VERSION ""

NS_ :

BS_:

BU_: Engine2 Aftertreatment_1_GasOutlet BrakesSystemController Transmission1 Engine1

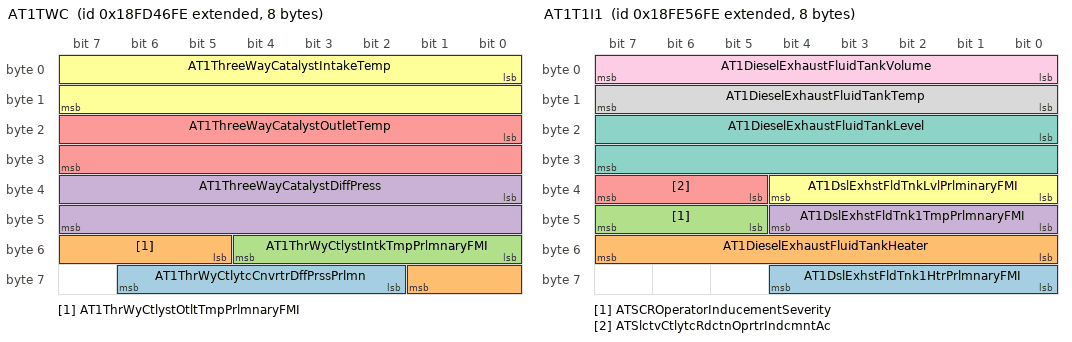
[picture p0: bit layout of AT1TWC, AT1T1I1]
BO_ 2566735614 AT1TWC: 8 Vector__XXX
 SG_ AT1ThrWyCtlytcCnvrtrDffPrssPrlmn : 58|5@1+ (1,0) [0|31] "" Vector__XXX
 SG_ AT1ThrWyCtlystOtltTmpPrlmnaryFMI : 53|5@1+ (1,0) [0|31] "" Vector__XXX
 SG_ AT1ThrWyCtlystIntkTmpPrlmnaryFMI : 48|5@1+ (1,0) [0|31] "" Vector__XXX
 SG_ AT1ThreeWayCatalystDiffPress : 32|16@1+ (0.1,0) [0|6425.5] "kPa" Vector__XXX
 SG_ AT1ThreeWayCatalystOutletTemp : 16|16@1+ (0.03125,-273) [-273|1734.96875] "°C" Vector__XXX
 SG_ AT1ThreeWayCatalystIntakeTemp : 0|16@1+ (0.03125,-273) [-273|1734.96875] "°C" Vector__XXX

BO_ 2566805246 AT1T1I1: 8 Vector__XXX
 SG_ AT1DslExhstFldTnk1HtrPrlmnaryFMI : 56|5@1+ (1,0) [0|31] "" Vector__XXX
 SG_ AT1DieselExhaustFluidTankHeater : 48|8@1+ (0.4,0) [0|100] "%" Vector__XXX
 SG_ ATSCROperatorInducementSeverity : 45|3@1+ (1,0) [0|7] "" Vector__XXX
 SG_ AT1DslExhstFldTnk1TmpPrlmnaryFMI : 40|5@1+ (1,0) [0|31] "" Vector__XXX
 SG_ ATSlctvCtlytcRdctnOprtrIndcmntAc : 37|3@1+ (1,0) [0|7] "" Vector__XXX
 SG_ AT1DslExhstFldTnkLvlPrlminaryFMI : 32|5@1+ (1,0) [0|31] "" Vector__XXX
 SG_ AT1DieselExhaustFluidTankLevel : 16|16@1+ (0.1,0) [0|6425.5] "mm" Vector__XXX
 SG_ AT1DieselExhaustFluidTankTemp : 8|8@1+ (1,-40) [-40|210] "°C" Vector__XXX
 SG_ AT1DieselExhaustFluidTankVolume : 0|8@1+ (0.4,0) [0|100] "%" Vector__XXX

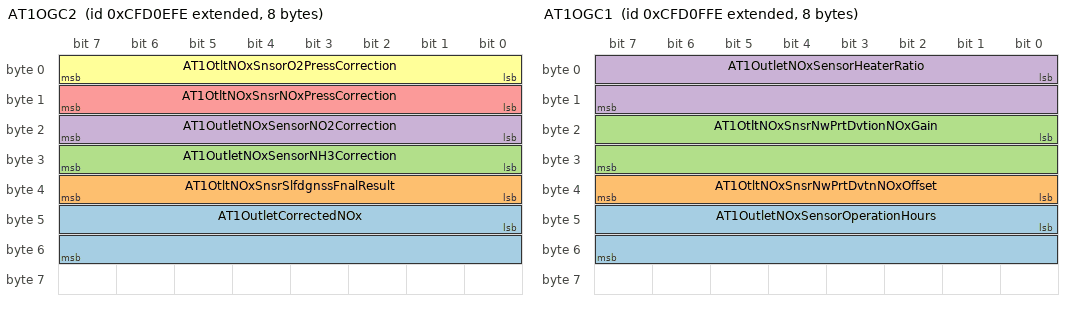
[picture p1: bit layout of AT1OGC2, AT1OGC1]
BO_ 2365394686 AT1OGC2: 8 Vector__XXX
 SG_ AT1OutletCorrectedNOx : 40|16@1+ (0.05,-200) [-200|3012.75] "ppm" Vector__XXX
 SG_ AT1OtltNOxSnsrSlfdgnssFnalResult : 32|8@1+ (1,0) [0|250] "" Vector__XXX
 SG_ AT1OutletNOxSensorNH3Correction : 24|8@1+ (0.5,0) [0|125] "%" Vector__XXX
 SG_ AT1OutletNOxSensorNO2Correction : 16|8@1+ (0.5,0) [0|125] "%" Vector__XXX
 SG_ AT1OtltNOxSnsrNOxPressCorrection : 8|8@1+ (0.5,0) [0|125] "%/bar" Vector__XXX
 SG_ AT1OtltNOxSnsorO2PressCorrection : 0|8@1+ (0.5,0) [0|125] "%/bar" Vector__XXX

BO_ 2365394942 AT1OGC1: 8 Vector__XXX
 SG_ AT1OutletNOxSensorOperationHours : 40|16@1+ (1,0) [0|64255] "h" Vector__XXX
 SG_ AT1OtltNOxSnsrNwPrtDvtnNOxOffset : 32|8@1+ (1,-125) [-125|125] "ppm" Vector__XXX
 SG_ AT1OtltNOxSnsrNwPrtDvtionNOxGain : 16|16@1+ (0.1,-100) [-100|100] "%" Vector__XXX
 SG_ AT1OutletNOxSensorHeaterRatio : 0|16@1+ (0.001,0) [0|64.255] "" Vector__XXX

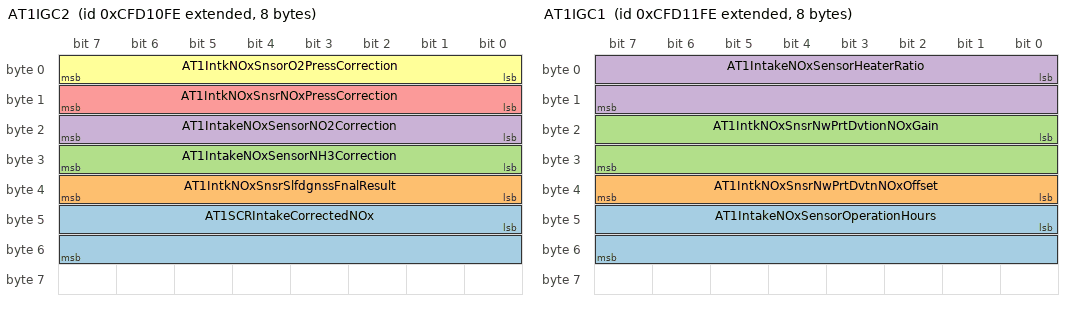
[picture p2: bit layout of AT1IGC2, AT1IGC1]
BO_ 2365395198 AT1IGC2: 8 Vector__XXX
 SG_ AT1SCRIntakeCorrectedNOx : 40|16@1+ (0.05,-200) [-200|3012.75] "ppm" Vector__XXX
 SG_ AT1IntkNOxSnsrSlfdgnssFnalResult : 32|8@1+ (1,0) [0|250] "" Vector__XXX
 SG_ AT1IntakeNOxSensorNH3Correction : 24|8@1+ (0.5,0) [0|125] "%" Vector__XXX
 SG_ AT1IntakeNOxSensorNO2Correction : 16|8@1+ (0.5,0) [0|125] "%" Vector__XXX
 SG_ AT1IntkNOxSnsrNOxPressCorrection : 8|8@1+ (0.5,0) [0|125] "%/bar" Vector__XXX
 SG_ AT1IntkNOxSnsorO2PressCorrection : 0|8@1+ (0.5,0) [0|125] "%/bar" Vector__XXX

BO_ 2365395454 AT1IGC1: 8 Vector__XXX
 SG_ AT1IntakeNOxSensorOperationHours : 40|16@1+ (1,0) [0|64255] "h" Vector__XXX
 SG_ AT1IntkNOxSnsrNwPrtDvtnNOxOffset : 32|8@1+ (1,-125) [-125|125] "ppm" Vector__XXX
 SG_ AT1IntkNOxSnsrNwPrtDvtionNOxGain : 16|16@1+ (0.1,-100) [-100|100] "%" Vector__XXX
 SG_ AT1IntakeNOxSensorHeaterRatio : 0|16@1+ (0.001,0) [0|64.255] "" Vector__XXX

BO_ 2157248254 AT1DPFSSC: 8 Vector__XXX
 SG_ AT1DslPrtcltFltrStStndrdDvtnClbO : 16|16@1+ (0.0025,0) [0|160.6375] "%" Vector__XXX
 SG_ AT1DslPrtcltFltrStManCalibOffset : 0|16@1+ (0.0025,0) [0|160.6375] "%" Vector__XXX

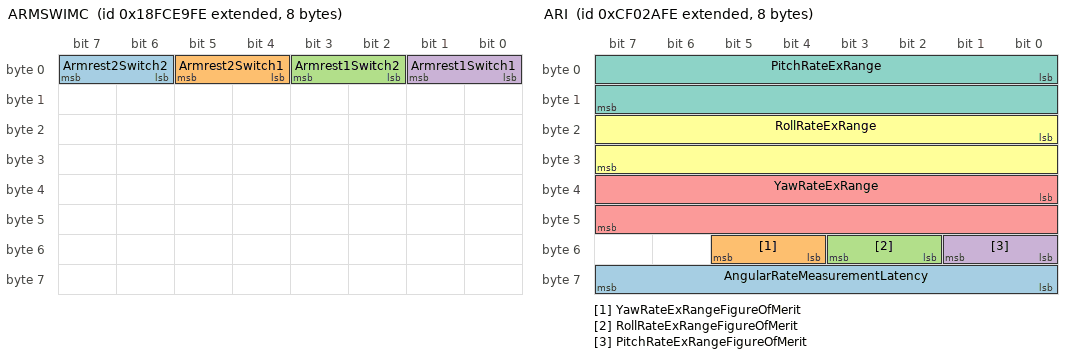
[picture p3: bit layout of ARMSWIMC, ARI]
BO_ 2566711806 ARMSWIMC: 8 Vector__XXX
 SG_ Armrest2Switch2 : 6|2@1+ (1,0) [0|3] "" Vector__XXX
 SG_ Armrest2Switch1 : 4|2@1+ (1,0) [0|3] "" Vector__XXX
 SG_ Armrest1Switch2 : 2|2@1+ (1,0) [0|3] "" Vector__XXX
 SG_ Armrest1Switch1 : 0|2@1+ (1,0) [0|3] "" Vector__XXX

BO_ 2364549886 ARI: 8 Vector__XXX
 SG_ AngularRateMeasurementLatency : 56|8@1+ (0.5,0) [0|125] "ms" Vector__XXX
 SG_ YawRateExRangeFigureOfMerit : 52|2@1+ (1,0) [0|3] "" Vector__XXX
 SG_ RollRateExRangeFigureOfMerit : 50|2@1+ (1,0) [0|3] "" Vector__XXX
 SG_ PitchRateExRangeFigureOfMerit : 48|2@1+ (1,0) [0|3] "" Vector__XXX
 SG_ YawRateExRange : 32|16@1+ (0.0078125,-250) [-250|250.992] "deg/s" Vector__XXX
 SG_ RollRateExRange : 16|16@1+ (0.0078125,-250) [-250|250.992] "deg/s" Vector__XXX
 SG_ PitchRateExRange : 0|16@1+ (0.0078125,-250) [-250|250.992] "deg/s" Vector__XXX

BO_ 2566712318 AFT2NAI: 8 Vector__XXX
 SG_ AT2NOxAdsorberDesulfationStatus : 2|2@1+ (1,0) [0|3] "" Vector__XXX
 SG_ AT2NOxAdsorberRegenerationStatus : 0|2@1+ (1,0) [0|3] "" Vector__XXX

BO_ 2566712574 AFT1NAI: 8 Vector__XXX
 SG_ AT1NOxAdsorberDesulfationStatus : 2|2@1+ (1,0) [0|3] "" Vector__XXX
 SG_ AT1NOxAdsorberRegenerationStatus : 0|2@1+ (1,0) [0|3] "" Vector__XXX

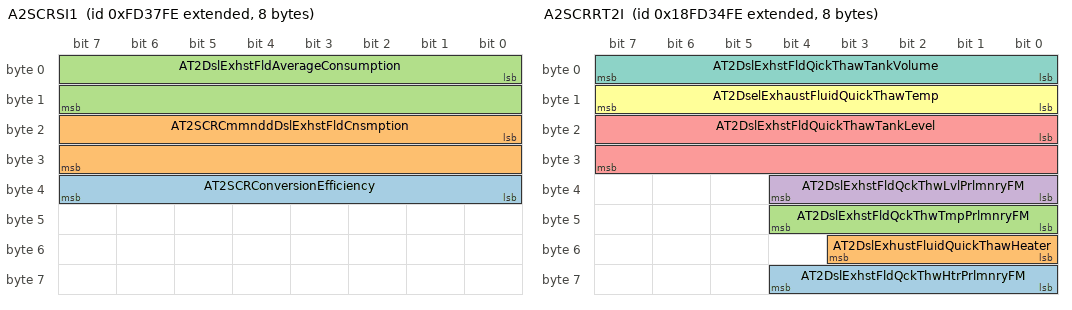
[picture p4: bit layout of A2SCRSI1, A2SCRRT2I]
BO_ 2164078590 A2SCRSI1: 8 Vector__XXX
 SG_ AT2SCRConversionEfficiency : 32|8@1+ (0.4,0) [0|100] "%" Vector__XXX
 SG_ AT2SCRCmmnddDslExhstFldCnsmption : 16|16@1+ (0.05,0) [0|3212.75] "L/h" Vector__XXX
 SG_ AT2DslExhstFldAverageConsumption : 0|16@1+ (0.05,0) [0|3212.75] "L/h" Vector__XXX

BO_ 2566731006 A2SCRRT2I: 8 Vector__XXX
 SG_ AT2DslExhstFldQckThwHtrPrlmnryFM : 56|5@1+ (1,0) [0|31] "" Vector__XXX
 SG_ AT2DslExhustFluidQuickThawHeater : 48|4@1+ (1,0) [0|15] "" Vector__XXX
 SG_ AT2DslExhstFldQckThwTmpPrlmnryFM : 40|5@1+ (1,0) [0|31] "" Vector__XXX
 SG_ AT2DslExhstFldQckThwLvlPrlmnryFM : 32|5@1+ (1,0) [0|31] "" Vector__XXX
 SG_ AT2DslExhstFldQuickThawTankLevel : 16|16@1+ (0.1,0) [0|6425.5] "mm" Vector__XXX
 SG_ AT2DselExhaustFluidQuickThawTemp : 8|8@1+ (1,-40) [-40|210] "°C" Vector__XXX
 SG_ AT2DslExhstFldQickThawTankVolume : 0|8@1+ (0.4,0) [0|100] "%" Vector__XXX

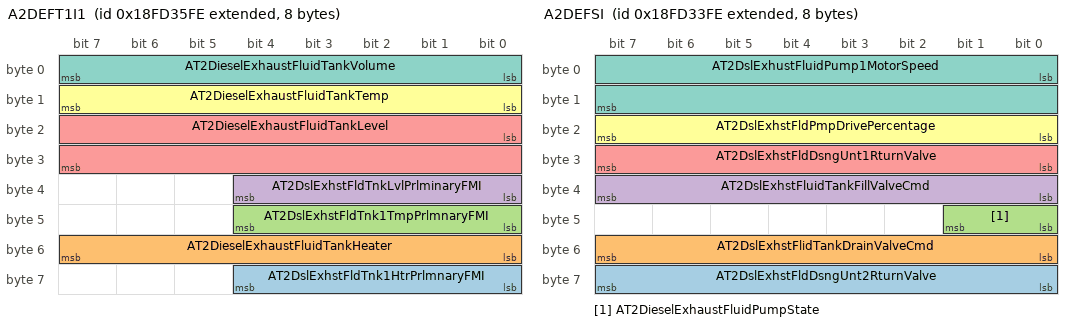
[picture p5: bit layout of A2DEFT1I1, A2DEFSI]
BO_ 2566731262 A2DEFT1I1: 8 Vector__XXX
 SG_ AT2DslExhstFldTnk1HtrPrlmnaryFMI : 56|5@1+ (1,0) [0|31] "" Vector__XXX
 SG_ AT2DieselExhaustFluidTankHeater : 48|8@1+ (0.4,0) [0|100] "%" Vector__XXX
 SG_ AT2DslExhstFldTnk1TmpPrlmnaryFMI : 40|5@1+ (1,0) [0|31] "" Vector__XXX
 SG_ AT2DslExhstFldTnkLvlPrlminaryFMI : 32|5@1+ (1,0) [0|31] "" Vector__XXX
 SG_ AT2DieselExhaustFluidTankLevel : 16|16@1+ (0.1,0) [0|6425.5] "mm" Vector__XXX
 SG_ AT2DieselExhaustFluidTankTemp : 8|8@1+ (1,-40) [-40|210] "°C" Vector__XXX
 SG_ AT2DieselExhaustFluidTankVolume : 0|8@1+ (0.4,0) [0|100] "%" Vector__XXX

BO_ 2566730750 A2DEFSI: 8 Vector__XXX
 SG_ AT2DslExhstFldDsngUnt2RturnValve : 56|8@1+ (0.4,0) [0|100] "%" Vector__XXX
 SG_ AT2DslExhstFlidTankDrainValveCmd : 48|8@1+ (0.4,0) [0|100] "%" Vector__XXX
 SG_ AT2DieselExhaustFluidPumpState : 40|2@1+ (1,0) [0|3] "" Vector__XXX
 SG_ AT2DslExhstFluidTankFillValveCmd : 32|8@1+ (0.4,0) [0|100] "%" Vector__XXX
 SG_ AT2DslExhstFldDsngUnt1RturnValve : 24|8@1+ (0.4,0) [0|100] "%" Vector__XXX
 SG_ AT2DslExhstFldPmpDrivePercentage : 16|8@1+ (0.4,0) [0|100] "%" Vector__XXX
 SG_ AT2DslExhustFluidPump1MotorSpeed : 0|16@1+ (0.5,0) [0|32127.5] "rpm" Vector__XXX

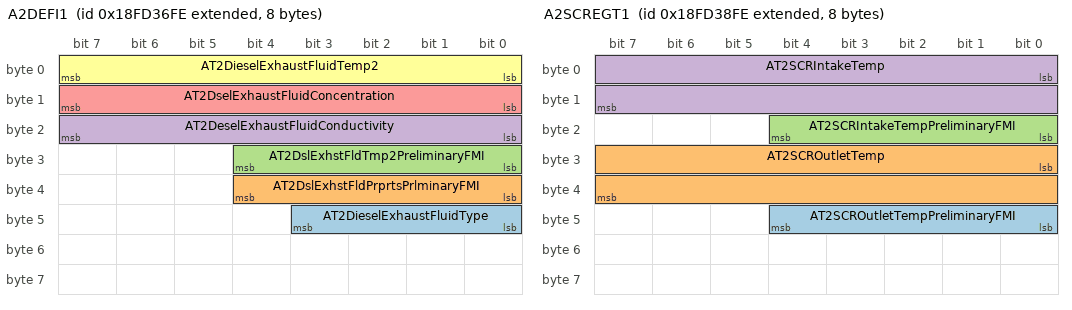
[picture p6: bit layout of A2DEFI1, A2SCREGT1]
BO_ 2566731518 A2DEFI1: 8 Vector__XXX
 SG_ AT2DieselExhaustFluidType : 40|4@1+ (1,0) [0|15] "" Vector__XXX
 SG_ AT2DslExhstFldPrprtsPrlminaryFMI : 32|5@1+ (1,0) [0|31] "" Vector__XXX
 SG_ AT2DslExhstFldTmp2PreliminaryFMI : 24|5@1+ (1,0) [0|31] "" Vector__XXX
 SG_ AT2DeselExhaustFluidConductivity : 16|8@1+ (5,0) [0|1250] "µSiemens/mm" Vector__XXX
 SG_ AT2DselExhaustFluidConcentration : 8|8@1+ (0.25,0) [0|62.5] "%" Vector__XXX
 SG_ AT2DieselExhaustFluidTemp2 : 0|8@1+ (1,-40) [-40|210] "°C" Vector__XXX

BO_ 2566732030 A2SCREGT1: 8 Vector__XXX
 SG_ AT2SCROutletTempPreliminaryFMI : 40|5@1+ (1,0) [0|31] "" Vector__XXX
 SG_ AT2SCROutletTemp : 24|16@1+ (0.03125,-273) [-273|1734.96875] "°C" Vector__XXX
 SG_ AT2SCRIntakeTempPreliminaryFMI : 16|5@1+ (1,0) [0|31] "" Vector__XXX
 SG_ AT2SCRIntakeTemp : 0|16@1+ (0.03125,-273) [-273|1734.96875] "°C" Vector__XXX

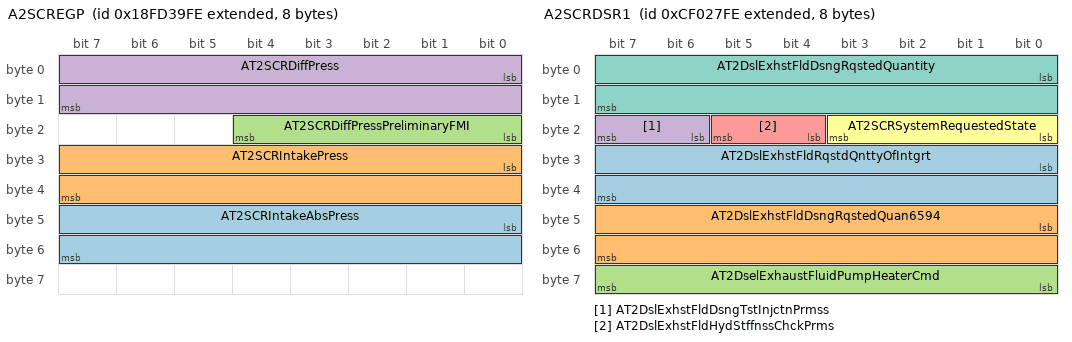
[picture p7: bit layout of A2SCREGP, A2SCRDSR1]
BO_ 2566732286 A2SCREGP: 8 Vector__XXX
 SG_ AT2SCRIntakeAbsPress : 40|16@1+ (0.1,0) [0|6425.5] "kPa" Vector__XXX
 SG_ AT2SCRIntakePress : 24|16@1+ (0.1,-3212.7) [-3212.7|3212.8] "kPa" Vector__XXX
 SG_ AT2SCRDiffPressPreliminaryFMI : 16|5@1+ (1,0) [0|31] "" Vector__XXX
 SG_ AT2SCRDiffPress : 0|16@1+ (0.1,0) [0|6425.5] "kPa" Vector__XXX

BO_ 2164079358 A2SCRDSR2: 8 Vector__XXX
 SG_ AT2DeselExhaustFluidLineHeater10 : 48|2@1+ (1,0) [0|3] "" Vector__XXX
 SG_ AT2DieselExhaustFluidLineHeater9 : 46|2@1+ (1,0) [0|3] "" Vector__XXX
 SG_ AT2DieselExhaustFluidLineHeater8 : 44|2@1+ (1,0) [0|3] "" Vector__XXX
 SG_ AT2DieselExhaustFluidLineHeater7 : 42|2@1+ (1,0) [0|3] "" Vector__XXX
 SG_ AT2DieselExhaustFluidLineHeater6 : 40|2@1+ (1,0) [0|3] "" Vector__XXX
 SG_ AT2DieselExhaustFluidLineHeater5 : 38|2@1+ (1,0) [0|3] "" Vector__XXX
 SG_ AT2DslExhstFluidLineHeaterRelay3 : 36|2@1+ (1,0) [0|3] "" Vector__XXX
 SG_ AT2DslExhstFluidLineHeaterRelay2 : 34|2@1+ (1,0) [0|3] "" Vector__XXX
 SG_ AT2DslExhstFluidLineHeaterRelay1 : 32|2@1+ (1,0) [0|3] "" Vector__XXX
 SG_ AT2DslExhstFldQuickThawHeaterCmd : 24|8@1+ (0.4,0) [0|100] "%" Vector__XXX
 SG_ AT2DselExhaustFluidTankHeaterCmd : 16|8@1+ (0.4,0) [0|100] "%" Vector__XXX
 SG_ AT2DieselExhaustFluidLineHeater4 : 14|2@1+ (1,0) [0|3] "" Vector__XXX
 SG_ AT2DieselExhaustFluidLineHeater3 : 12|2@1+ (1,0) [0|3] "" Vector__XXX
 SG_ AT2DieselExhaustFluidLineHeater2 : 10|2@1+ (1,0) [0|3] "" Vector__XXX
 SG_ AT2DieselExhaustFluidLineHeater1 : 8|2@1+ (1,0) [0|3] "" Vector__XXX
 SG_ AT2DslExhstFldDoserHeatingModeRq : 4|3@1+ (1,0) [0|7] "" Vector__XXX
 SG_ AT2DslExhstFldDsrFltSppressionRq : 2|2@1+ (1,0) [0|3] "" Vector__XXX

BO_ 2364549118 A2SCRDSR1: 8 Vector__XXX
 SG_ AT2DslExhstFldRqstdQnttyOfIntgrt : 24|16@1+ (0.1,0) [0|6425.5] "g" Vector__XXX
 SG_ AT2DslExhstFldDsngRqstedQuan6594 : 40|16@1+ (0.05,0) [0|3212.75] "g/min" Vector__XXX
 SG_ AT2DselExhaustFluidPumpHeaterCmd : 56|8@1+ (0.4,0) [0|100] "%" Vector__XXX
 SG_ AT2DslExhstFldDsngTstInjctnPrmss : 22|2@1+ (1,0) [0|3] "" Vector__XXX
 SG_ AT2DslExhstFldHydStffnssChckPrms : 20|2@1+ (1,0) [0|3] "" Vector__XXX
 SG_ AT2SCRSystemRequestedState : 16|4@1+ (1,0) [0|15] "" Vector__XXX
 SG_ AT2DslExhstFldDsngRqstedQuantity : 0|16@1+ (0.3,0) [0|19276.5] "g/h" Vector__XXX

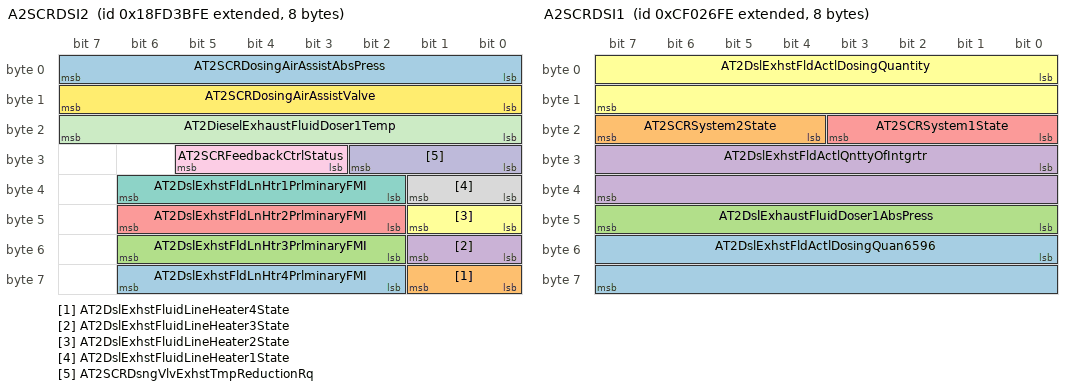
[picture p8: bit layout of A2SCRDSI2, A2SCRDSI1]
BO_ 2566732798 A2SCRDSI2: 8 Vector__XXX
 SG_ AT2DslExhstFldLnHtr4PrlminaryFMI : 58|5@1+ (1,0) [0|31] "" Vector__XXX
 SG_ AT2DslExhstFluidLineHeater4State : 56|2@1+ (1,0) [0|3] "" Vector__XXX
 SG_ AT2DslExhstFldLnHtr3PrlminaryFMI : 50|5@1+ (1,0) [0|31] "" Vector__XXX
 SG_ AT2DslExhstFluidLineHeater3State : 48|2@1+ (1,0) [0|3] "" Vector__XXX
 SG_ AT2DslExhstFldLnHtr2PrlminaryFMI : 42|5@1+ (1,0) [0|31] "" Vector__XXX
 SG_ AT2DslExhstFluidLineHeater2State : 40|2@1+ (1,0) [0|3] "" Vector__XXX
 SG_ AT2DslExhstFldLnHtr1PrlminaryFMI : 34|5@1+ (1,0) [0|31] "" Vector__XXX
 SG_ AT2DslExhstFluidLineHeater1State : 32|2@1+ (1,0) [0|3] "" Vector__XXX
 SG_ AT2SCRFeedbackCtrlStatus : 27|3@1+ (1,0) [0|7] "" Vector__XXX
 SG_ AT2SCRDsngVlvExhstTmpReductionRq : 24|3@1+ (1,0) [0|7] "" Vector__XXX
 SG_ AT2DieselExhaustFluidDoser1Temp : 16|8@1+ (1,-40) [-40|210] "°C" Vector__XXX
 SG_ AT2SCRDosingAirAssistValve : 8|8@1+ (0.4,0) [0|100] "%" Vector__XXX
 SG_ AT2SCRDosingAirAssistAbsPress : 0|8@1+ (8,0) [0|2000] "kPa" Vector__XXX

BO_ 2364548862 A2SCRDSI1: 8 Vector__XXX
 SG_ AT2DslExhstFldActlDosingQuan6596 : 48|16@1+ (0.05,0) [0|3212.75] "g/min" Vector__XXX
 SG_ AT2SCRSystem2State : 20|4@1+ (1,0) [0|15] "" Vector__XXX
 SG_ AT2DslExhaustFluidDoser1AbsPress : 40|8@1+ (8,0) [0|2000] "kPa" Vector__XXX
 SG_ AT2DslExhstFldActlQnttyOfIntgrtr : 24|16@1+ (0.1,0) [0|6425.5] "g" Vector__XXX
 SG_ AT2SCRSystem1State : 16|4@1+ (1,0) [0|15] "" Vector__XXX
 SG_ AT2DslExhstFldActlDosingQuantity : 0|16@1+ (0.3,0) [0|19276.5] "g/h" Vector__XXX

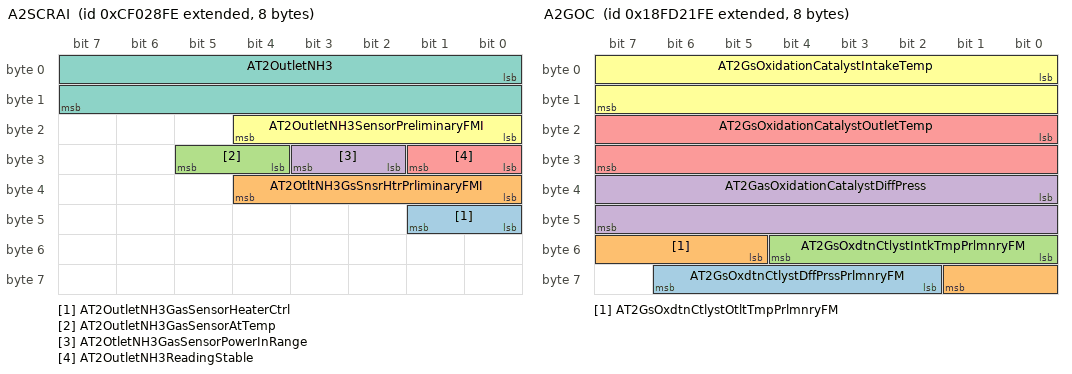
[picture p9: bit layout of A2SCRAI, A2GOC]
BO_ 2364549374 A2SCRAI: 8 Vector__XXX
 SG_ AT2OutletNH3GasSensorHeaterCtrl : 40|2@1+ (1,0) [0|3] "" Vector__XXX
 SG_ AT2OtltNH3GsSnsrHtrPrliminaryFMI : 32|5@1+ (1,0) [0|31] "" Vector__XXX
 SG_ AT2OutletNH3GasSensorAtTemp : 28|2@1+ (1,0) [0|3] "" Vector__XXX
 SG_ AT2OtletNH3GasSensorPowerInRange : 26|2@1+ (1,0) [0|3] "" Vector__XXX
 SG_ AT2OutletNH3ReadingStable : 24|2@1+ (1,0) [0|3] "" Vector__XXX
 SG_ AT2OutletNH3SensorPreliminaryFMI : 16|5@1+ (1,0) [0|31] "" Vector__XXX
 SG_ AT2OutletNH3 : 0|16@1+ (0.05,-200) [-200|3012.75] "ppm" Vector__XXX

BO_ 2566726142 A2GOC: 8 Vector__XXX
 SG_ AT2GsOxdtnCtlystDffPrssPrlmnryFM : 58|5@1+ (1,0) [0|31] "" Vector__XXX
 SG_ AT2GsOxdtnCtlystOtltTmpPrlmnryFM : 53|5@1+ (1,0) [0|31] "" Vector__XXX
 SG_ AT2GsOxdtnCtlystIntkTmpPrlmnryFM : 48|5@1+ (1,0) [0|31] "" Vector__XXX
 SG_ AT2GasOxidationCatalystDiffPress : 32|16@1+ (0.1,0) [0|6425.5] "kPa" Vector__XXX
 SG_ AT2GsOxidationCatalystOutletTemp : 16|16@1+ (0.03125,-273) [-273|1734.96875] "°C" Vector__XXX
 SG_ AT2GsOxidationCatalystIntakeTemp : 0|16@1+ (0.03125,-273) [-273|1734.96875] "°C" Vector__XXX

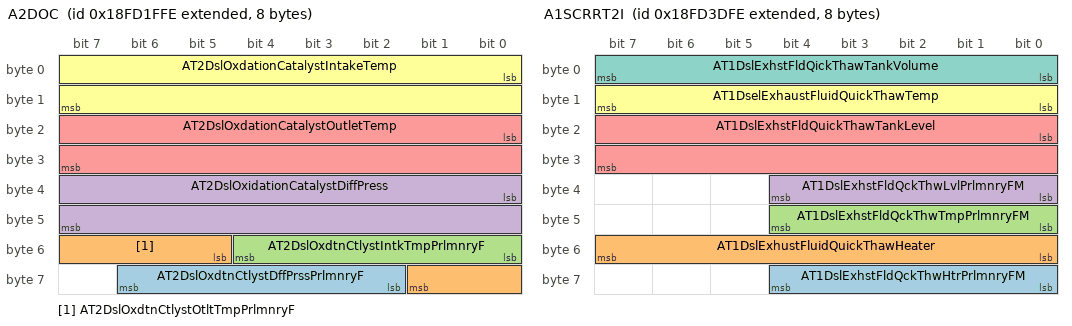
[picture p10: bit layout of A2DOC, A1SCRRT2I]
BO_ 2566725630 A2DOC: 8 Vector__XXX
 SG_ AT2DslOxdtnCtlystDffPrssPrlmnryF : 58|5@1+ (1,0) [0|31] "" Vector__XXX
 SG_ AT2DslOxdtnCtlystOtltTmpPrlmnryF : 53|5@1+ (1,0) [0|31] "" Vector__XXX
 SG_ AT2DslOxdtnCtlystIntkTmpPrlmnryF : 48|5@1+ (1,0) [0|31] "" Vector__XXX
 SG_ AT2DslOxidationCatalystDiffPress : 32|16@1+ (0.5,0) [0|32127.5] "kPa" Vector__XXX
 SG_ AT2DslOxdationCatalystOutletTemp : 16|16@1+ (0.03125,-273) [-273|1734.96875] "°C" Vector__XXX
 SG_ AT2DslOxdationCatalystIntakeTemp : 0|16@1+ (0.03125,-273) [-273|1734.96875] "°C" Vector__XXX

BO_ 2566733310 A1SCRRT2I: 8 Vector__XXX
 SG_ AT1DslExhstFldQckThwHtrPrlmnryFM : 56|5@1+ (1,0) [0|31] "" Vector__XXX
 SG_ AT1DslExhustFluidQuickThawHeater : 48|8@1+ (0.4,0) [0|100] "%" Vector__XXX
 SG_ AT1DslExhstFldQckThwTmpPrlmnryFM : 40|5@1+ (1,0) [0|31] "" Vector__XXX
 SG_ AT1DslExhstFldQckThwLvlPrlmnryFM : 32|5@1+ (1,0) [0|31] "" Vector__XXX
 SG_ AT1DslExhstFldQuickThawTankLevel : 16|16@1+ (0.1,0) [0|6425.5] "mm" Vector__XXX
 SG_ AT1DselExhaustFluidQuickThawTemp : 8|8@1+ (1,-40) [-40|210] "°C" Vector__XXX
 SG_ AT1DslExhstFldQickThawTankVolume : 0|8@1+ (0.4,0) [0|100] "%" Vector__XXX

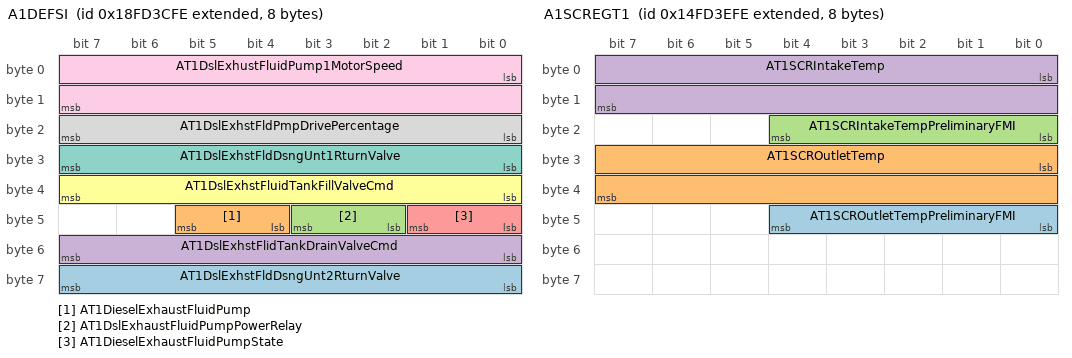
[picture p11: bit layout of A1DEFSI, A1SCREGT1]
BO_ 2566733054 A1DEFSI: 8 Vector__XXX
 SG_ AT1DslExhstFldDsngUnt2RturnValve : 56|8@1+ (0.4,0) [0|100] "%" Vector__XXX
 SG_ AT1DieselExhaustFluidPump : 44|2@1+ (1,0) [0|3] "" Vector__XXX
 SG_ AT1DslExhaustFluidPumpPowerRelay : 42|2@1+ (1,0) [0|3] "" Vector__XXX
 SG_ AT1DslExhstFlidTankDrainValveCmd : 48|8@1+ (0.4,0) [0|100] "%" Vector__XXX
 SG_ AT1DieselExhaustFluidPumpState : 40|2@1+ (1,0) [0|3] "" Vector__XXX
 SG_ AT1DslExhstFluidTankFillValveCmd : 32|8@1+ (0.4,0) [0|100] "%" Vector__XXX
 SG_ AT1DslExhstFldDsngUnt1RturnValve : 24|8@1+ (0.4,0) [0|100] "%" Vector__XXX
 SG_ AT1DslExhstFldPmpDrivePercentage : 16|8@1+ (0.4,0) [0|100] "%" Vector__XXX
 SG_ AT1DslExhustFluidPump1MotorSpeed : 0|16@1+ (0.5,0) [0|32127.5] "rpm" Vector__XXX

BO_ 2499624702 A1SCREGT1: 8 Vector__XXX
 SG_ AT1SCROutletTempPreliminaryFMI : 40|5@1+ (1,0) [0|31] "" Vector__XXX
 SG_ AT1SCROutletTemp : 24|16@1+ (0.03125,-273) [-273|1734.96875] "°C" Vector__XXX
 SG_ AT1SCRIntakeTempPreliminaryFMI : 16|5@1+ (1,0) [0|31] "" Vector__XXX
 SG_ AT1SCRIntakeTemp : 0|16@1+ (0.03125,-273) [-273|1734.96875] "°C" Vector__XXX

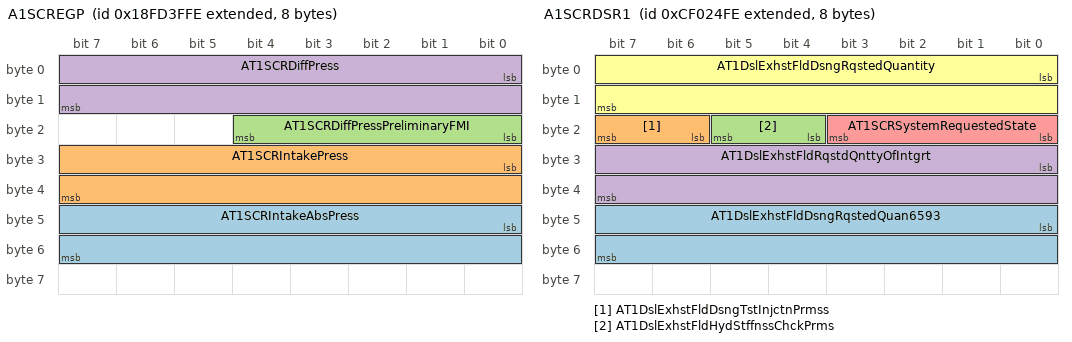
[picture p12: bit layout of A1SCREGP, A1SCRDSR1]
BO_ 2566733822 A1SCREGP: 8 Vector__XXX
 SG_ AT1SCRIntakeAbsPress : 40|16@1+ (0.1,0) [0|6425.5] "kPa" Vector__XXX
 SG_ AT1SCRIntakePress : 24|16@1+ (0.1,-3212.7) [-3212.7|3212.8] "kPa" Vector__XXX
 SG_ AT1SCRDiffPressPreliminaryFMI : 16|5@1+ (1,0) [0|31] "" Vector__XXX
 SG_ AT1SCRDiffPress : 0|16@1+ (0.1,0) [0|6425.5] "kPa" Vector__XXX

BO_ 2566734078 A1SCRDSR2: 8 Vector__XXX
 SG_ AT1DeselExhaustFluidLineHeater10 : 56|2@1+ (1,0) [0|3] "" Vector__XXX
 SG_ AT1DieselExhaustFluidLineHeater9 : 54|2@1+ (1,0) [0|3] "" Vector__XXX
 SG_ AT1DieselExhaustFluidLineHeater8 : 52|2@1+ (1,0) [0|3] "" Vector__XXX
 SG_ AT1DieselExhaustFluidLineHeater7 : 50|2@1+ (1,0) [0|3] "" Vector__XXX
 SG_ AT1DieselExhaustFluidLineHeater6 : 48|2@1+ (1,0) [0|3] "" Vector__XXX
 SG_ AT1DieselExhaustFluidLineHeater5 : 46|2@1+ (1,0) [0|3] "" Vector__XXX
 SG_ AT1DslExhstFluidLineHeaterRelay3 : 44|2@1+ (1,0) [0|3] "" Vector__XXX
 SG_ AT1DslExhstFluidLineHeaterRelay2 : 42|2@1+ (1,0) [0|3] "" Vector__XXX
 SG_ AT1DslExhstFluidLineHeaterRelay1 : 40|2@1+ (1,0) [0|3] "" Vector__XXX
 SG_ AT1DselExhaustFluidPumpHeaterCmd : 32|8@1+ (0.4,0) [0|100] "%" Vector__XXX
 SG_ AT1DslExhstFldQuickThawHeaterCmd : 24|8@1+ (0.4,0) [0|100] "%" Vector__XXX
 SG_ AT1DselExhaustFluidTankHeaterCmd : 16|8@1+ (0.4,0) [0|100] "%" Vector__XXX
 SG_ AT1DieselExhaustFluidLineHeater4 : 14|2@1+ (1,0) [0|3] "" Vector__XXX
 SG_ AT1DieselExhaustFluidLineHeater3 : 12|2@1+ (1,0) [0|3] "" Vector__XXX
 SG_ AT1DieselExhaustFluidLineHeater2 : 10|2@1+ (1,0) [0|3] "" Vector__XXX
 SG_ AT1DieselExhaustFluidLineHeater1 : 8|2@1+ (1,0) [0|3] "" Vector__XXX
 SG_ AT1DslExhstFldDoserHeatingModeRq : 4|3@1+ (1,0) [0|7] "" Vector__XXX
 SG_ AT1DslExhstFldDsrFltSppressionRq : 2|2@1+ (1,0) [0|3] "" Vector__XXX

BO_ 2364548350 A1SCRDSR1: 8 Vector__XXX
 SG_ AT1DslExhstFldDsngRqstedQuan6593 : 40|16@1+ (0.05,0) [0|3212.75] "g/min" Vector__XXX
 SG_ AT1DslExhstFldDsngTstInjctnPrmss : 22|2@1+ (1,0) [0|3] "" Vector__XXX
 SG_ AT1DslExhstFldHydStffnssChckPrms : 20|2@1+ (1,0) [0|3] "" Vector__XXX
 SG_ AT1DslExhstFldRqstdQnttyOfIntgrt : 24|16@1+ (0.1,0) [0|6425.5] "g" Vector__XXX
 SG_ AT1SCRSystemRequestedState : 16|4@1+ (1,0) [0|15] "" Vector__XXX
 SG_ AT1DslExhstFldDsngRqstedQuantity : 0|16@1+ (0.3,0) [0|19276.5] "g/h" Vector__XXX

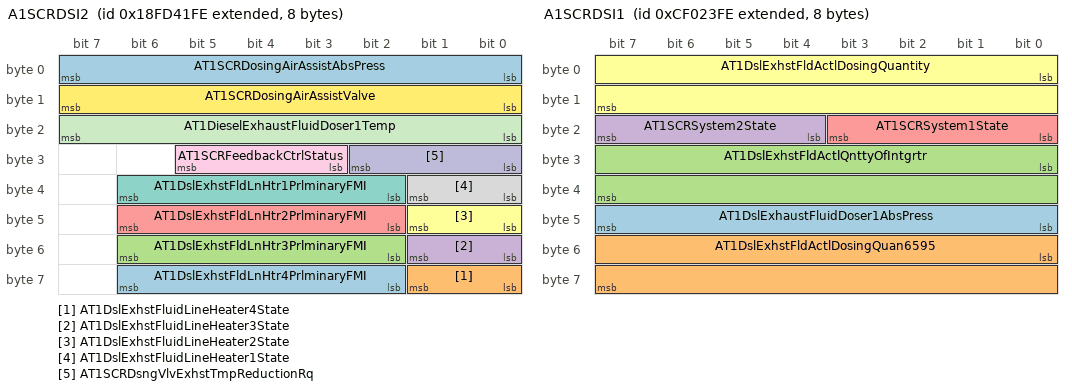
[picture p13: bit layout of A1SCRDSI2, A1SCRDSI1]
BO_ 2566734334 A1SCRDSI2: 8 Vector__XXX
 SG_ AT1DslExhstFldLnHtr4PrlminaryFMI : 58|5@1+ (1,0) [0|31] "" Vector__XXX
 SG_ AT1DslExhstFluidLineHeater4State : 56|2@1+ (1,0) [0|3] "" Vector__XXX
 SG_ AT1DslExhstFldLnHtr3PrlminaryFMI : 50|5@1+ (1,0) [0|31] "" Vector__XXX
 SG_ AT1DslExhstFluidLineHeater3State : 48|2@1+ (1,0) [0|3] "" Vector__XXX
 SG_ AT1DslExhstFldLnHtr2PrlminaryFMI : 42|5@1+ (1,0) [0|31] "" Vector__XXX
 SG_ AT1DslExhstFluidLineHeater2State : 40|2@1+ (1,0) [0|3] "" Vector__XXX
 SG_ AT1DslExhstFldLnHtr1PrlminaryFMI : 34|5@1+ (1,0) [0|31] "" Vector__XXX
 SG_ AT1DslExhstFluidLineHeater1State : 32|2@1+ (1,0) [0|3] "" Vector__XXX
 SG_ AT1SCRFeedbackCtrlStatus : 27|3@1+ (1,0) [0|7] "" Vector__XXX
 SG_ AT1SCRDsngVlvExhstTmpReductionRq : 24|3@1+ (1,0) [0|7] "" Vector__XXX
 SG_ AT1DieselExhaustFluidDoser1Temp : 16|8@1+ (1,-40) [-40|210] "°C" Vector__XXX
 SG_ AT1SCRDosingAirAssistValve : 8|8@1+ (0.4,0) [0|100] "%" Vector__XXX
 SG_ AT1SCRDosingAirAssistAbsPress : 0|8@1+ (8,0) [0|2000] "kPa" Vector__XXX

BO_ 2364548094 A1SCRDSI1: 8 Vector__XXX
 SG_ AT1DslExhaustFluidDoser1AbsPress : 40|8@1+ (8,0) [0|2000] "kPa" Vector__XXX
 SG_ AT1DslExhstFldActlDosingQuan6595 : 48|16@1+ (0.05,0) [0|3212.75] "g/min" Vector__XXX
 SG_ AT1DslExhstFldActlQnttyOfIntgrtr : 24|16@1+ (0.1,0) [0|6425.5] "g" Vector__XXX
 SG_ AT1SCRSystem2State : 20|4@1+ (1,0) [0|15] "" Vector__XXX
 SG_ AT1SCRSystem1State : 16|4@1+ (1,0) [0|15] "" Vector__XXX
 SG_ AT1DslExhstFldActlDosingQuantity : 0|16@1+ (0.3,0) [0|19276.5] "g/h" Vector__XXX

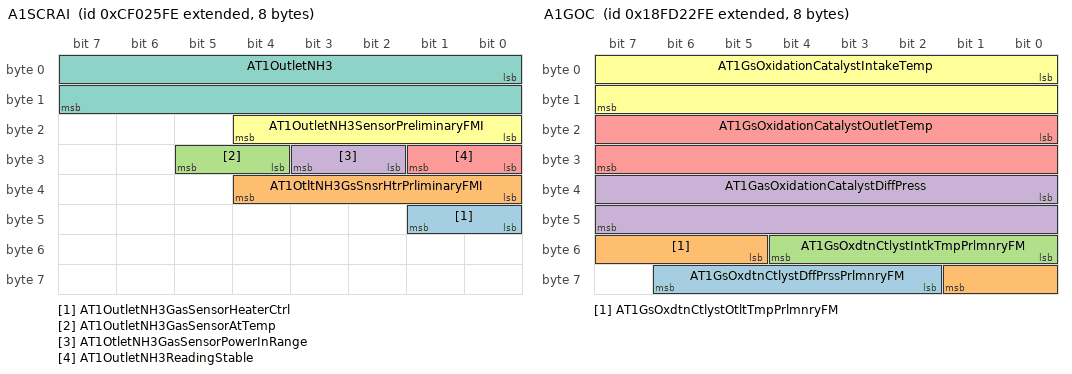
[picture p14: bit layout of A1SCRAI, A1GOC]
BO_ 2364548606 A1SCRAI: 8 Vector__XXX
 SG_ AT1OutletNH3GasSensorHeaterCtrl : 40|2@1+ (1,0) [0|3] "" Vector__XXX
 SG_ AT1OtltNH3GsSnsrHtrPrliminaryFMI : 32|5@1+ (1,0) [0|31] "" Vector__XXX
 SG_ AT1OutletNH3GasSensorAtTemp : 28|2@1+ (1,0) [0|3] "" Vector__XXX
 SG_ AT1OtletNH3GasSensorPowerInRange : 26|2@1+ (1,0) [0|3] "" Vector__XXX
 SG_ AT1OutletNH3ReadingStable : 24|2@1+ (1,0) [0|3] "" Vector__XXX
 SG_ AT1OutletNH3SensorPreliminaryFMI : 16|5@1+ (1,0) [0|31] "" Vector__XXX
 SG_ AT1OutletNH3 : 0|16@1+ (0.05,-200) [-200|3012.75] "ppm" Vector__XXX

BO_ 2566726398 A1GOC: 8 Vector__XXX
 SG_ AT1GsOxdtnCtlystDffPrssPrlmnryFM : 58|5@1+ (1,0) [0|31] "" Vector__XXX
 SG_ AT1GsOxdtnCtlystOtltTmpPrlmnryFM : 53|5@1+ (1,0) [0|31] "" Vector__XXX
 SG_ AT1GsOxdtnCtlystIntkTmpPrlmnryFM : 48|5@1+ (1,0) [0|31] "" Vector__XXX
 SG_ AT1GasOxidationCatalystDiffPress : 32|16@1+ (0.1,0) [0|6425.5] "kPa" Vector__XXX
 SG_ AT1GsOxidationCatalystOutletTemp : 16|16@1+ (0.03125,-273) [-273|1734.96875] "°C" Vector__XXX
 SG_ AT1GsOxidationCatalystIntakeTemp : 0|16@1+ (0.03125,-273) [-273|1734.96875] "°C" Vector__XXX

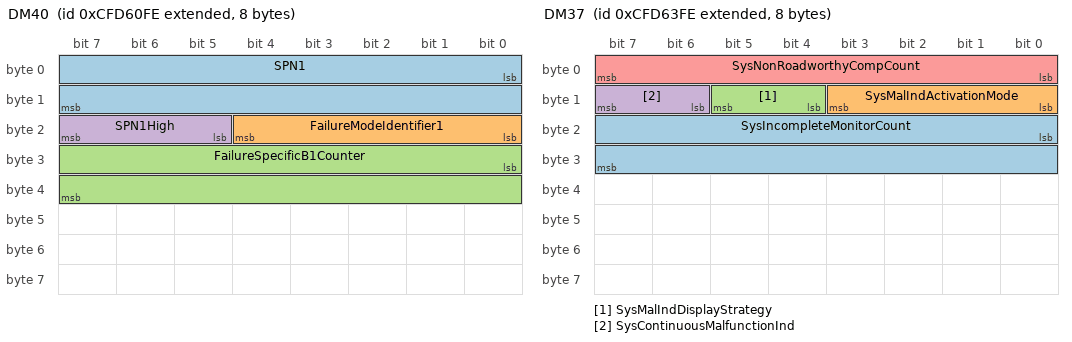
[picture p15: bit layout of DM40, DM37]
BO_ 2365415678 DM40: 8 Vector__XXX
 SG_ SPN1 : 0|16@1+ (1,0) [0|65536] "" Vector__XXX
 SG_ FailureModeIdentifier1 : 16|5@1+ (1,0) [0|0] "" Vector__XXX
 SG_ FailureSpecificB1Counter : 24|16@1+ (0.1,0) [0|6425.5] "hr" Vector__XXX
 SG_ SPN1High : 21|3@1+ (1,0) [0|7] "" Vector__XXX

BO_ 2365415934 DM39: 8 Vector__XXX
 SG_ SysGreatestB1Counter : 32|16@1+ (0.1,0) [0|6425.5] "hr" Vector__XXX
 SG_ SysCumulativeContinuousMITime : 0|32@1+ (0.05,0) [0|210554060.75] "hr" Vector__XXX

BO_ 2365416190 DM38: 8 Vector__XXX
 SG_ RegulationDescription : 0|8@1+ (1,0) [0|255] "" Vector__XXX

BO_ 2365416446 DM37: 8 Vector__XXX
 SG_ SysIncompleteMonitorCount : 16|16@1+ (1,0) [0|64512] "" Vector__XXX
 SG_ SysMalIndActivationMode : 8|4@1+ (1,0) [0|15] "" Vector__XXX
 SG_ SysMalIndDisplayStrategy : 12|2@1+ (1,0) [0|3] "" Vector__XXX
 SG_ SysContinuousMalfunctionInd : 14|2@1+ (1,0) [0|3] "" Vector__XXX
 SG_ SysNonRoadworthyCompCount : 0|8@1+ (1,0) [0|250] "" Vector__XXX

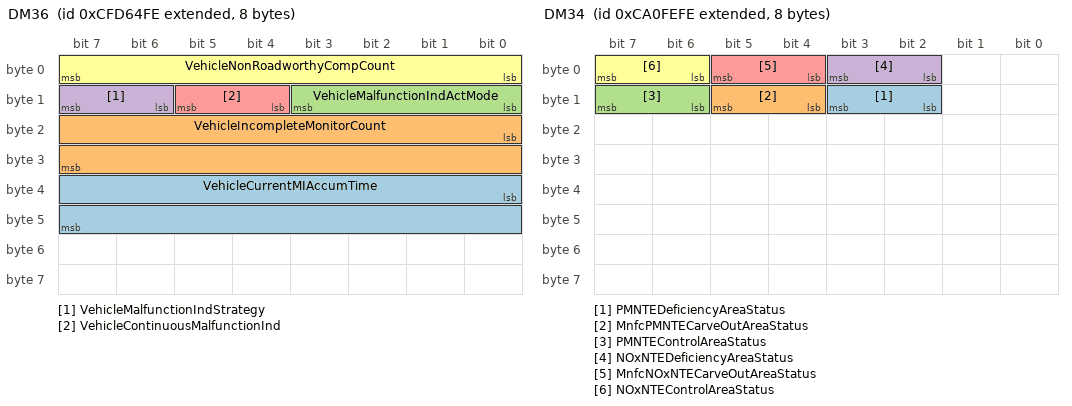
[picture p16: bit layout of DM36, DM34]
BO_ 2365416702 DM36: 8 Vector__XXX
 SG_ VehicleCurrentMIAccumTime : 32|16@1+ (1,0) [0|64255] "min" Vector__XXX
 SG_ VehicleIncompleteMonitorCount : 16|16@1+ (1,0) [0|64255] "" Vector__XXX
 SG_ VehicleMalfunctionIndActMode : 8|4@1+ (1,0) [0|15] "" Vector__XXX
 SG_ VehicleMalfunctionIndStrategy : 14|2@1+ (1,0) [0|3] "" Vector__XXX
 SG_ VehicleContinuousMalfunctionInd : 12|2@1+ (1,0) [0|3] "" Vector__XXX
 SG_ VehicleNonRoadworthyCompCount : 0|8@1+ (1,0) [0|250] "" Vector__XXX

BO_ 2359361278 DM34: 8 Vector__XXX
 SG_ PMNTEDeficiencyAreaStatus : 10|2@1+ (1,0) [0|3] "" Vector__XXX
 SG_ MnfcPMNTECarveOutAreaStatus : 12|2@1+ (1,0) [0|3] "" Vector__XXX
 SG_ PMNTEControlAreaStatus : 14|2@1+ (1,0) [0|3] "" Vector__XXX
 SG_ NOxNTEDeficiencyAreaStatus : 2|2@1+ (1,0) [0|3] "" Vector__XXX
 SG_ MnfcNOxNTECarveOutAreaStatus : 4|2@1+ (1,0) [0|3] "" Vector__XXX
 SG_ NOxNTEControlAreaStatus : 6|2@1+ (1,0) [0|3] "" Vector__XXX

BO_ 2292317950 DM33: 9 Vector__XXX
 SG_ AECDEngineHours1Timer2 : 40|32@1+ (1,0) [0|4294967295] "min" Vector__XXX
 SG_ AECDEngineHours1Timer1 : 8|32@1+ (1,0) [0|4294967295] "min" Vector__XXX
 SG_ AECDNumber1 : 0|8@1+ (1,0) [0|250] "" Vector__XXX

BO_ 2566809342 BM: 8 Vector__XXX
 SG_ BatteryMainSwitchHoldState : 0|2@1+ (1,0) [0|3] "" Vector__XXX

BO_ 2365446910 BJM3: 8 Vector__XXX
 SG_ Joystick3XAxisDetentPosStatus : 38|2@1+ (1,0) [0|3] "" Vector__XXX
 SG_ Joystick3Button9PressedStatus : 62|2@1+ (1,0) [0|3] "" Vector__XXX
 SG_ Joystick3Button10PressedStatus : 60|2@1+ (1,0) [0|3] "" Vector__XXX
 SG_ Joystick3Button11PressedStatus : 58|2@1+ (1,0) [0|3] "" Vector__XXX
 SG_ Joystick3Button12PressedStatus : 56|2@1+ (1,0) [0|3] "" Vector__XXX
 SG_ Joystick3YAxisDetentPosStatus : 36|2@1+ (1,0) [0|3] "" Vector__XXX
 SG_ Joystick3YAxisPos : 22|10@1+ (0.1,0) [0|100] "%" Vector__XXX
 SG_ Jystck3YAxsLvrFrwrdPstvPosStatus : 20|2@1+ (1,0) [0|3] "" Vector__XXX
 SG_ Jystck3YAxsLvrBckNgtivePosStatus : 18|2@1+ (1,0) [0|3] "" Vector__XXX
 SG_ Joystick3YAxisNeutralPosStatus : 16|2@1+ (1,0) [0|3] "" Vector__XXX
 SG_ Joystick3XAxisPos : 6|10@1+ (0.1,0) [0|100] "%" Vector__XXX
 SG_ Jystck3XAxsLvrRghtPstvePosStatus : 4|2@1+ (1,0) [0|3] "" Vector__XXX
 SG_ Jystck3XAxsLvrLftNgtivePosStatus : 2|2@1+ (1,0) [0|3] "" Vector__XXX
 SG_ Joystick3XAxisNeutralPosStatus : 0|2@1+ (1,0) [0|3] "" Vector__XXX
 SG_ Joystick3Button5PressedStatus : 54|2@1+ (1,0) [0|3] "" Vector__XXX
 SG_ Joystick3Button6PressedStatus : 52|2@1+ (1,0) [0|3] "" Vector__XXX
 SG_ Joystick3Button7PressedStatus : 50|2@1+ (1,0) [0|3] "" Vector__XXX
 SG_ Joystick3Button8PressedStatus : 48|2@1+ (1,0) [0|3] "" Vector__XXX
 SG_ Joystick3Button1PressedStatus : 46|2@1+ (1,0) [0|3] "" Vector__XXX
 SG_ Joystick3Button2PressedStatus : 44|2@1+ (1,0) [0|3] "" Vector__XXX
 SG_ Joystick3Button3PressedStatus : 42|2@1+ (1,0) [0|3] "" Vector__XXX
 SG_ Joystick3Button4PressedStatus : 40|2@1+ (1,0) [0|3] "" Vector__XXX

BO_ 2365446398 BJM2: 8 Vector__XXX
 SG_ Joystick2XAxisDetentPosStatus : 38|2@1+ (1,0) [0|3] "" Vector__XXX
 SG_ Joystick2YAxisDetentPosStatus : 36|2@1+ (1,0) [0|3] "" Vector__XXX
 SG_ Joystick2YAxisPos : 22|10@1+ (0.1,0) [0|100] "%" Vector__XXX
 SG_ Jystck2YAxsLvrFrwrdPstvPosStatus : 20|2@1+ (1,0) [0|3] "" Vector__XXX
 SG_ Jystck2YAxsLvrBckNgtivePosStatus : 18|2@1+ (1,0) [0|3] "" Vector__XXX
 SG_ Joystick2YAxisNeutralPosStatus : 16|2@1+ (1,0) [0|3] "" Vector__XXX
 SG_ Joystick2XAxisPos : 6|10@1+ (0.1,0) [0|100] "%" Vector__XXX
 SG_ Jystck2XAxsLvrRghtPstvePosStatus : 4|2@1+ (1,0) [0|3] "" Vector__XXX
 SG_ Jystck2XAxsLvrLftNgtivePosStatus : 2|2@1+ (1,0) [0|3] "" Vector__XXX
 SG_ Joystick2XAxisNeutralPosStatus : 0|2@1+ (1,0) [0|3] "" Vector__XXX
 SG_ Joystick2Button9PressedStatus : 62|2@1+ (1,0) [0|3] "" Vector__XXX
 SG_ Joystick2Button10PressedStatus : 60|2@1+ (1,0) [0|3] "" Vector__XXX
 SG_ Joystick2Button11PressedStatus : 58|2@1+ (1,0) [0|3] "" Vector__XXX
 SG_ Joystick2Button12PressedStatus : 56|2@1+ (1,0) [0|3] "" Vector__XXX
 SG_ Joystick2Button5PressedStatus : 54|2@1+ (1,0) [0|3] "" Vector__XXX
 SG_ Joystick2Button6PressedStatus : 52|2@1+ (1,0) [0|3] "" Vector__XXX
 SG_ Joystick2Button7PressedStatus : 50|2@1+ (1,0) [0|3] "" Vector__XXX
 SG_ Joystick2Button8PressedStatus : 48|2@1+ (1,0) [0|3] "" Vector__XXX
 SG_ Joystick2Button1PressedStatus : 46|2@1+ (1,0) [0|3] "" Vector__XXX
 SG_ Joystick2Button2PressedStatus : 44|2@1+ (1,0) [0|3] "" Vector__XXX
 SG_ Joystick2Button3PressedStatus : 42|2@1+ (1,0) [0|3] "" Vector__XXX
 SG_ Joystick2Button4PressedStatus : 40|2@1+ (1,0) [0|3] "" Vector__XXX

BO_ 2365445886 BJM1: 8 Vector__XXX
 SG_ Joystick1XAxisDetentPosStatus : 38|2@1+ (1,0) [0|3] "" Vector__XXX
 SG_ Joystick1YAxisDetentPosStatus : 36|2@1+ (1,0) [0|3] "" Vector__XXX
 SG_ Joystick1YAxisPos : 22|10@1+ (0.1,0) [0|100] "%" Vector__XXX
 SG_ Jystck1YAxsLvrFrwrdPstvPosStatus : 20|2@1+ (1,0) [0|3] "" Vector__XXX
 SG_ Jystck1YAxsLvrBckNgtivePosStatus : 18|2@1+ (1,0) [0|3] "" Vector__XXX
 SG_ Joystick1YAxisNeutralPosStatus : 16|2@1+ (1,0) [0|3] "" Vector__XXX
 SG_ Joystick1XAxisPos : 6|10@1+ (0.1,0) [0|100] "%" Vector__XXX
 SG_ Joystick1Button9PressedStatus : 62|2@1+ (1,0) [0|3] "" Vector__XXX
 SG_ Joystick1Button10PressedStatus : 60|2@1+ (1,0) [0|3] "" Vector__XXX
 SG_ Joystick1Button11PressedStatus : 58|2@1+ (1,0) [0|3] "" Vector__XXX
 SG_ Joystick1Button12PressedStatus : 56|2@1+ (1,0) [0|3] "" Vector__XXX
 SG_ Joystick1Button5PressedStatus : 54|2@1+ (1,0) [0|3] "" Vector__XXX
 SG_ Joystick1Button6PressedStatus : 52|2@1+ (1,0) [0|3] "" Vector__XXX
 SG_ Joystick1Button7PressedStatus : 50|2@1+ (1,0) [0|3] "" Vector__XXX
 SG_ Joystick1Button8PressedStatus : 48|2@1+ (1,0) [0|3] "" Vector__XXX
 SG_ Joystick1Button1PressedStatus : 46|2@1+ (1,0) [0|3] "" Vector__XXX
 SG_ Joystick1Button2PressedStatus : 44|2@1+ (1,0) [0|3] "" Vector__XXX
 SG_ Joystick1Button3PressedStatus : 42|2@1+ (1,0) [0|3] "" Vector__XXX
 SG_ Joystick1Button4PressedStatus : 40|2@1+ (1,0) [0|3] "" Vector__XXX
 SG_ Jystck1XAxsLvrRghtPstvePosStatus : 4|2@1+ (1,0) [0|3] "" Vector__XXX
 SG_ Jystck1XAxsLvrLftNgtivePosStatus : 2|2@1+ (1,0) [0|3] "" Vector__XXX
 SG_ Joystick1XAxisNeutralPosStatus : 0|2@1+ (1,0) [0|3] "" Vector__XXX

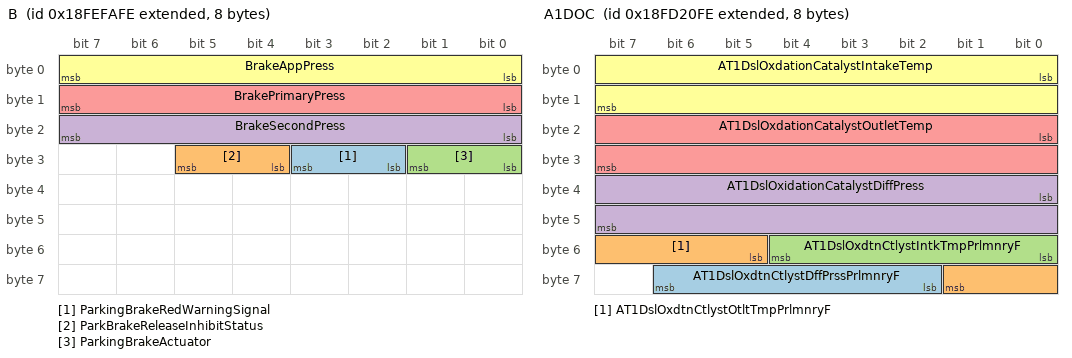
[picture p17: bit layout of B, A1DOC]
BO_ 2566847230 B: 8 Vector__XXX
 SG_ ParkingBrakeRedWarningSignal : 26|2@1+ (1,0) [0|3] "" Vector__XXX
 SG_ ParkBrakeReleaseInhibitStatus : 28|2@1+ (1,0) [0|3] "" Vector__XXX
 SG_ ParkingBrakeActuator : 24|2@1+ (1,0) [0|3] "" Vector__XXX
 SG_ BrakeSecondPress : 16|8@1+ (4,0) [0|1000] "kPa" Vector__XXX
 SG_ BrakePrimaryPress : 8|8@1+ (4,0) [0|1000] "kPa" Vector__XXX
 SG_ BrakeAppPress : 0|8@1+ (4,0) [0|1000] "kPa" Vector__XXX

BO_ 2566848254 AWPP: 8 Vector__XXX
 SG_ AuxPumpPress : 0|8@1+ (16,0) [0|4000] "kPa" Vector__XXX

BO_ 2566725886 A1DOC: 8 Vector__XXX
 SG_ AT1DslOxdtnCtlystDffPrssPrlmnryF : 58|5@1+ (1,0) [0|31] "" Vector__XXX
 SG_ AT1DslOxdtnCtlystOtltTmpPrlmnryF : 53|5@1+ (1,0) [0|31] "" Vector__XXX
 SG_ AT1DslOxdtnCtlystIntkTmpPrlmnryF : 48|5@1+ (1,0) [0|31] "" Vector__XXX
 SG_ AT1DslOxidationCatalystDiffPress : 32|16@1+ (0.1,0) [0|6425.5] "kPa" Vector__XXX
 SG_ AT1DslOxdationCatalystOutletTemp : 16|16@1+ (0.03125,-273) [-273|1734.96875] "°C" Vector__XXX
 SG_ AT1DslOxdationCatalystIntakeTemp : 0|16@1+ (0.03125,-273) [-273|1734.96875] "°C" Vector__XXX

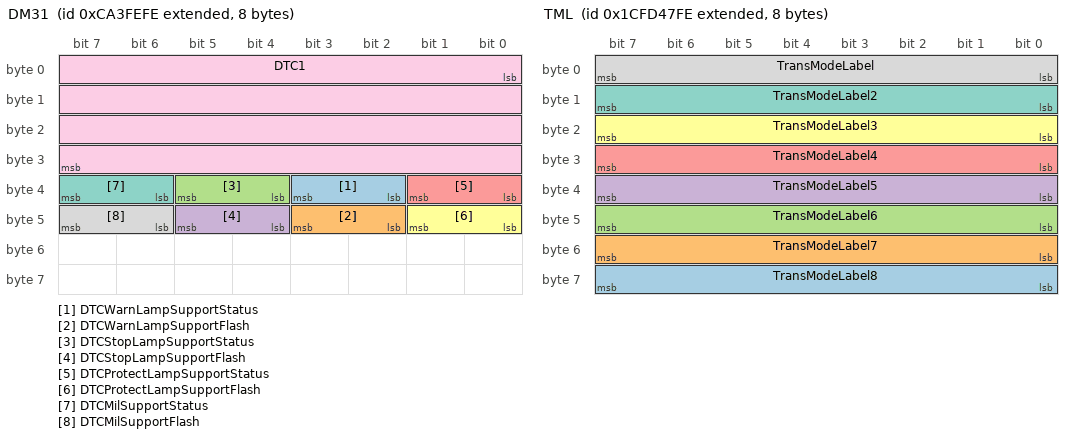
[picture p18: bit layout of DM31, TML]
BO_ 2359557886 DM31: 8 Vector__XXX
 SG_ DTCWarnLampSupportStatus : 34|2@1+ (1,0) [0|3] "" Vector__XXX
 SG_ DTCWarnLampSupportFlash : 42|2@1+ (1,0) [0|3] "" Vector__XXX
 SG_ DTCStopLampSupportStatus : 36|2@1+ (1,0) [0|3] "" Vector__XXX
 SG_ DTCStopLampSupportFlash : 44|2@1+ (1,0) [0|3] "" Vector__XXX
 SG_ DTCProtectLampSupportStatus : 32|2@1+ (1,0) [0|3] "" Vector__XXX
 SG_ DTCProtectLampSupportFlash : 40|2@1+ (1,0) [0|3] "" Vector__XXX
 SG_ DTCMilSupportStatus : 38|2@1+ (1,0) [0|3] "" Vector__XXX
 SG_ DTCMilSupportFlash : 46|2@1+ (1,0) [0|3] "" Vector__XXX
 SG_ DTC1 : 0|32@1+ (1,0) [0|4294967295] "" Vector__XXX

BO_ 2633844734 TML: 8 Vector__XXX
 SG_ TransModeLabel8 : 56|8@1+ (1,0) [0|255] "per byte" Vector__XXX
 SG_ TransModeLabel7 : 48|8@1+ (1,0) [0|255] "per byte" Vector__XXX
 SG_ TransModeLabel6 : 40|8@1+ (1,0) [0|255] "per byte" Vector__XXX
 SG_ TransModeLabel5 : 32|8@1+ (1,0) [0|255] "per byte" Vector__XXX
 SG_ TransModeLabel4 : 24|8@1+ (1,0) [0|255] "per byte" Vector__XXX
 SG_ TransModeLabel3 : 16|8@1+ (1,0) [0|255] "per byte" Vector__XXX
 SG_ TransModeLabel2 : 8|8@1+ (1,0) [0|255] "per byte" Vector__XXX
 SG_ TransModeLabel : 0|8@1+ (1,0) [0|255] "" Vector__XXX

BO_ 2560360190 PMI: 8 Vector__XXX
 SG_ DataDictionaryMethod : 11|21@1+ (1,0) [0|2097151] "" Vector__XXX
 SG_ DataDictionaryManufacturerCode : 0|11@1+ (1,0) [0|2047] "" Vector__XXX

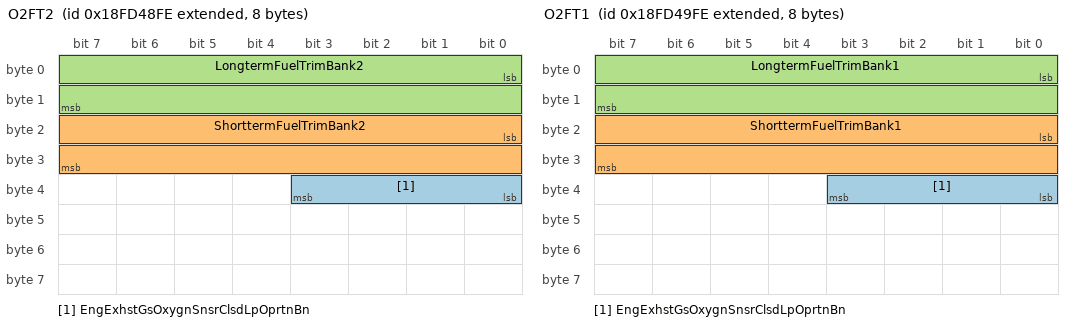
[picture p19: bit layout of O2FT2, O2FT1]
BO_ 2566736126 O2FT2: 8 Vector__XXX
 SG_ EngExhstGsOxygnSnsrClsdLpOprtnBn : 32|4@1+ (1,0) [0|15] "" Vector__XXX
 SG_ ShorttermFuelTrimBank2 : 16|16@1+ (0.1,-100) [-100|100] "%" Vector__XXX
 SG_ LongtermFuelTrimBank2 : 0|16@1+ (0.1,-100) [-100|100] "%" Vector__XXX

BO_ 2566736382 O2FT1: 8 Vector__XXX
 SG_ EngExhstGsOxygnSnsrClsdLpOprtnBn : 32|4@1+ (1,0) [0|15] "" Vector__XXX
 SG_ ShorttermFuelTrimBank1 : 16|16@1+ (0.1,-100) [-100|100] "%" Vector__XXX
 SG_ LongtermFuelTrimBank1 : 0|16@1+ (0.1,-100) [-100|100] "%" Vector__XXX

CM_ BO_ 2566735614 "The purpose of this PGN is to group the aftertreatment Three Way Catalyst data for bank 1. These values include the intake temperature, outlet temperature and differential pressure as well as the associated preliminary FMIs.
Note: The 5 bits of SPN ...";
CM_ SG_ 2566735614 AT1ThrWyCtlytcCnvrtrDffPrssPrlmn "Used to identify the applicable J1939-73 FMI detected in the Three Way Catalytic Converter differential pressure sensor by the manufacturer’s sensor control software in exhaust bank 1. When there is no failure FMI 31 is sent. In the case of multiple ...";
CM_ SG_ 2566735614 AT1ThrWyCtlystOtltTmpPrlmnaryFMI "Used to identify the applicable J1939-73 FMI detected in the Three Way Catalyst outlet temperature sensor by the manufacturer’s sensor control software in exhaust bank 1. When there is no failure FMI 31 is sent. In the case of multiple failures the ...";
CM_ SG_ 2566735614 AT1ThrWyCtlystIntkTmpPrlmnaryFMI "Used to identify the applicable J1939-73 FMI detected in the Three Way Catalyst intake temperature sensor by the manufacturer’s sensor control software in exhaust bank 1. When there is no failure FMI 31 is sent. In the case of multiple failures the ...";
CM_ SG_ 2566735614 AT1ThreeWayCatalystDiffPress "Exhaust differential pressure measured between the intake and exhaust of a Three Way Catalyst in exhaust bank 1.";
CM_ SG_ 2566735614 AT1ThreeWayCatalystOutletTemp "Temperature of engine combustion byproducts leaving the Three Way Catalyst in exhaust bank 1.";
CM_ SG_ 2566735614 AT1ThreeWayCatalystIntakeTemp "Temperature of engine combustion byproducts entering the Three Way Catalyst in exhaust bank 1.";
CM_ BO_ 2566805246 "Contains information on various tank levels";
CM_ SG_ 2566805246 AT1DslExhstFldTnk1HtrPrlmnaryFMI "Used to identify the applicable J1939-73 FMI detected for the heater of the diesel exhaust fluid tank for aftertreatment system 1 (exhaust bank 1), as detected by the manufacturer's control software.  When there is no failure, FMI 31 is sent. In the ...";
CM_ SG_ 2566805246 AT1DieselExhaustFluidTankHeater "Percentage of heating applied to the aftertreatment 1 diesel exhaust fluid tank heater.  A value of 0% means no heating applied, a value of 100% means full heating applied.  The diesel exhaust fluid tank heater warms the diesel exhaust fluid in the ...";
CM_ SG_ 2566805246 ATSCROperatorInducementSeverity "Severity status of the operator inducement system for anomalies with the SCR system, such as tampering, low DEF quality, and DEF tank level.  Higher numerical levels indicate more severe levels of inducement.  Level 1 is the least severe.
000 - ...";
CM_ SG_ 2566805246 AT1DslExhstFldTnk1TmpPrlmnaryFMI "Used to identify the applicable J1939-73 FMI detected for the diesel exhaust fluid tank temperature for aftertreatment system 1 (exhaust bank 1), as detected by the manufacturer’s control software. When there is no failure, FMI 31 is sent. In the ...";
CM_ SG_ 2566805246 ATSlctvCtlytcRdctnOprtrIndcmntAc "The desired illumination of the driver's warning indicator for diesel exhaust fluid (DEF) tank low level.
000 - Off -  indicates adequate DEF level
e.g., for Euro VI this is used to indicate the driver warning system is non-active for diesel ...";
CM_ SG_ 2566805246 AT1DslExhstFldTnkLvlPrlminaryFMI "Used to identify the applicable J1939-73 FMI detected in the diesel exhaust fluid tank level sensor by the manufacturer's sensor control software.  This FMI is applicable to either the diesel exhaust fluid tank level 1 or diesel exhaust fluid tank ...";
CM_ SG_ 2566805246 AT1DieselExhaustFluidTankLevel "The diesel exhaust fluid level height in mm in the diesel exhaust fluid storage container for aftertreatment system 1 (exhaust bank 1).  See SPN 1761 and SPN 7530 for alternate measurements.
Parameter Specific Indicator:
A value of 0xFB indicates ...";
CM_ SG_ 2566805246 AT1DieselExhaustFluidTankTemp "Temperature of the diesel exhaust fluid in the storage tank.";
CM_ SG_ 2566805246 AT1DieselExhaustFluidTankVolume "Ratio of volume of diesel exhaust fluid to the total volume of diesel exhaust fluid storage container for aftertreatment system 1 (exhaust bank 1).  0% is empty and 100% is full.  See SPN 3517 and SPN 7530 for alternate measurements.
Parameter ...";
CM_ BO_ 2365394686 "Aftertreatment 1 Outlet Gas NOx Sensor Correction Data 2";
CM_ SG_ 2365394686 AT1OutletCorrectedNOx "The corrected outlet NOx value for aftertreatment 1 shall include all learned adaptions and offsets that are used to adjust the raw signal.
2016 MY and later engines with NOx sensors may be required to output a ‘corrected’ NOx sensor signal in ...";
CM_ SG_ 2365394686 AT1OtltNOxSnsrSlfdgnssFnalResult "Self-diagnosis result for NOx sensor ATO1 (Aftertreatment Outlet Bank 1) as a ratio of detected value to reference value defined by supplier.
This result is used to determine if the signal resulting from the self-diagnosis test (as represented as a ...";
CM_ SG_ 2365394686 AT1OutletNOxSensorNH3Correction "Correction of NH3 at the NOx-signal to correct (recalculate) sensor signal on the Engine ECU side.";
CM_ SG_ 2365394686 AT1OutletNOxSensorNO2Correction "Correction of NO2 at the NOx-signal to correct (recalculate) sensor signal on the Engine ECU side.";
CM_ SG_ 2365394686 AT1OtltNOxSnsrNOxPressCorrection "Correction of pressure NOx-signal to correct (recalculate) sensor signal on the Engine ECU side.";
CM_ SG_ 2365394686 AT1OtltNOxSnsorO2PressCorrection "Correction of pressure Lambda-signal to correct (recalculate) sensor signal on the Engine ECU side.";
CM_ BO_ 2365394942 "Aftertreatment 1 Outlet Gas NOx Sensor Correction Data 1";
CM_ SG_ 2365394942 AT1OutletNOxSensorOperationHours "Counted hours that the NOx-sensor was operated with status \"dewpoint reached\"";
CM_ SG_ 2365394942 AT1OtltNOxSnsrNwPrtDvtnNOxOffset "New part deviation NOx_Offset to correct (recalculate) sensor signal on the Engine ECU side.";
CM_ SG_ 2365394942 AT1OtltNOxSnsrNwPrtDvtionNOxGain "New part deviation NOx_Gain to correct (recalculate) sensor signal on the Engine ECU side.";
CM_ SG_ 2365394942 AT1OutletNOxSensorHeaterRatio "Heater ratio to determine temperature at sensor tip.";
CM_ BO_ 2365395198 "Aftertreatment 1 Intake Gas NOx Sensor Correction Data 2";
CM_ SG_ 2365395198 AT1SCRIntakeCorrectedNOx "The corrected intake Selective Catalytic Reduction NOx value for aftertreatment 1 shall include all learned adaptions and offsets that are used to adjust the raw signal.
2016 MY and later engines with NOx sensors may be required to output a ...";
CM_ SG_ 2365395198 AT1IntkNOxSnsrSlfdgnssFnalResult "Self-diagnosis result for NOx sensor ATI1 (Aftertreatment Intake Bank 1) as a ratio of detected value to reference value defined by supplier.
This result is used to determine if the signal resulting from the self-diagnosis test (as represented as a ...";
CM_ SG_ 2365395198 AT1IntakeNOxSensorNH3Correction "Correction of NH3 at the NOx-signal to correct (recalculate) sensor signal on the Engine ECU side.";
CM_ SG_ 2365395198 AT1IntakeNOxSensorNO2Correction "Correction of NO2 at the NOx-signal to correct (recalculate) sensor signal on the Engine ECU side.";
CM_ SG_ 2365395198 AT1IntkNOxSnsrNOxPressCorrection "Correction of pressure NOx-signal to correct (recalculate) sensor signal on the Engine ECU side.";
CM_ SG_ 2365395198 AT1IntkNOxSnsorO2PressCorrection "Correction of pressure Lambda-signal to correct (recalculate) sensor signal on the Engine ECU side.";
CM_ BO_ 2365395454 "Aftertreatment 1 Intake Gas NOx Sensor Correction Data 1";
CM_ SG_ 2365395454 AT1IntakeNOxSensorOperationHours "Counted hours that the NOx-sensor was operated with status \"dewpoint reached\"";
CM_ SG_ 2365395454 AT1IntkNOxSnsrNwPrtDvtnNOxOffset "New part deviation NOx_Offset to correct (recalculate) sensor signal on the Engine ECU side.";
CM_ SG_ 2365395454 AT1IntkNOxSnsrNwPrtDvtionNOxGain "New part deviation NOx_Gain to correct (recalculate) sensor signal on the Engine ECU side.";
CM_ SG_ 2365395454 AT1IntakeNOxSensorHeaterRatio "Heater ratio to determine temperature at sensor tip.";
CM_ BO_ 2157248254 "The purpose of this PGN is to group the Aftertreatment 1 DPF soot measurement calibration parameters. These values include soot sensor signal mean and standard deviation calibration levels. These calibration levels are associated with Diesel ...";
CM_ SG_ 2157248254 AT1DslPrtcltFltrStStndrdDvtnClbO "Calibration offset for the soot standard deviation for Aftertreatment 1 Diesel Particulate Filter soot sensor.";
CM_ SG_ 2157248254 AT1DslPrtcltFltrStManCalibOffset "Calibration offset for the soot Mean for Aftertreatment 1 Diesel Particulate Filter soot sensor.";
CM_ BO_ 2566711806 "Operator commands sent via the Armrest Switch Matrices.";
CM_ SG_ 2566711806 Armrest2Switch2 "Status of the second switch located in armrest 2.

00: Off
01: On
10: Reserved
11: Don't care/take no action";
CM_ SG_ 2566711806 Armrest2Switch1 "Status of the first switch located in armrest 2.

00: Off
01: On
10: Reserved
11: Don't care/take no action";
CM_ SG_ 2566711806 Armrest1Switch2 "Status of the second switch located in armrest 1.

00: Off
01: On
10: Reserved
11: Don't care/take no action";
CM_ SG_ 2566711806 Armrest1Switch1 "Status of the first switch located in armrest 1.

00: Off
01: On
10: Reserved
11: Don't care/take no action";
CM_ BO_ 2364549886 "The Angular Rate Information message shall provide a measurement of the vehicle's pitch rate, roll rate, and yaw rate measurements.  The vehicle dynamics measurements in this message shall be according to a Z-Down axis system as referenced in SAE ...";
CM_ SG_ 2364549886 AngularRateMeasurementLatency "The estimated measurement latency of the measurement.
NOTE: This is only the sensor latency and does not include any additional latencies that might exist because of the CAN Bus or overall system implementation. Latency is the time from sensor ...";
CM_ SG_ 2364549886 YawRateExRangeFigureOfMerit "Figure of merit for yaw angle measurement.

00 = Yaw rate fully functional. Data is within sensor specification.
01 = Yaw rate degraded. Data is suspect due to environmental conditions.
10 = Error
11 = Not available";
CM_ SG_ 2364549886 RollRateExRangeFigureOfMerit "Figure of merit for roll rate measurement.

00 = Roll rate fully functional. Data is within sensor specification.
01 = Roll rate degraded. Data is suspect due to environmental conditions.
10 = Error
11 = Not available";
CM_ SG_ 2364549886 PitchRateExRangeFigureOfMerit "Figure of merit for pitch rate measurement.

00 = Pitch rate fully functional. Data is within sensor specification.
01 = Pitch rate degraded. Data is suspect due to environmental conditions.
10 = Error
11 = Not available";
CM_ SG_ 2364549886 YawRateExRange "Yaw rate is the rate-of-change of the yaw angle over time.  A positive yaw rate signal results when the object turns clockwise.  This parameter is defined according to a Z-Down axis system and the sign of the value is in accordance to the right-hand ...";
CM_ SG_ 2364549886 RollRateExRange "Roll rate is the rate-of-change of the roll angle over time.  The roll rate for increasing roll to the right is reported with a positive value. Roll angle is the same for both Z-Down and Z-Up axis systems, since both systems have positive X axis ...";
CM_ SG_ 2364549886 PitchRateExRange "Pitch rate is the rate-of-change of the pitch angle over time, where the pitch angle vector is in the direction of travel of the vehicle. The pitch rate for increasing ascent over time is reported with a positive value. This parameter is defined ...";
CM_ BO_ 2566712318 "This message contains NOx adsorber information for aftertreatment system 2 (or bank 2).";
CM_ SG_ 2566712318 AT2NOxAdsorberDesulfationStatus "Indicates whether the NOx adsorber desulfation regeneration in the second aftertreatment system is active or inactive

00  Inactive
01  Active
10  Error indicator
11  Not available";
CM_ SG_ 2566712318 AT2NOxAdsorberRegenerationStatus "Indicates whether the NOx adsorber regeneration in the second aftertreatment system is active or inactive

00  Inactive
01  Active
10  Error indicator
11  Not available";
CM_ BO_ 2566712574 "This message contains NOx adsorber information for aftertreatment system 1 (or bank 1).";
CM_ SG_ 2566712574 AT1NOxAdsorberDesulfationStatus "Indicates whether the NOx adsorber desulfation regeneration in the first aftertreatment system is active or inactive

00  Inactive
01  Active
10  Error indicator
11  Not available";
CM_ SG_ 2566712574 AT1NOxAdsorberRegenerationStatus "Indicates whether the NOx adsorber regeneration in the first aftertreatment system is active or inactive.

00  Inactive
01  Active
10  Error indicator
11  Not available";
CM_ BO_ 2164078590 "This message contains SCR service information for aftertreatment system 2 (or bank 2).";
CM_ SG_ 2164078590 AT2SCRConversionEfficiency "The SCR conversion efficiency percentage.  Calculated as 100 times the catalyst intake NOx minus the catalyst outlet NOx divided by the catalyst intake NOx.  The catalyst conversion efficiency number in itself does not imply emissions compliance or ...";
CM_ SG_ 2164078590 AT2SCRCmmnddDslExhstFldCnsmption "This parameter transmits the amount of diesel exhaust fluid that the emissions control system has requested to be used, averaged over the past 15 hours of engine operation.
Used to determine whether the SCR system is using an appropriate amount of ...";
CM_ SG_ 2164078590 AT2DslExhstFldAverageConsumption "Measured use of diesel exhaust fluid by a Selective Catalytic Reduction system for exhaust emission control, averaged over the previous 15 hours of engine operation.
Used to determine whether the SCR system is using an appropriate amount of diesel ...";
CM_ BO_ 2566731006 "This message contains SCR reagent tank 2 information for aftertreatment system 2 (or bank 2).  The second tank for the aftertreatment system is usually a smaller quick-thaw reagent tank located in series with tank 1.";
CM_ SG_ 2566731006 AT2DslExhstFldQckThwHtrPrlmnryFM "Used to identify the applicable J1939-73 FMI detected for the heater of the diesel exhaust fluid quick thaw tank for aftertreatment system 2 (exhaust bank 2), as detected by the manufacturer's control software.  When there is no failure, FMI 31 is ...";
CM_ SG_ 2566731006 AT2DslExhustFluidQuickThawHeater "The diesel exhaust fluid quick thaw tank heater percentage for aftertreatment system 2 (exhaust bank 2). 0% is off. See SPN 5415 for the command for this tank heater.";
CM_ SG_ 2566731006 AT2DslExhstFldQckThwTmpPrlmnryFM "Used to identify the applicable J1939-73 FMI detected for the diesel exhaust fluid quick thaw tank temperature for aftertreatment system 2 (exhaust bank 2), as detected by the manufacturer’s control software. When there is no failure, FMI 31 is ...";
CM_ SG_ 2566731006 AT2DslExhstFldQckThwLvlPrlmnryFM "Used to identify the applicable J1939-73 FMI detected for the fluid level height of the diesel exhaust fluid quick thaw tank for aftertreatment system 2 (exhaust bank 2), as detected by the manufacturer's control software.  When there is no failure, ...";
CM_ SG_ 2566731006 AT2DslExhstFldQuickThawTankLevel "The diesel exhaust fluid level height in mm in the diesel exhaust fluid quick thaw tank for aftertreatment system 2 (exhaust bank 2).  See SPN 4433 for alternate measurement.
Parameter Specific Indicator:
A value of 0xFB indicates conditions are ...";
CM_ SG_ 2566731006 AT2DselExhaustFluidQuickThawTemp "The diesel exhaust fluid quick thaw tank temperature for aftertreatment system 2 (exhaust bank 2).";
CM_ SG_ 2566731006 AT2DslExhstFldQickThawTankVolume "Ratio of volume of diesel exhaust fluid to the total volume of diesel exhaust fluid storage container for aftertreatment system 2 (exhaust bank 2).  0% is empty and 100% is full.  An alternative to this SPN is SPN 4435.
Parameter Specific ...";
CM_ BO_ 2566731262 "This message contains diesel exhaust fluid tank 1 information for aftertreatment system 2 (or bank 2).  The first tank for the aftertreatment sytem is primary reagent storage tank.";
CM_ SG_ 2566731262 AT2DslExhstFldTnk1HtrPrlmnaryFMI "Used to identify the applicable J1939-73 FMI detected for the heater of the diesel exhaust fluid tank for aftertreatment system 2 (exhaust bank 2), as detected by the manufacturer's control software.  When there is no failure, FMI 31 is sent. In the ...";
CM_ SG_ 2566731262 AT2DieselExhaustFluidTankHeater "Percentage of heating applied to the aftertreatment 2 diesel exhaust fluid tank heater.  A value of 0% means no heating applied, a value of 100% means full heating applied.  The diesel exhaust fluid tank heater warms the diesel exhaust fluid in the ...";
CM_ SG_ 2566731262 AT2DslExhstFldTnk1TmpPrlmnaryFMI "Used to identify the applicable J1939-73 FMI detected for the diesel exhaust fluid tank temperature for aftertreatment system 2 (exhaust bank 2), as detected by the manufacturer’s control software. When there is no failure, FMI 31 is sent. In the ...";
CM_ SG_ 2566731262 AT2DslExhstFldTnkLvlPrlminaryFMI "Used to identify the applicable J1939-73 FMI detected in the diesel exhaust fluid tank level sensor by the manufacturer's sensor control software.  This FMI is applicable to either the diesel exhaust fluid tank level 1 or diesel exhaust fluid tank ...";
CM_ SG_ 2566731262 AT2DieselExhaustFluidTankLevel "The diesel exhaust fluid level height in mm in the diesel exhaust fluid storage container for aftertreatment system 2 (exhaust bank 2).  See SPN 4426 and SPN 7531 for alternate measurements.
Parameter Specific Indicator:
A value of 0xFB indicates ...";
CM_ SG_ 2566731262 AT2DieselExhaustFluidTankTemp "Temperature of the diesel exhaust fluid in the storage tank.";
CM_ SG_ 2566731262 AT2DieselExhaustFluidTankVolume "Ratio of volume of diesel exhaust fluid to the total volume of the diesel exhaust fluid storage container for aftertreatment system 2 (exhaust bank 2).  0% is empty and 100% is full.  See SPN 4428 and SPN 7531 for alternate measurements.
Parameter ...";
CM_ BO_ 2566730750 "This message contains diesel exhaust fluid supply information for aftertreatment system 2 (or bank 2).";
CM_ SG_ 2566730750 AT2DslExhstFldDsngUnt2RturnValve "Command to the valve which determines whether the diesel exhaust fluid of dosing unit 2 is delivered to the injector or is routed back to the diesel exhaust fluid tank. Zero directs all diesel exhaust fluid flow to the injector, 100% sends all ...";
CM_ SG_ 2566730750 AT2DslExhstFlidTankDrainValveCmd "Commanded percentage of maximum Aftertreatment 2 Diesel Exhaust Fluid Tank Drain Valve opening. 100% means the the drain valve is fully open providing maximum flow of diesel exhaust fluid out of  the diesel exhaust fluid tank.";
CM_ SG_ 2566730750 AT2DieselExhaustFluidPumpState "State of Aftertreatment 2 Diesel Exhaust Fluid dosing pump.

00  pump operational
01  pump error
10  reserved for SAE assignment
11 not available";
CM_ SG_ 2566730750 AT2DslExhstFluidTankFillValveCmd "Commanded percentage of maximum Aftertreatment 2 Diesel Exhaust Fluid Tank Fill Valve opening. 100% means the fill valve is fully open providing maximum flow of diesel exhaust fluid into the diesel exhaust fluid tank.";
CM_ SG_ 2566730750 AT2DslExhstFldDsngUnt1RturnValve "Command to the valve which determines whether the diesel exhaust fluid of dosing unit 1 is delivered to the injector or is routed back to the diesel exhaust fluid tank. Zero directs all diesel exhaust fluid flow to the injector, 100% sends all ...";
CM_ SG_ 2566730750 AT2DslExhstFldPmpDrivePercentage "The percent (command) sent to the motor to control the speed of  the diesel exhaust fluid pump.";
CM_ SG_ 2566730750 AT2DslExhustFluidPump1MotorSpeed "Rotational speed of the motor driving the first or only pump for the diesel exhaust fluid used in aftertreatment system 2 (exhaust bank 2).";
CM_ BO_ 2566731518 "Sensor Information which measures temperature, concentration, and conductivity of the diesel exhaust fluid of the aftertreatment 2 system.";
CM_ SG_ 2566731518 AT2DieselExhaustFluidType "This parameter indicates the property of the fluid compound in the tank.  A value of 0011 indicates uncontaminated Diesel Exhaust Fluid.
0000 - Urea concentration too high
0001 - Urea concentration too low
0010 - Fluid is diesel
0011 - Diesel ...";
CM_ SG_ 2566731518 AT2DslExhstFldPrprtsPrlminaryFMI "Used to identify the applicable J1939-73 FMI that applies to the most significant failure of the diesel exhaust fluid properties sensor.  This may be used for indicating failures of the diesel exhaust fluid concentration, diesel exhaust fluid ...";
CM_ SG_ 2566731518 AT2DslExhstFldTmp2PreliminaryFMI "Used to identify the applicable J1939-73 FMI that applies to the most significant failure of the diesel exhaust fluid temperature sensor.  When there is no failure FMI 31 is sent. In the case of multiple failures the most severe is communicated.";
CM_ SG_ 2566731518 AT2DeselExhaustFluidConductivity "A measure of the conductivity of the diesel exhaust fluid at the sensor.  The conductivity is an indication of the diesel exhaust fluid's chemical make up.";
CM_ SG_ 2566731518 AT2DselExhaustFluidConcentration "A measure of the concentration of urea in water.  Zero percent means that the tank contains no urea.  A 32.5% value indicates that the reagent is of the proper concentration.  The 32.5% value indicates that the concentration is highest quality.
 ...";
CM_ SG_ 2566731518 AT2DieselExhaustFluidTemp2 "Temperature of the diesel exhaust fluid at the device measuring diesel exhaust fluid quality";
CM_ BO_ 2566732030 "This message contains SCR catalyst intake and outlet exhaust gas temperature information for aftertreatment system 2 (or bank 2).";
CM_ SG_ 2566732030 AT2SCROutletTempPreliminaryFMI "Used to identify the applicable J1939-73 FMI detected in the SCR outlet temperature sensor by the manufacturer’s sensor control software in exhaust bank 2. When there is no failure FMI 31 is sent. In the case of multiple failures the most severe is ...";
CM_ SG_ 2566732030 AT2SCROutletTemp "Temperature of engine combustion byproducts leaving the SCR exhaust in exhaust bank 2.";
CM_ SG_ 2566732030 AT2SCRIntakeTempPreliminaryFMI "Used to identify the applicable J1939-73 FMI detected in the SCR intake temperature sensor by the manufacturer’s sensor control software in exhaust bank 2. When there is no failure FMI 31 is sent. In the case of multiple failures the most severe is ...";
CM_ SG_ 2566732030 AT2SCRIntakeTemp "Temperature of engine combustion byproducts entering the SCR in exhaust bank 2.";
CM_ BO_ 2566732286 "This message contains SCR catalyst exhaust gas pressure information for aftertreatment system 2 (or bank 2).";
CM_ SG_ 2566732286 AT2SCRIntakeAbsPress "Used to read the pressure at the catalyst intake of the selective catalytic reduction system of aftertreatment 2.";
CM_ SG_ 2566732286 AT2SCRIntakePress "The gage pressure at the intake of the selective catalytic reduction system of Aftertreatment 2.";
CM_ SG_ 2566732286 AT2SCRDiffPressPreliminaryFMI "Used to identify the applicable J1939-73 FMI detected in the SCR differential pressure sensor by the manufacturer’s sensor control software in exhaust bank 2. When there is no failure FMI 31 is sent. In the case of multiple failures the most severe ...";
CM_ SG_ 2566732286 AT2SCRDiffPress "Differential pressure measured between the intake and exhaust of an SCR component in exhaust bank 2.";
CM_ BO_ 2164079358 "This message contains SCR dosing system request information for aftertreatment system 2 (or bank 2).";
CM_ SG_ 2164079358 AT2DeselExhaustFluidLineHeater10 "The diesel exhaust fluid line heater 10 request for aftertreatment system 2 (exhaust bank 2).

00 = request for heater to be inactive
01 = request for heater to be active
10 = reserved for future assignment by SAE
11 = not available";
CM_ SG_ 2164079358 AT2DieselExhaustFluidLineHeater9 "The diesel exhaust fluid line heater 9 request for aftertreatment system 2 (exhaust bank 2).

00 = request for heater to be inactive
01 = request for heater to be active
10 = reserved for future assignment by SAE
11 = not available";
CM_ SG_ 2164079358 AT2DieselExhaustFluidLineHeater8 "The diesel exhaust fluid line heater 8 request for aftertreatment system 2 (exhaust bank 2).

00 = request for heater to be inactive
01 = request for heater to be active
10 = reserved for future assignment by SAE
11 = not available";
CM_ SG_ 2164079358 AT2DieselExhaustFluidLineHeater7 "The diesel exhaust fluid line heater 7 request for aftertreatment system 2 (exhaust bank 2).

00 = request for heater to be inactive
01 = request for heater to be active
10 = reserved for future assignment by SAE
11 = not available";
CM_ SG_ 2164079358 AT2DieselExhaustFluidLineHeater6 "The diesel exhaust fluid line heater 6 request for aftertreatment system 2 (exhaust bank 2).

00 = request for heater to be inactive
01 = request for heater to be active
10 = reserved for future assignment by SAE
11 = not available";
CM_ SG_ 2164079358 AT2DieselExhaustFluidLineHeater5 "Identifies the diesel exhaust fluid line heater 5 request for aftertreatment system 2 (exhaust bank 2).

00 request for heater to be inactive 
01 request for heater to be active 
10 reserved for future assignment by SAE 
11 not available";
CM_ SG_ 2164079358 AT2DslExhstFluidLineHeaterRelay3 "The aftertreatment system 2 diesel exhaust fluid line heater relay 3 is used to energize one or more DEF line heaters.

00 - Off
01 - On
10 - Error
11 - Not available";
CM_ SG_ 2164079358 AT2DslExhstFluidLineHeaterRelay2 "The aftertreatment system 2 diesel exhaust fluid line heater relay 2 is used to energize one or more DEF line heaters.

00 - Off
01 - On
10 - Error
11 - Not available";
CM_ SG_ 2164079358 AT2DslExhstFluidLineHeaterRelay1 "The aftertreatment system 2 diesel exhaust fluid line heater relay 1 is used to energize one or more DEF line heaters.

00 - Off
01 - On
10 - Error
11 - Not available";
CM_ SG_ 2164079358 AT2DslExhstFldQuickThawHeaterCmd "The command for the heater of the diesel exhaust fluid quick thaw tank for aftertreatment system 2 (exhaust bank 2).  See SPN 4438 for the measured heater percentage for the heater of this same tank.";
CM_ SG_ 2164079358 AT2DselExhaustFluidTankHeaterCmd "Command for the Aftertreatment 2 Diesel Exhaust Fluid Tank Heater.  A value of 0% means no heating applied, a value of 100% means full heating applied.  See SPN 4431 for the measured value of the Aftertreatment 2 Diesel Exhaust Fluid Tank Heater.";
CM_ SG_ 2164079358 AT2DieselExhaustFluidLineHeater4 "The diesel exhaust fluid line heater 4 request for aftertreatment system 2 (exhaust bank 2). 
 
00 request for heater to be inactive 
01 request for heater to be active 
10 reserved for future assignment by SAE 
11 not available";
CM_ SG_ 2164079358 AT2DieselExhaustFluidLineHeater3 "The diesel exhaust fluid line heater 3 request for aftertreatment system 2 (exhaust bank 2). 

00 request for heater to be inactive 
01 request for heater to be active 
10 reserved for future assignment by SAE 
11 not available";
CM_ SG_ 2164079358 AT2DieselExhaustFluidLineHeater2 "The diesel exhaust fluid line heater 2 request for aftertreatment system 2 (exhaust bank 2). 

00 request for heater to be inactive 
01 request for heater to be active 
10 reserved for future assignment by SAE 
11 not available";
CM_ SG_ 2164079358 AT2DieselExhaustFluidLineHeater1 "The diesel exhaust fluid line heater 1 request for aftertreatment system 2 (exhaust bank 2). 

00 request for heater to be inactive 
01 request for heater to be active 
10 reserved for future assignment by SAE 
11 not available";
CM_ SG_ 2164079358 AT2DslExhstFldDoserHeatingModeRq "Used if multiple heater modes are available in the Doser.

000   Heater off
001   Heater economy mode
010   Heater automatic mode
011   Heater on
100 - 110    Reserved
111   Not available";
CM_ SG_ 2164079358 AT2DslExhstFldDsrFltSppressionRq "Used if external devices can warn of conditions that require suppression of potential faults in the doser due to environmental conditions.

00    Error suppression off
01    Error suppression on
10    Reserved
11    Not available";
CM_ BO_ 2364549118 "This message contains SCR dosing system request information for aftertreatment system 2 (or bank 2).";
CM_ SG_ 2364549118 AT2DslExhstFldRqstdQnttyOfIntgrt "Represents the command for the diesel exhaust fluid quantity integrator in the dosing control unit";
CM_ SG_ 2364549118 AT2DslExhstFldDsngRqstedQuan6594 "Requested dosing quantity of diesel exhaust fluid. This SPN is a high range measurement. See SPN 4401 if high range is not needed.";
CM_ SG_ 2364549118 AT2DselExhaustFluidPumpHeaterCmd "Command for the Aftertreatment 2 Diesel Exhaust Fluid Pump Heater.  A value of 0% means no heating commanded, a value of 100% means full heating commanded.";
CM_ SG_ 2364549118 AT2DslExhstFldDsngTstInjctnPrmss "After a request to permit the DEF dosing test injection has been indicated, this permission status is expected by the DEF control unit for aftertreatment system 2.
00 = not allowed
01 = DEF dosing test injection allowed
10 = error
11 = not ...";
CM_ SG_ 2364549118 AT2DslExhstFldHydStffnssChckPrms "After a request to permit the DEF hydraulic stiffness check has been indicated, this permission status is expected by the DEF control unit for aftertreatment system 2.
00 = not allowed
01 = DEF hydraulic stiffness check allowed
10 = error
11 = ...";
CM_ SG_ 2364549118 AT2SCRSystemRequestedState "Requested state of SCR system for aftertreatment system 2 (exhaust bank 2).
0000 Dormant (sleep mode)
0001 Preparing dosing readiness (wake up; prepare to operate; wait for start)
0010 Normal dosing operation
0011 System error pending
0100 ...";
CM_ SG_ 2364549118 AT2DslExhstFldDsngRqstedQuantity "Actual requested dosing quantity of diesel exhaust fluid.";
CM_ BO_ 2566732798 "This message contains SCR dosing system information for aftertreatment system 2 (or bank 2).  See PGN 61478 for more information.";
CM_ SG_ 2566732798 AT2DslExhstFldLnHtr4PrlminaryFMI "Used to identify the applicable J1939-73 FMI detected in the diesel exhaust fluid line heater 4, by the manufacturer’s control software in exhaust bank 2. When there is no failure FMI 31 is sent. In the case of multiple failures the most severe is ...";
CM_ SG_ 2566732798 AT2DslExhstFluidLineHeater4State "The diesel exhaust fluid line heater 4 state for aftertreatment system 2 (exhaust bank 2).

00 heater inactive 
01 heater active 
10 error 
11 not available";
CM_ SG_ 2566732798 AT2DslExhstFldLnHtr3PrlminaryFMI "Used to identify the applicable J1939-73 FMI detected in the diesel exhaust fluid line heater 3, by the manufacturer’s control software in exhaust bank 2. When there is no failure FMI 31 is sent. In the case of multiple failures the most severe is ...";
CM_ SG_ 2566732798 AT2DslExhstFluidLineHeater3State "The diesel exhaust fluid line heater 3 state for aftertreatment system 2 (exhaust bank 2).

00 heater inactive 
01 heater active 
10 error 
11 not available";
CM_ SG_ 2566732798 AT2DslExhstFldLnHtr2PrlminaryFMI "Used to identify the applicable J1939-73 FMI detected in the diesel exhaust fluid line heater 2, by the manufacturer’s control software in exhaust bank 2. When there is no failure FMI 31 is sent. In the case of multiple failures the most severe is ...";
CM_ SG_ 2566732798 AT2DslExhstFluidLineHeater2State "The diesel exhaust fluid line heater 2 state for aftertreatment system 2 (exhaust bank 2).

00 heater inactive 
01 heater active 
10 error 
11 not available";
CM_ SG_ 2566732798 AT2DslExhstFldLnHtr1PrlminaryFMI "Used to identify the applicable J1939-73 FMI detected in the diesel exhaust fluid line heater 1, by the manufacturer’s control software in exhaust bank 2. When there is no failure FMI 31 is sent. In the case of multiple failures the most severe is ...";
CM_ SG_ 2566732798 AT2DslExhstFluidLineHeater1State "The diesel exhaust fluid line heater 1 state for aftertreatment system 2 (exhaust bank 2).

00 heater inactive 
01 heater active 
10 error 
11 not available";
CM_ SG_ 2566732798 AT2SCRFeedbackCtrlStatus "The SCR feedback control status (open/closed loop) for aftertreatment system 2 (exhaust bank 2).
000 open loop control active
001 closed loop control active
010 reserved for future assignment by SAE
011 reserved for future assignment by SAE
100 ...";
CM_ SG_ 2566732798 AT2SCRDsngVlvExhstTmpReductionRq "Protection request for the dosing valve of the SCR-system to prevent overheating
000:    no request
001:    reduction request stage 1
010:    reduction request stage 2
011:    reserved for future assignment by SAE
100:    reserved for future ...";
CM_ SG_ 2566732798 AT2DieselExhaustFluidDoser1Temp "The temperature (measured closest to dosing valve) of the first or only DEF doser for aftertreatment system 2 (exhaust bank 2).";
CM_ SG_ 2566732798 AT2SCRDosingAirAssistValve "The position of the valve used to regulate the air supply of an air assist SCR dosing system for an engine. 0% represents no supply and 100% is full supply.";
CM_ SG_ 2566732798 AT2SCRDosingAirAssistAbsPress "The SCR dosing system air assist absolute pressure for aftertreatment system 2 (exhaust bank 2).  The air assist system is used to improve the dosed reagent atomization.";
CM_ BO_ 2364548862 "This message contains SCR dosing system information for aftertreatment system 2 (or bank 2).  See PGN 64827 for more information.";
CM_ SG_ 2364548862 AT2DslExhstFldActlDosingQuan6596 "Actual dosing quantity of diesel exhaust fluid. See SPN 4384 if high range measurement is not needed.";
CM_ SG_ 2364548862 AT2SCRSystem2State "Actual state of SCR system 2
0000 = Dormant (sleep mode)
0001 = Preparing dosing readiness (wake up; prepare to operate; wait for start)
0010 = Normal dosing operation
0011 = System error pending
0100 = Purging (SCR dosing system is removing ...";
CM_ SG_ 2364548862 AT2DslExhaustFluidDoser1AbsPress "The absolute pressure (measured closest to dosing valve) of the first or only DEF doser for aftertreatment system 2 (exhaust bank 2).";
CM_ SG_ 2364548862 AT2DslExhstFldActlQnttyOfIntgrtr "The SCR requested diesel exhaust fluid integrator total quantity for aftertreatment system 2 (exhaust bank 2).";
CM_ SG_ 2364548862 AT2SCRSystem1State "Actual state of SCR system 1.
0000    Dormant (sleep mode)
0001    Preparing dosing readiness (wake up; prepare to operate; wait for start)
0010    Normal dosing operation
0011    System error pending
0100    Reserved for future assignment by ...";
CM_ SG_ 2364548862 AT2DslExhstFldActlDosingQuantity "Actual reducing agent quantity of SCR system.";
CM_ BO_ 2364549374 "This message contains outlet ammonia information for aftertreatment system 2 (or bank 2).";
CM_ SG_ 2364549374 AT2OutletNH3GasSensorHeaterCtrl "Indicates the heater status in the warm-up process. Upon receiving a power-up command, the NH3 gas sensor ramps up according to a manufacturer defined profile. The Preheat 1, Preheat 2, and Automatic messages are regions within this profile in ...";
CM_ SG_ 2364549374 AT2OtltNH3GsSnsrHtrPrliminaryFMI "Used to identify the applicable J1939-73 FMI detected in the heater of the outlet NH3 exhaust gas sensor by the manufacturer’s sensor control software in exhaust bank 2. When there is no failure FMI 31 is sent. In the case of multiple failures the ...";
CM_ SG_ 2364549374 AT2OutletNH3GasSensorAtTemp "Indicates that the heater element of the aftertreatment outlet NH3 gas sensor is within the manufacturer’s specified range for accurate measurements in exhaust bank 2.
00 - Heater element is not in range
01 - Heater element is in range
10 - Error
 ...";
CM_ SG_ 2364549374 AT2OtletNH3GasSensorPowerInRange "Indicates that the power supplied to the aftertreatment outlet NH3 gas sensor is within the manufacturer’s specification in exhaust bank 2.

00 - Heater element is not in range
01 - Heater element is in range
10 - Error
11 - Not available";
CM_ SG_ 2364549374 AT2OutletNH3ReadingStable "Indicates that the NH3 reading of the aftertreatment outlet NH3 sensor is stable as determined by the manufacturer’s control software in exhaust bank 2.

00 - Reading is not stable
01 - Reading is stable
10 - Error
11 - Not available";
CM_ SG_ 2364549374 AT2OutletNH3SensorPreliminaryFMI "Used to identify the applicable J1939-73 FMI detected in the aftertreatment outlet NH3 sensor by the manufacturer’s sensor control software in exhaust bank 2. When there is no failure FMI 31 is sent. In the case of multiple failures the most severe ...";
CM_ SG_ 2364549374 AT2OutletNH3 "The amount of NH3 in the exhaust exiting the aftertreatment system measured by a NH3 sensor at the aftertreatment outlet, represented in NH3 molecule parts per million non-NH3 molecules in exhaust bank 2.";
CM_ BO_ 2566726142 "The purpose of this PGN is to group the aftertreatment gas oxidation catalyst data for bank 2. These values include the intake temperature, outlet temperature and differential pressure as well as the associated preliminary FMIs.  The gas parameters ...";
CM_ SG_ 2566726142 AT2GsOxdtnCtlystDffPrssPrlmnryFM "Used to identify the applicable J1939-73 FMI detected in the gas oxidation catalyst differential pressure sensor by the manufacturer’s sensor control software in exhaust bank 2. When there is no failure FMI 31 is sent. In the case of multiple ...";
CM_ SG_ 2566726142 AT2GsOxdtnCtlystOtltTmpPrlmnryFM "Used to identify the applicable J1939-73 FMI detected in the gas oxidation catalyst outlet gas temperature sensor by the manufacturer’s sensor control software in exhaust bank 2. When there is no failure FMI 31 is sent. In the case of multiple ...";
CM_ SG_ 2566726142 AT2GsOxdtnCtlystIntkTmpPrlmnryFM "Used to identify the applicable J1939-73 FMI detected in the gas oxidation catalyst intake gas temperature sensor by the manufacturer’s sensor control software in exhaust bank 2. When there is no failure FMI 31 is sent. In the case of multiple ...";
CM_ SG_ 2566726142 AT2GasOxidationCatalystDiffPress "Exhaust differential pressure measured between the intake and exhaust of the gas oxidation catalyst in exhaust bank 2.  This parameter should be used with engines fueled by gaseous fuel like natural gas or propane.  A separate parameter has been ...";
CM_ SG_ 2566726142 AT2GsOxidationCatalystOutletTemp "Temperature of engine combustion byproducts leaving the gas oxidation catalyst in exhaust bank 2.  This parameter should be used with engines fueled by gaseous fuel like natural gas or propane.  A separate parameter has been defined for diesel ...";
CM_ SG_ 2566726142 AT2GsOxidationCatalystIntakeTemp "Temperature of engine combustion byproducts entering the gas oxidation catalyst in exhaust bank 2.  This parameter should be used with engines fueled by gaseous fuel like natural gas or propane.  A separate parameter has been defined for diesel ...";
CM_ BO_ 2566725630 "The purpose of this PGN is to group the aftertreatment diesel oxidation catalyst data for bank 2. These values include the intake temperature, outlet temperature and differential pressure as well as the associated preliminary FMIs.  The diesel ...";
CM_ SG_ 2566725630 AT2DslOxdtnCtlystDffPrssPrlmnryF "Used to identify the applicable J1939-73 FMI detected in the diesel oxidation catalyst differential pressure sensor by the manufacturer’s sensor control software in exhaust bank 2. When there is no failure FMI 31 is sent. In the case of multiple ...";
CM_ SG_ 2566725630 AT2DslOxdtnCtlystOtltTmpPrlmnryF "Used to identify the applicable J1939-73 FMI detected in the diesel oxidation catalyst outlet gas temperature sensor by the manufacturer’s sensor control software in exhaust bank 2. When there is no failure FMI 31 is sent. In the case of multiple ...";
CM_ SG_ 2566725630 AT2DslOxdtnCtlystIntkTmpPrlmnryF "Used to identify the applicable J1939-73 FMI detected in the diesel oxidation catalyst intake temperature sensor by the manufacturer’s sensor control software in exhaust bank 2. When there is no failure FMI 31 is sent. In the case of multiple ...";
CM_ SG_ 2566725630 AT2DslOxidationCatalystDiffPress "Exhaust differential pressure measured between the intake and exhaust of a diesel oxidation catalyst in exhaust bank 2.  This parameter should be used with engines fueled by diesel fuel (not gaseous fuel like natural gas or propane).  A separate ...";
CM_ SG_ 2566725630 AT2DslOxdationCatalystOutletTemp "Temperature of engine combustion byproducts leaving the diesel oxidation catalyst exhaust in exhaust bank 2.  This parameter should be used with engines fueled by diesel fuel (not gaseous fuel like natural gas or propane).  A separate parameter has ...";
CM_ SG_ 2566725630 AT2DslOxdationCatalystIntakeTemp "Temperature of engine combustion byproducts entering the diesel oxidation catalyst in exhaust bank 2.  This parameter should be used with engines fueled by diesel fuel (not gaseous fuel like natural gas or propane).  A separate parameter has been ...";
CM_ BO_ 2566733310 "This message contains SCR reagent tank 2 information for aftertreatment system 1 (or bank 1).  The second tank for the aftertreatment system is usually a smaller quick-thaw reagent tank located in series with tank 1.";
CM_ SG_ 2566733310 AT1DslExhstFldQckThwHtrPrlmnryFM "Used to identify the applicable J1939-73 FMI detected for the heater of the diesel exhaust fluid quick thaw tank for aftertreatment system 1 (exhaust bank 1), as detected by the manufacturer's control software.  When there is no failure, FMI 31 is ...";
CM_ SG_ 2566733310 AT1DslExhustFluidQuickThawHeater "The diesel exhaust fluid quick thaw tank heater percentage for aftertreatment system 1 (exhaust bank 1). 0% is off. See SPN 5414 for the command for this tank heater.";
CM_ SG_ 2566733310 AT1DslExhstFldQckThwTmpPrlmnryFM "Used to identify the applicable J1939-73 FMI detected for the diesel exhaust fluid quick thaw tank temperature for aftertreatment system 1 (exhaust bank 1), as detected by the manufacturer’s control software. When there is no failure, FMI 31 is ...";
CM_ SG_ 2566733310 AT1DslExhstFldQckThwLvlPrlmnryFM "Used to identify the applicable J1939-73 FMI detected for the fluid level height of the diesel exhaust fluid quick thaw tank for aftertreatment system 1 (exhaust bank 1), as detected by the manufacturer's control software.  When there is no failure, ...";
CM_ SG_ 2566733310 AT1DslExhstFldQuickThawTankLevel "The diesel exhaust fluid level height in mm in the diesel exhaust fluid quick thaw tank for aftertreatment system 1 (exhaust bank 1). See SPN 4367 for alternate measurement.
Parameter Specific Indicator:
A value of 0xFB indicates conditions are ...";
CM_ SG_ 2566733310 AT1DselExhaustFluidQuickThawTemp "The diesel exhaust fluid quick thaw tank temperature for aftertreatment system 1 (exhaust bank 1).";
CM_ SG_ 2566733310 AT1DslExhstFldQickThawTankVolume "Ratio of volume of diesel exhaust fluid to the total volume of the diesel exhaust fluid quick thaw tank for aftertreatment system 1 (exhaust bank 1).  0% is empty and 100% is full.  See SPN 4369 for an alternate measurement.
Parameter Specific ...";
CM_ BO_ 2566733054 "This message contains diesel exhaust fluid supply information for aftertreatment system 1 (or bank 1).";
CM_ SG_ 2566733054 AT1DslExhstFldDsngUnt2RturnValve "Command to the valve which determines whether the diesel exhaust fluid on dosing unit 2 is delivered to the injector or is routed back to the diesel exhaust fluid tank. Zero directs all diesel exhaust fluid flow to the injector, 100% sends all ...";
CM_ SG_ 2566733054 AT1DieselExhaustFluidPump "State of the aftertreatment 1 Diesel Exhaust Fluid dosing pump.  Indicates if the pump is currently active (pumping).
00 off
01 on
10 error
11 not available
The aftertreatment 1 Diesel Exhaust Fluid dosing pump is a device that delivers a ...";
CM_ SG_ 2566733054 AT1DslExhaustFluidPumpPowerRelay "The state of the aftertreatment 1 diesel exhaust fluid pump power relay.

00 not active - no power is being applied to the relay
01 active - power is being applied to the relay
10 error
11 not available";
CM_ SG_ 2566733054 AT1DslExhstFlidTankDrainValveCmd "Commanded percentage of maximum Aftertreatment 1 Diesel Exhaust Fluid Tank Drain Valve opening. 100% means the drain valve is fully open providing maximum flow of diesel exhaust fluid out of the diesel exhaust fluid tank.";
CM_ SG_ 2566733054 AT1DieselExhaustFluidPumpState "State of the aftertreatment 1 Diesel Exhaust Fluid dosing pump.  Indicates whether or not the pump is operational.

00  pump operational
01  pump error
10  reserved for SAE assignment
11 not available";
CM_ SG_ 2566733054 AT1DslExhstFluidTankFillValveCmd "Commanded percentage of maximum Aftertreatment 1 Diesel Exhaust Fluid Tank Fill Valve opening. 100% means the fill valve is fully open providing maximum flow of diesel exhaust fluid into the diesel exhaust fluid tank.";
CM_ SG_ 2566733054 AT1DslExhstFldDsngUnt1RturnValve "Command to the valve which determines whether the diesel exhaust fluid on dosing unit 1 is delivered to the injector or is routed back to the diesel exhaust fluid tank. Zero directs all diesel exhaust fluid flow to the injector, 100% sends all ...";
CM_ SG_ 2566733054 AT1DslExhstFldPmpDrivePercentage "The percent (command) sent to the motor to control the speed of the diesel exhaust fluid pump.";
CM_ SG_ 2566733054 AT1DslExhustFluidPump1MotorSpeed "Rotational speed of the motor driving the first or only pump for the diesel exhaust fluid used in aftertreatment system 1 (exhaust bank 1).";
CM_ BO_ 2499624702 "This message contains SCR catalyst intake and outlet exhaust gas temperature information for aftertreatment system 1 (or bank 1).";
CM_ SG_ 2499624702 AT1SCROutletTempPreliminaryFMI "Used to identify the applicable J1939-73 FMI detected in the SCR outlet temperature sensor by the manufacturer’s sensor control software in exhaust bank 1. When there is no failure FMI 31 is sent. In the case of multiple failures the most severe is ...";
CM_ SG_ 2499624702 AT1SCROutletTemp "Temperature of engine combustion byproducts leaving the SCR outlet in exhaust bank 1.";
CM_ SG_ 2499624702 AT1SCRIntakeTempPreliminaryFMI "Used to identify the applicable J1939-73 FMI detected in the SCR intake temperature sensor by the manufacturer’s sensor control software in exhaust bank 1. When there is no failure FMI 31 is sent. In the case of multiple failures the most severe is ...";
CM_ SG_ 2499624702 AT1SCRIntakeTemp "Temperature of engine combustion byproducts entering the SCR in exhaust bank 1.";
CM_ BO_ 2566733822 "This message contains SCR catalyst exhaust gas pressure information for aftertreatment system 1 (or bank 1).";
CM_ SG_ 2566733822 AT1SCRIntakeAbsPress "Used to read the pressure at the catalyst intake of the selective catalytic reduction system of aftertreatment 1.";
CM_ SG_ 2566733822 AT1SCRIntakePress "The gage pressure at the intake of the selective catalytic reduction system of Aftertreatment 1.";
CM_ SG_ 2566733822 AT1SCRDiffPressPreliminaryFMI "Used to identify the applicable J1939-73 FMI detected in the SCR differential pressure sensor by the manufacturer’s sensor control software in exhaust bank 1. When there is no failure FMI 31 is sent. In the case of multiple failures the most severe ...";
CM_ SG_ 2566733822 AT1SCRDiffPress "Differential pressure measured between the intake and outlet of an SCR component in exhaust bank 1.";
CM_ BO_ 2566734078 "This message contains SCR dosing system request information for aftertreatment system 1 (or bank 1).  See PGN 61476 for more information.";
CM_ SG_ 2566734078 AT1DeselExhaustFluidLineHeater10 "The diesel exhaust fluid line heater 10 request for aftertreatment system 1 (exhaust bank 1).

00 = request for heater to be inactive
01 = request for heater to be active
10 = reserved for future assignment by SAE
11 = not available";
CM_ SG_ 2566734078 AT1DieselExhaustFluidLineHeater9 "The diesel exhaust fluid line heater 9 request for aftertreatment system 1 (exhaust bank 1).

00 = request for heater to be inactive
01 = request for heater to be active
10 = reserved for future assignment by SAE
11 = not available";
CM_ SG_ 2566734078 AT1DieselExhaustFluidLineHeater8 "The diesel exhaust fluid line heater 8 request for aftertreatment system 1 (exhaust bank 1).

00 = request for heater to be inactive
01 = request for heater to be active
10 = reserved for future assignment by SAE
11 = not available";
CM_ SG_ 2566734078 AT1DieselExhaustFluidLineHeater7 "The diesel exhaust fluid line heater 7 request for aftertreatment system 1 (exhaust bank 1).

00 = request for heater to be inactive
01 = request for heater to be active
10 = reserved for future assignment by SAE
11 = not available";
CM_ SG_ 2566734078 AT1DieselExhaustFluidLineHeater6 "The diesel exhaust fluid line heater 6 request for aftertreatment system 1 (exhaust bank 1).

00 = request for heater to be inactive
01 = request for heater to be active
10 = reserved for future assignment by SAE
11 = not available";
CM_ SG_ 2566734078 AT1DieselExhaustFluidLineHeater5 "The diesel exhaust fluid line heater 5 request for aftertreatment system 1 (exhaust bank 1).

00 = request for heater to be inactive
01 = request for heater to be active
10 = reserved for future assignment by SAE
11 = not available";
CM_ SG_ 2566734078 AT1DslExhstFluidLineHeaterRelay3 "The aftertreatment diesel exhaust fluid line heater relay 3 is used to energize one or more DEF line heaters.

00 - Off
01 - On
10 - Error
11 - Not available";
CM_ SG_ 2566734078 AT1DslExhstFluidLineHeaterRelay2 "The Aftertreatment Diesel Exhaust Fluid Line Heater Relay 2 is used to energize one or more DEF line heaters.

00 - Off
01 - On
10 - Error
11 - Not available";
CM_ SG_ 2566734078 AT1DslExhstFluidLineHeaterRelay1 "The Aftertreatment Diesel Exhaust Fluid Line Heater Relay 1 is used to energize one or more DEF line heaters.

00 - Off
01 - On
10 - Error
11 - Not available";
CM_ SG_ 2566734078 AT1DselExhaustFluidPumpHeaterCmd "Command for the Aftertreatment 1 Diesel Exhaust Fluid Pump Heater. A value of 0% means no heating commanded, a value of 100% means full heating commanded. See SPN 5706 for the measured value of the Aftertreatment 1 Diesel Exhaust Fluid Heater.";
CM_ SG_ 2566734078 AT1DslExhstFldQuickThawHeaterCmd "The command for the heater of the diesel exhaust fluid quick thaw tank for aftertreatment system 1 (exhaust bank 1).  See SPN 4372 for the measured heater percentage for the heater of this same tank.";
CM_ SG_ 2566734078 AT1DselExhaustFluidTankHeaterCmd "Command for the Aftertreatment 1 Diesel Exhaust Fluid Tank Heater.  A value of 0% means no heating applied, a value of 100% means full heating applied.  See SPN 3363 for the measured value of the Aftertreatment 1 Diesel Exhaust Fluid Tank Heater.";
CM_ SG_ 2566734078 AT1DieselExhaustFluidLineHeater4 "The diesel exhaust fluid line heater 4 request for aftertreatment system 1 (exhaust bank 1).
 
00 request for heater to be inactive 
01 request for heater to be active 
10 reserved for future assignment by SAE 
11 not available";
CM_ SG_ 2566734078 AT1DieselExhaustFluidLineHeater3 "The diesel exhaust fluid line heater 3 request for aftertreatment system 1 (exhaust bank 1).
 
00 request for heater to be inactive 
01 request for heater to be active 
10 reserved for future assignment by SAE 
11 not available";
CM_ SG_ 2566734078 AT1DieselExhaustFluidLineHeater2 "The diesel exhaust fluid line heater 2 request for aftertreatment system 1 (exhaust bank 1).
 
00 request for heater to be inactive 
01 request for heater to be active 
10 reserved for future assignment by SAE 
11 not available";
CM_ SG_ 2566734078 AT1DieselExhaustFluidLineHeater1 "The diesel exhaust fluid line heater 1 request for aftertreatment system 1 (exhaust bank 1).
 
00 request for heater to be inactive 
01 request for heater to be active 
10 reserved for future assignment by SAE 
11 not available";
CM_ SG_ 2566734078 AT1DslExhstFldDoserHeatingModeRq "Used if multiple heater modes are available in the Doser.

000   Heater off
001   Heater economy mode
010   Heater automatic mode
011   Heater on
100 - 110    Reserved
111   Not available";
CM_ SG_ 2566734078 AT1DslExhstFldDsrFltSppressionRq "Used if external devices can warn of conditions that require suppression of potential faults in the doser due to environmental conditions.

00    Error suppression off
01    Error suppression on
10    Reserved
11    Not available";
CM_ BO_ 2364548350 "This message contains SCR dosing system request information for aftertreatment system 1 (or bank 1).  See PGN 64832 for more information.";
CM_ SG_ 2364548350 AT1DslExhstFldDsngRqstedQuan6593 "Requested dosing quantity of diesel exhaust fluid. This SPN is a high range measurement. See SPN 4348 if high range is not needed.";
CM_ SG_ 2364548350 AT1DslExhstFldDsngTstInjctnPrmss "After a request to permit the DEF dosing test injection has been indicated, this permission status is expected by the DEF control unit for aftertreatment system 1.
00 = not allowed
01 = DEF dosing test injection allowed
10 = error
11 = not ...";
CM_ SG_ 2364548350 AT1DslExhstFldHydStffnssChckPrms "After a request to permit the DEF hydraulic stiffness check has been indicated, this permission status is expected by the DEF control unit for aftertreatment system 1.
00 = not allowed
01 = DEF hydraulic stiffness check allowed
10 = error
11 = ...";
CM_ SG_ 2364548350 AT1DslExhstFldRqstdQnttyOfIntgrt "Represents the command for the diesel exhaust fluid quantity integrator in the dosing control unit";
CM_ SG_ 2364548350 AT1SCRSystemRequestedState "Requested state of SCR system for aftertreatment system 1 (exhaust bank 1).
0000 Dormant (sleep mode)
0001 Preparing dosing readiness (wake up; prepare to operate; wait for start)
0010 Normal dosing operation
0011 System error pending
0100 ...";
CM_ SG_ 2364548350 AT1DslExhstFldDsngRqstedQuantity "Actual requested dosing quantity of diesel exhaust fluid.";
CM_ BO_ 2566734334 "This message contains SCR dosing system information for aftertreatment system 1 (or bank 1).  See PGN 61475 for more information.";
CM_ SG_ 2566734334 AT1DslExhstFldLnHtr4PrlminaryFMI "Used to identify the applicable J1939-73 FMI detected in the diesel exhaust fluid line heater 4, by the manufacturer’s control software in exhaust bank 1. When there is no failure FMI 31 is sent. In the case of multiple failures the most severe is ...";
CM_ SG_ 2566734334 AT1DslExhstFluidLineHeater4State "The diesel exhaust fluid line heater 4 state for aftertreatment system 1 (exhaust bank 1). 

00 heater inactive 
01 heater active 
10 error 
11 not available";
CM_ SG_ 2566734334 AT1DslExhstFldLnHtr3PrlminaryFMI "Used to identify the applicable J1939-73 FMI detected in the diesel exhaust fluid line heater 3, by the manufacturer’s control software in exhaust bank 1. When there is no failure FMI 31 is sent. In the case of multiple failures the most severe is ...";
CM_ SG_ 2566734334 AT1DslExhstFluidLineHeater3State "The diesel exhaust fluid line heater 3 state for aftertreatment system 1 (exhaust bank 1). 

00 heater inactive 
01 heater active 
10 error 
11 not available";
CM_ SG_ 2566734334 AT1DslExhstFldLnHtr2PrlminaryFMI "Used to identify the applicable J1939-73 FMI detected in the diesel exhaust fluid line heater 2, by the manufacturer’s control software in exhaust bank 1. When there is no failure FMI 31 is sent. In the case of multiple failures the most severe is ...";
CM_ SG_ 2566734334 AT1DslExhstFluidLineHeater2State "The diesel exhaust fluid line heater 2 state for aftertreatment system 1 (exhaust bank 1). 
 
00 heater inactive 
01 heater active 
10 error 
11 not available";
CM_ SG_ 2566734334 AT1DslExhstFldLnHtr1PrlminaryFMI "Used to identify the applicable J1939-73 FMI detected in the diesel exhaust fluid line heater 1, by the manufacturer’s control software in exhaust bank 1. When there is no failure FMI 31 is sent. In the case of multiple failures the most severe is ...";
CM_ SG_ 2566734334 AT1DslExhstFluidLineHeater1State "The diesel exhaust fluid line heater 1 state for aftertreatment system 1 (exhaust bank 1). 

00 heater inactive 
01 heater active 
10 error 
11 not available";
CM_ SG_ 2566734334 AT1SCRFeedbackCtrlStatus "The SCR feedback control status (open/closed loop) for aftertreatment system 1 (exhaust bank 1).
000 open loop control active
001 closed loop control active
010 reserved for future assignment by SAE
011 reserved for future assignment by SAE
100 ...";
CM_ SG_ 2566734334 AT1SCRDsngVlvExhstTmpReductionRq "Protection request for the dosing valve of the SCR-system to prevent overheating
000:    no request
001:    reduction request stage 1
010:    reduction request stage 2
011:    reserved for future assignment by SAE
100:    reserved for future ...";
CM_ SG_ 2566734334 AT1DieselExhaustFluidDoser1Temp "The temperature (measured closest to dosing valve) of the first or only DEF dosing unit for aftertreatment system 1 (exhaust bank 1).";
CM_ SG_ 2566734334 AT1SCRDosingAirAssistValve "The position of the valve used to regulate the air supply of an air assist SCR dosing system for an engine. 0% represents no supply and 100% is full supply.";
CM_ SG_ 2566734334 AT1SCRDosingAirAssistAbsPress "The SCR dosing system air assist absolute pressure for aftertreatment system 1 (exhaust bank 1).  The air assist system is used to improve the dosed reagent atomization.";
CM_ BO_ 2364548094 "This message contains SCR dosing system information for aftertreatment system 1 (or bank 1).  See PGN 64833 for more information.";
CM_ SG_ 2364548094 AT1DslExhaustFluidDoser1AbsPress "The absolute pressure (measured closest to dosing valve) of the first or only DEF dosing unit for aftertreatment system 1 (exhaust bank 1).";
CM_ SG_ 2364548094 AT1DslExhstFldActlDosingQuan6595 "Actual dosing quantity of diesel exhaust fluid. See SPN 4331 if high range measurement is not needed.";
CM_ SG_ 2364548094 AT1DslExhstFldActlQnttyOfIntgrtr "The SCR requested diesel exhaust fluid integrator total quantity for aftertreatment system 1 (exhaust bank 1).";
CM_ SG_ 2364548094 AT1SCRSystem2State "Actual state of SCR system 2
0000 = Dormant (sleep mode)
0001 = Preparing dosing readiness (wake up; prepare to operate; wait for start)
0010 = Normal dosing operation
0011 = System error pending
0100 = Purging (SCR dosing system is removing ...";
CM_ SG_ 2364548094 AT1SCRSystem1State "Actual state of SCR system
0000    Dormant (sleep mode)
0001    Preparing dosing readiness (wake up; prepare to operate; wait for start)
0010    Normal dosing operation
0011    System error pending
0100    Purging (SCR dosing system is removing ...";
CM_ SG_ 2364548094 AT1DslExhstFldActlDosingQuantity "Actual reducing agent quantity of SCR-system";
CM_ BO_ 2364548606 "This message contains aftertreatment outlet ammonia information for aftertreatment system 1 (or bank 1).";
CM_ SG_ 2364548606 AT1OutletNH3GasSensorHeaterCtrl "Indicates the heater status in the warm-up process. Upon receiving a power-up command, the NH3 gas sensor ramps up according to a manufacturer defined profile. The Preheat 1, Preheat 2, and Automatic messages are regions within this profile in ...";
CM_ SG_ 2364548606 AT1OtltNH3GsSnsrHtrPrliminaryFMI "Used to identify the applicable J1939-73 FMI detected in the heater of the outlet NH3 exhaust gas sensor by the manufacturer’s sensor control software in exhaust bank 1. When there is no failure FMI 31 is sent. In the case of multiple failures the ...";
CM_ SG_ 2364548606 AT1OutletNH3GasSensorAtTemp "Indicates that the heater element of the aftertreatment outlet NH3 gas sensor is within the manufacturer’s specified range for accurate measurements in exhaust bank 1.
00 - Heater element is not in range
01 - Heater element is in range
10 - Error
 ...";
CM_ SG_ 2364548606 AT1OtletNH3GasSensorPowerInRange "Indicates that the power supplied to the aftertreatment outlet NH3 gas sensor is within the manufacturer’s specification in exhaust bank 1.

00 - Power is not in range
01 - Power is in range
10 - Error
11 - Not available";
CM_ SG_ 2364548606 AT1OutletNH3ReadingStable "Indicates that the NH3 reading of the aftertreatment outlet NH3 sensor is stable as determined by the manufacturer’s control software in exhaust bank 1.

00 - Reading is not stable
01 - Reading is stable
10 - Error
11 - Not available";
CM_ SG_ 2364548606 AT1OutletNH3SensorPreliminaryFMI "Used to identify the applicable J1939-73 FMI detected in the aftertreatment outlet NH3 sensor by the manufacturer’s sensor control software in exhaust bank 1. When there is no failure FMI 31 is sent. In the case of multiple failures the most severe ...";
CM_ SG_ 2364548606 AT1OutletNH3 "The amount of NH3 in the exhaust exiting the aftertreatment system measured by a NH3 sensor at the aftertreatment outlet, represented in NH3 molecule parts per million non-NH3 molecules in exhaust bank 1.";
CM_ BO_ 2566726398 "The purpose of this PGN is to group the aftertreatment gas oxidation catalyst data for bank 1. These values include the intake temperature, outlet temperature and differential pressure as well as the associated preliminary FMIs.  The gas parameters ...";
CM_ SG_ 2566726398 AT1GsOxdtnCtlystDffPrssPrlmnryFM "Used to identify the applicable J1939-73 FMI detected in the gas oxidation catalyst differential pressure sensor by the manufacturer’s sensor control software in exhaust bank 1. When there is no failure FMI 31 is sent. In the case of multiple ...";
CM_ SG_ 2566726398 AT1GsOxdtnCtlystOtltTmpPrlmnryFM "Used to identify the applicable J1939-73 FMI detected in the gas oxidation catalyst outlet temperature sensor by the manufacturer’s sensor control software in exhaust bank 1. When there is no failure FMI 31 is sent. In the case of multiple failures ...";
CM_ SG_ 2566726398 AT1GsOxdtnCtlystIntkTmpPrlmnryFM "Used to identify the applicable J1939-73 FMI detected in the gas oxidation catalyst intake temperature sensor by the manufacturer’s sensor control software in exhaust bank 1. When there is no failure FMI 31 is sent. In the case of multiple failures ...";
CM_ SG_ 2566726398 AT1GasOxidationCatalystDiffPress "Exhaust differential pressure measured between the intake and exhaust of the gas oxidation catalyst in exhaust bank 1.  This parameter should be used with engines fueled by gaseous fuel like natural gas or propane.  A separate parameter has been ...";
CM_ SG_ 2566726398 AT1GsOxidationCatalystOutletTemp "Temperature of engine combustion byproducts leaving the gas oxidation catalyst in exhaust bank 1.  This parameter should be used with engines fueled by gaseous fuel like natural gas or propane.  A separate parameter has been defined for diesel ...";
CM_ SG_ 2566726398 AT1GsOxidationCatalystIntakeTemp "Temperature of engine combustion byproducts entering the gas oxidation catalyst in exhaust bank 1.  This parameter should be used with engines fueled by gaseous fuel like natural gas or propane.  A separate parameter has been defined for diesel ...";
CM_ BO_ 2365415678 "HB1C provides the system specific individual B1 failure counters, when supported by the system.";
CM_ SG_ 2365415678 SPN1 "This 19-bit number is used to identify the item for which diagnostics are being reported.";
CM_ SG_ 2365415678 FailureModeIdentifier1 "The FMI defines the type of failure detected in the subsystem identified by an SPN.";
CM_ SG_ 2365415678 FailureSpecificB1Counter "The Failure Specific B1 Counter provides an individual B1 counter";
CM_ SG_ 2365415678 SPN1High "SPN #1 (Conversion Version 4)";
CM_ BO_ 2365415934 "HCMI provides the system specific cumulative.";
CM_ SG_ 2365415934 SysGreatestB1Counter "System Greatest B1 Counter";
CM_ SG_ 2365415934 SysCumulativeContinuousMITime "System Cumulative Continuous MI Time";
CM_ BO_ 2365416190 "HGRD provides a description of the UN/ECE WWH OBD Global Technical Regulation (GTR) to which the sub-system or
component complies.";
CM_ SG_ 2365416190 RegulationDescription "Global Technical Regulation Description";
CM_ BO_ 2365416446 "HRWS reports subsystem (or component) roadworthiness to the VOBD function to aggregate in the HRWV message.";
CM_ SG_ 2365416446 SysIncompleteMonitorCount "System Incomplete Monitor Count";
CM_ SG_ 2365416446 SysMalIndActivationMode "System Malfunction Indicator Status";
CM_ SG_ 2365416446 SysMalIndDisplayStrategy "System Malfunction Indicator Display";
CM_ SG_ 2365416446 SysContinuousMalfunctionInd "System Continuous Malfunction Indicator";
CM_ SG_ 2365416446 SysNonRoadworthyCompCount "System Non-Roadworthy Component Count";
CM_ BO_ 2365416702 "HRWV provides the aggregated roadworthiness from the VOBD (Vehicle On-Board Diagnostics) to a scan tool or similar inquiry device.";
CM_ SG_ 2365416702 VehicleCurrentMIAccumTime "Vehicle current malfunction indicator accumulated time reports the accumulated count (in minutes) that the malfunction indicator lamp (MIL) is activated (on) for the current malfunction indicator (MI) activation (or the last MI activation).
For US, ...";
CM_ SG_ 2365416702 VehicleIncompleteMonitorCount "Vehicle Incomplete Monitor Count";
CM_ SG_ 2365416702 VehicleMalfunctionIndActMode "Vehicle Malfunction Indicator Status ";
CM_ SG_ 2365416702 VehicleMalfunctionIndStrategy "Vehicle Malfunction Indicator Display Strategy ";
CM_ SG_ 2365416702 VehicleContinuousMalfunctionInd "Vehicle Continuous Malfunction Indicator";
CM_ SG_ 2365416702 VehicleNonRoadworthyCompCount "Vehicle Non-Roadworthy Component Count";
CM_ BO_ 2359361278 "The status of engine operating in the NTE control areas for given pollutants, such as NOx and PM.";
CM_ SG_ 2359361278 PMNTEDeficiencyAreaStatus "Status of engine operation within the PM NTE Deficiency Area.  The PM NTE Deficiency Area is defined as bounded regions or conditions within the NTE control area for PM where the manufacturer has received a deficiency.  If the application does not ...";
CM_ SG_ 2359361278 MnfcPMNTECarveOutAreaStatus "Status of engine operation within the manufacturer specific PM NTE limited testing region.  The manufacturer specific PM NTE  limited testing region is defined as bounded regions within the NTE control area for PM where the manufacturer has limited ...";
CM_ SG_ 2359361278 PMNTEControlAreaStatus "Status of engine operation within the bounded region of the engine’s torque and speed map where emissions must not exceed a specific emission cap for PM under the NTE requirement.";
CM_ SG_ 2359361278 NOxNTEDeficiencyAreaStatus "Status of engine operation within the NOx NTE Deficiency Area.  The NOx NTE Deficiency Area is defined as bounded regions or conditions within the NTE control area for NOx where the manufacturer has received a deficiency.  If the application does ...";
CM_ SG_ 2359361278 MnfcNOxNTECarveOutAreaStatus "Status of engine operation within the manufacturer specific NOx NTE limited testing region.  The manufacturer specific NOx NTE limited testing region is defined as bounded regions within the NTE control area for NOx where the manufacturer has ...";
CM_ SG_ 2359361278 NOxNTEControlAreaStatus "Status of engine operation within the bounded region of the engine’s torque and speed map where emissions must not exceed a specific emission cap for NOx under the NTE requirement.";
CM_ BO_ 2292317950 "The total engine run time while each of the Emission Increasing Auxiliary Emission Control Devices (EI-AECDs) is active.";
CM_ SG_ 2292317950 AECDEngineHours1Timer2 "The total engine running hours recorded in the second timer for the EI-AECD";
CM_ SG_ 2292317950 AECDEngineHours1Timer1 "The total engine running hours recorded in the first timer for the EI-AECD";
CM_ SG_ 2292317950 AECDNumber1 "The manufacturer assigned number for the specific EI-AECD";
CM_ BO_ 2566809342 "Battery Main Switch Information";
CM_ SG_ 2566809342 BatteryMainSwitchHoldState "Parameter indicating whether the battery main switch is held due to an external request or not. The state battery main switch held indicates that the battery main switch is about to switch off.
00 Battery main switch not held
01 Battery main ...";
CM_ BO_ 2365446910 "Used to transfer information about the measured status of the 1st 2 axes and up to 12 buttons of a joystick.  Additional handle information is available in the Expanded Joystick Message.
10-bit position parameters are broadcast over 2 bytes.  The ...";
CM_ SG_ 2365446910 Joystick3XAxisDetentPosStatus "Reports when the current joystick position is in the detent position for that axis of travel.

00 Not in the Detent Position
01 In the Detent Position
10 Error Indicator
11 Not Available";
CM_ SG_ 2365446910 Joystick3Button9PressedStatus "Reports when the joystick button has been pressed.

00 Button not pressed
01 Button pressed
10 Error Indicator
11 Not Available";
CM_ SG_ 2365446910 Joystick3Button10PressedStatus "Reports when the joystick button has been pressed.

00 Button not pressed
01 Button pressed
10 Error Indicator
11 Not Available";
CM_ SG_ 2365446910 Joystick3Button11PressedStatus "Reports when the joystick button has been pressed.

00 Button not pressed
01 Button pressed
10 Error Indicator
11 Not Available";
CM_ SG_ 2365446910 Joystick3Button12PressedStatus "Reports when the joystick button has been pressed.

00 Button not pressed
01 Button pressed
10 Error Indicator
11 Not Available";
CM_ SG_ 2365446910 Joystick3YAxisDetentPosStatus "Reports when the current joystick position is in the detent position for that axis of travel.

00 Not in the Detent Position
01 In the Detent Position
10 Error Indicator
11 Not Available";
CM_ SG_ 2365446910 Joystick3YAxisPos "The position of the joystick in the relative motion of travel from the neutral position.  Position value of 0 is Neutral and position value 1000 (100%) is the end of linear zone.  Value of 1022 indicates an error has occurred.";
CM_ SG_ 2365446910 Jystck3YAxsLvrFrwrdPstvPosStatus "Reports when the current joystick position is on the positive travel side (forward, right, clockwise, up) relative to the neutral position for that axis of travel.
00 Not on Positive side of Neutral
01 On positive side of Neutral
10 Error ...";
CM_ SG_ 2365446910 Jystck3YAxsLvrBckNgtivePosStatus "Reports when the current joystick position is on the negative travel side (back, left, counterclockwise, down) relative to the neutral position for that axis of travel.
00 Not on negative side of Neutral
01 On negative side of Neutral
10 Error ...";
CM_ SG_ 2365446910 Joystick3YAxisNeutralPosStatus "Reports when the current joystick position is in the neutral position for that axis of travel.  The neutral position measurement must be determined from some mechanism other than the axis position measurement device.
00 Not in Neutral Position
01 ...";
CM_ SG_ 2365446910 Joystick3XAxisPos "The position of the joystick in the relative motion of travel from the neutral position.  Position value of 0 is Neutral and position value 1000 (100%) is the end of linear zone.  Value of 1022 indicates an error has occurred.";
CM_ SG_ 2365446910 Jystck3XAxsLvrRghtPstvePosStatus "Reports when the current joystick position is on the positive travel side (forward, right, clockwise, up) relative to the neutral position for that axis of travel.
00 Not on Positive side of Neutral
01 On positive side of Neutral
10 Error ...";
CM_ SG_ 2365446910 Jystck3XAxsLvrLftNgtivePosStatus "Reports when the current joystick position is on the negative travel side (back, left, counterclockwise, down) relative to the neutral position for that axis of travel.
00 Not on negative side of Neutral
01 On negative side of Neutral
10 Error ...";
CM_ SG_ 2365446910 Joystick3XAxisNeutralPosStatus "Reports when the current joystick position is in the neutral position for that axis of travel.  The neutral position measurement must be determined from some mechanism other than the axis position measurement device.
00 Not in Neutral Position
01 ...";
CM_ SG_ 2365446910 Joystick3Button5PressedStatus "Reports when the joystick button has been pressed.

00 Button not pressed
01 Button pressed
10 Error Indicator
11 Not Available";
CM_ SG_ 2365446910 Joystick3Button6PressedStatus "Reports when the joystick button has been pressed.

00 Button not pressed
01 Button pressed
10 Error Indicator
11 Not Available";
CM_ SG_ 2365446910 Joystick3Button7PressedStatus "Reports when the joystick button has been pressed.

00 Button not pressed
01 Button pressed
10 Error Indicator
11 Not Available";
CM_ SG_ 2365446910 Joystick3Button8PressedStatus "Reports when the joystick button has been pressed.

00 Button not pressed
01 Button pressed
10 Error Indicator
11 Not Available";
CM_ SG_ 2365446910 Joystick3Button1PressedStatus "Reports when the joystick button has been pressed.

00 Button not pressed
01 Button pressed
10 Error Indicator
11 Not Available";
CM_ SG_ 2365446910 Joystick3Button2PressedStatus "Reports when the joystick button has been pressed.

00 Button not pressed
01 Button pressed
10 Error Indicator
11 Not Available";
CM_ SG_ 2365446910 Joystick3Button3PressedStatus "Reports when the joystick button has been pressed.

00 Button not pressed
01 Button pressed
10 Error Indicator
11 Not Available";
CM_ SG_ 2365446910 Joystick3Button4PressedStatus "Reports when the joystick button has been pressed.

00 Button not pressed
01 Button pressed
10 Error Indicator
11 Not Available";
CM_ BO_ 2365446398 "Used to transfer information about the measured status of the 1st 2 axes and up to 12 buttons of a joystick.  Additional handle information is available in the Expanded Joystick Message.
10-bit position parameters are broadcast over 2 bytes.  The ...";
CM_ SG_ 2365446398 Joystick2XAxisDetentPosStatus "Reports when the current joystick position is in the detent position for that axis of travel.

00 Not in the Detent Position
01 In the Detent Position
10 Error Indicator
11 Not Available";
CM_ SG_ 2365446398 Joystick2YAxisDetentPosStatus "Reports when the current joystick position is in the detent position for that axis of travel.

00 Not in the Detent Position
01 In the Detent Position
10 Error Indicator
11 Not Available";
CM_ SG_ 2365446398 Joystick2YAxisPos "The position of the joystick in the relative motion of travel from the neutral position.  Position value of 0 is Neutral and position value 1000 (100%) is the end of linear zone.  Value of 1022 indicates an error has occurred.";
CM_ SG_ 2365446398 Jystck2YAxsLvrFrwrdPstvPosStatus "Reports when the current joystick position is on the positive travel side (forward, right, clockwise, up) relative to the neutral position for that axis of travel.
00 Not on Positive side of Neutral
01 On positive side of Neutral
10 Error ...";
CM_ SG_ 2365446398 Jystck2YAxsLvrBckNgtivePosStatus "Reports when the current joystick position is on the negative travel side (back, left, counterclockwise, down) relative to the neutral position for that axis of travel.
00 Not on negative side of Neutral
01 On negative side of Neutral
10 Error ...";
CM_ SG_ 2365446398 Joystick2YAxisNeutralPosStatus "Reports when the current joystick position is in the neutral position for that axis of travel.  The neutral position measurement must be determined from some mechanism other than the axis position measurement device.
00 Not in Neutral Position
01 ...";
CM_ SG_ 2365446398 Joystick2XAxisPos "The position of the joystick in the relative motion of travel from the neutral position.  Position value of 0 is Neutral and position value 1000 (100%) is the end of linear zone.  Value of 1022 indicates an error has occurred.";
CM_ SG_ 2365446398 Jystck2XAxsLvrRghtPstvePosStatus "Reports when the current joystick position is on the positive travel side (forward, right, clockwise, up) relative to the neutral position for that axis of travel.
00 Not on Positive side of Neutral
01 On positive side of Neutral
10 Error ...";
CM_ SG_ 2365446398 Jystck2XAxsLvrLftNgtivePosStatus "Reports when the current joystick position is on the negative travel side (back, left, counterclockwise, down) relative to the neutral position for that axis of travel.
00 Not on negative side of Neutral
01 On negative side of Neutral
10 Error ...";
CM_ SG_ 2365446398 Joystick2XAxisNeutralPosStatus "Reports when the current joystick position is in the neutral position for that axis of travel.  The neutral position measurement must be determined from some mechanism other than the axis position measurement device.
00 Not in Neutral Position
01 ...";
CM_ SG_ 2365446398 Joystick2Button9PressedStatus "Reports when the joystick button has been pressed.

00 Button not pressed
01 Button pressed
10 Error Indicator
11 Not Available";
CM_ SG_ 2365446398 Joystick2Button10PressedStatus "Reports when the joystick button has been pressed.

00 Button not pressed
01 Button pressed
10 Error Indicator
11 Not Available";
CM_ SG_ 2365446398 Joystick2Button11PressedStatus "Reports when the joystick button has been pressed.

00 Button not pressed
01 Button pressed
10 Error Indicator
11 Not Available";
CM_ SG_ 2365446398 Joystick2Button12PressedStatus "Reports when the joystick button has been pressed.

00 Button not pressed
01 Button pressed
10 Error Indicator
11 Not Available";
CM_ SG_ 2365446398 Joystick2Button5PressedStatus "Reports when the joystick button has been pressed.

00 Button not pressed
01 Button pressed
10 Error Indicator
11 Not Available";
CM_ SG_ 2365446398 Joystick2Button6PressedStatus "Reports when the joystick button has been pressed.

00 Button not pressed
01 Button pressed
10 Error Indicator
11 Not Available";
CM_ SG_ 2365446398 Joystick2Button7PressedStatus "Reports when the joystick button has been pressed.

00 Button not pressed
01 Button pressed
10 Error Indicator
11 Not Available";
CM_ SG_ 2365446398 Joystick2Button8PressedStatus "Reports when the joystick button has been pressed.

00 Button not pressed
01 Button pressed
10 Error Indicator
11 Not Available";
CM_ SG_ 2365446398 Joystick2Button1PressedStatus "Reports when the joystick button has been pressed.

00 Button not pressed
01 Button pressed
10 Error Indicator
11 Not Available";
CM_ SG_ 2365446398 Joystick2Button2PressedStatus "Reports when the joystick button has been pressed.

00 Button not pressed
01 Button pressed
10 Error Indicator
11 Not Available";
CM_ SG_ 2365446398 Joystick2Button3PressedStatus "Reports when the joystick button has been pressed.

00 Button not pressed
01 Button pressed
10 Error Indicator
11 Not Available";
CM_ SG_ 2365446398 Joystick2Button4PressedStatus "Reports when the joystick button has been pressed.

00 Button not pressed
01 Button pressed
10 Error Indicator
11 Not Available";
CM_ BO_ 2365445886 "Used to transfer information about the measured status of the 1st 2 axes and up to 12 buttons of a joystick.  Additional handle information is available in the Expanded Joystick Message.
10-bit position parameters are broadcast over 2 bytes.  The ...";
CM_ SG_ 2365445886 Joystick1XAxisDetentPosStatus "Reports when the current joystick position is in the detent position for that axis of travel.

00 Not in the Detent Position
01 In the Detent Position
10 Error Indicator
11 Not Available";
CM_ SG_ 2365445886 Joystick1YAxisDetentPosStatus "Reports when the current joystick position is in the detent position for that axis of travel.

00 Not in the Detent Position
01 In the Detent Position
10 Error Indicator
11 Not Available";
CM_ SG_ 2365445886 Joystick1YAxisPos "The position of the joystick in the relative motion of travel from the neutral position.  Position value of 0 is Neutral and position value 1000 (100%) is the end of linear zone.  Value of 1022 indicates an error has occurred.";
CM_ SG_ 2365445886 Jystck1YAxsLvrFrwrdPstvPosStatus "Reports when the current joystick position is on the positive travel side (forward, right, clockwise, up) relative to the neutral position for that axis of travel.
00 Not on Positive side of Neutral
01 On positive side of Neutral
10 Error ...";
CM_ SG_ 2365445886 Jystck1YAxsLvrBckNgtivePosStatus "Reports when the current joystick position is on the negative travel side (back, left, counterclockwise, down) relative to the neutral position for that axis of travel.
00 Not on negative side of Neutral
01 On negative side of Neutral
10 Error ...";
CM_ SG_ 2365445886 Joystick1YAxisNeutralPosStatus "Reports when the current joystick position is in the neutral position for that axis of travel.  The neutral position measurement must be determined from some mechanism other than the axis position measurement device.
00 Not in Neutral Position
01 ...";
CM_ SG_ 2365445886 Joystick1XAxisPos "The position of the joystick in the relative motion of travel from the neutral position.  Position value of 0 is Neutral and position value 1000 (100%) is the end of linear zone.  Value of 1022 indicates an error has occurred.";
CM_ SG_ 2365445886 Joystick1Button9PressedStatus "Reports when the joystick button has been pressed.

00 Button not pressed
01 Button pressed
10 Error Indicator
11 Not Available";
CM_ SG_ 2365445886 Joystick1Button10PressedStatus "Reports when the joystick button has been pressed.

00 Button not pressed
01 Button pressed
10 Error Indicator
11 Not Available";
CM_ SG_ 2365445886 Joystick1Button11PressedStatus "Reports when the joystick button has been pressed.

00 Button not pressed
01 Button pressed
10 Error Indicator
11 Not Available";
CM_ SG_ 2365445886 Joystick1Button12PressedStatus "Reports when the joystick button has been pressed.

00 Button not pressed
01 Button pressed
10 Error Indicator
11 Not Available";
CM_ SG_ 2365445886 Joystick1Button5PressedStatus "Reports when the joystick button has been pressed.

00 Button not pressed
01 Button pressed
10 Error Indicator
11 Not Available";
CM_ SG_ 2365445886 Joystick1Button6PressedStatus "Reports when the joystick button has been pressed.

00 Button not pressed
01 Button pressed
10 Error Indicator
11 Not Available";
CM_ SG_ 2365445886 Joystick1Button7PressedStatus "Reports when the joystick button has been pressed.

00 Button not pressed
01 Button pressed
10 Error Indicator
11 Not Available";
CM_ SG_ 2365445886 Joystick1Button8PressedStatus "Reports when the joystick button has been pressed.

00 Button not pressed
01 Button pressed
10 Error Indicator
11 Not Available";
CM_ SG_ 2365445886 Joystick1Button1PressedStatus "Reports when the joystick button has been pressed.

00 Button not pressed
01 Button pressed
10 Error Indicator
11 Not Available";
CM_ SG_ 2365445886 Joystick1Button2PressedStatus "Reports when the joystick button has been pressed.

00 Button not pressed
01 Button pressed
10 Error Indicator
11 Not Available";
CM_ SG_ 2365445886 Joystick1Button3PressedStatus "Reports when the joystick button has been pressed.

00 Button not pressed
01 Button pressed
10 Error Indicator
11 Not Available";
CM_ SG_ 2365445886 Joystick1Button4PressedStatus "Reports when the joystick button has been pressed.

00 Button not pressed
01 Button pressed
10 Error Indicator
11 Not Available";
CM_ SG_ 2365445886 Jystck1XAxsLvrRghtPstvePosStatus "Reports when the current joystick position is on the positive travel side (forward, right, clockwise, up) relative to the neutral position for that axis of travel.
00 Not on Positive side of Neutral
01 On positive side of Neutral
10 Error ...";
CM_ SG_ 2365445886 Jystck1XAxsLvrLftNgtivePosStatus "Reports when the current joystick position is on the negative travel side (back, left, counterclockwise, down) relative to the neutral position for that axis of travel.
00 Not on negative side of Neutral
01 On negative side of Neutral
10 Error ...";
CM_ SG_ 2365445886 Joystick1XAxisNeutralPosStatus "Reports when the current joystick position is in the neutral position for that axis of travel.  The neutral position measurement must be determined from some mechanism other than the axis position measurement device.
00 Not in Neutral Position
01 ...";
CM_ BO_ 2566847230 "Brakes";
CM_ SG_ 2566847230 ParkingBrakeRedWarningSignal "This parameter commands the Parking Brake red optical warning signal.

00 – off
01 – on
10 – Reserved 
11 – Take no action";
CM_ SG_ 2566847230 ParkBrakeReleaseInhibitStatus "This parameter provides reports on the status of the Park Brake Release Inhibit function.
00 - Park Brake release is not inhibited
01 - Park Brake release is inhibited
10 - Error (for example: Park Brake release is not inhibited, but is requested ...";
CM_ SG_ 2566847230 ParkingBrakeActuator "Signal which indicates the current state of the actuator(s) that control the parking brake (see also SPN 70 and 5275).

00 - Parking brake actuator inactive
01 - Parking brake actuator active
10 - Error
11 - Not available";
CM_ SG_ 2566847230 BrakeSecondPress "Gage pressure of air in the secondary, or service side, of the air brake system.";
CM_ SG_ 2566847230 BrakePrimaryPress "Gage pressure of air in the primary, or supply side, of the air brake system.";
CM_ SG_ 2566847230 BrakeAppPress "Gage pressure of compressed air or fluid in vehicle braking system measured at the brake chamber when brake shoe (or pad) is placed against brake drum (or disc).";
CM_ BO_ 2566848254 "Auxiliary Water Pump Pressure";
CM_ SG_ 2566848254 AuxPumpPress "Gage pressure of auxiliary water pump driven as a PTO device.";
CM_ BO_ 2566725886 "The purpose of this PGN is to group the aftertreatment diesel oxidation catalyst data for bank 1. These values include the intake temperature, outlet temperature and differential pressure as well as the associated preliminary FMIs.  The diesel ...";
CM_ SG_ 2566725886 AT1DslOxdtnCtlystDffPrssPrlmnryF "Used to identify the applicable J1939-73 FMI detected in the diesel oxidation catalyst differential pressure sensor by the manufacturer’s sensor control software in exhaust bank 1. When there is no failure FMI 31 is sent. In the case of multiple ...";
CM_ SG_ 2566725886 AT1DslOxdtnCtlystOtltTmpPrlmnryF "Used to identify the applicable J1939-73 FMI detected in the diesel oxidation catalyst outlet gas temperature sensor by the manufacturer’s sensor control software in exhaust bank 1. When there is no failure FMI 31 is sent. In the case of multiple ...";
CM_ SG_ 2566725886 AT1DslOxdtnCtlystIntkTmpPrlmnryF "Used to identify the applicable J1939-73 FMI detected in the diesel oxidation catalyst intake temperature sensor by the manufacturer’s sensor control software in exhaust bank 1. When there is no failure FMI 31 is sent. In the case of multiple ...";
CM_ SG_ 2566725886 AT1DslOxidationCatalystDiffPress "Exhaust differential pressure measured between the intake and exhaust of a diesel oxidation catalyst in exhaust bank 1.  This parameter should be used with engines fueled by diesel fuel (not gaseous fuel like natural gas or propane).  A separate ...";
CM_ SG_ 2566725886 AT1DslOxdationCatalystOutletTemp "Temperature of engine combustion byproducts leaving the diesel oxidation catalyst exhaust in exhaust bank 1.  This parameter should be used with engines fueled by diesel fuel (not gaseous fuel like natural gas or propane).  A separate parameter has ...";
CM_ SG_ 2566725886 AT1DslOxdationCatalystIntakeTemp "Temperature of engine combustion byproducts entering the diesel oxidation catalyst in exhaust bank 1.  This parameter should be used with engines fueled by diesel fuel (not gaseous fuel like natural gas or propane).  A separate parameter has been ...";
CM_ BO_ 2359557886 "This message shall provide the applicable lamp(s) for each individual DTC";
CM_ SG_ 2359557886 DTCWarnLampSupportStatus "Lamp support status";
CM_ SG_ 2359557886 DTCWarnLampSupportFlash "Lamp support status";
CM_ SG_ 2359557886 DTCStopLampSupportStatus "Lamp support status";
CM_ SG_ 2359557886 DTCStopLampSupportFlash "Lamp support status";
CM_ SG_ 2359557886 DTCProtectLampSupportStatus "Lamp support status";
CM_ SG_ 2359557886 DTCProtectLampSupportFlash "Lamp support status";
CM_ SG_ 2359557886 DTCMilSupportStatus "Lamp support status";
CM_ SG_ 2359557886 DTCMilSupportFlash "Lamp support status";
CM_ SG_ 2359557886 DTC1 "Diagnostic Trouble Code";
CM_ BO_ 2633844734 "ASCII text string describing a manufacturer-specific Transmission Mode.  This PGN may contain up to 8 instances of the Transmission Mode Label field (for Transmission Mode 1 through Transmission Mode 8) with each separated by the asterisk (*) ...";
CM_ SG_ 2633844734 TransModeLabel8 "Conveys ASCII ‘labels’ for each of the manufacturer-specified TC1 Transmission Mode ’x’ / ETC7 Transmission Mode ...";
CM_ SG_ 2633844734 TransModeLabel7 "Conveys ASCII ‘labels’ for each of the manufacturer-specified TC1 Transmission Mode ’x’ / ETC7 Transmission Mode ...";
CM_ SG_ 2633844734 TransModeLabel6 "Conveys ASCII ‘labels’ for each of the manufacturer-specified TC1 Transmission Mode ’x’ / ETC7 Transmission Mode ...";
CM_ SG_ 2633844734 TransModeLabel5 "Conveys ASCII ‘labels’ for each of the manufacturer-specified TC1 Transmission Mode ’x’ / ETC7 Transmission Mode ...";
CM_ SG_ 2633844734 TransModeLabel4 "Conveys ASCII ‘labels’ for each of the manufacturer-specified TC1 Transmission Mode ’x’ / ETC7 Transmission Mode ...";
CM_ SG_ 2633844734 TransModeLabel3 "Conveys ASCII ‘labels’ for each of the manufacturer-specified TC1 Transmission Mode ’x’ / ETC7 Transmission Mode ...";
CM_ SG_ 2633844734 TransModeLabel2 "Conveys ASCII ‘labels’ for each of the manufacturer-specified TC1 Transmission Mode ’x’ / ETC7 Transmission Mode ...";
CM_ SG_ 2633844734 TransModeLabel "Conveys ASCII ‘labels’ for each of the manufacturer-specified TC1 Transmission Mode ’x’ / ETC7 Transmission Mode Indicator ‘x’ pairs.  Intended for use with on-board or service tool displays.
NOTE – Non-printable or non-graphic ASCII characters are ...";
CM_ BO_ 2560360190 "This is a standardized mechanism for an ECU to report a listing of the manufacturer specific (i.e. proprietary) methods and formats it supports when using the PropA, PropA2, and PropB PGNs (see J1939-21).  The ability to support multiple ...";
CM_ SG_ 2560360190 DataDictionaryMethod "A manufacturer defined code to define the proprietary communications method.  The structure and interpretation of the code is manufacturer specific.  This allows manufacturers to establish their own methods for reporting proprietary support for ...";
CM_ SG_ 2560360190 DataDictionaryManufacturerCode "The J1939 Manufacturer Code (see J1939 Table B10) associated with the manufacturer who defined the proprietary communications method.  0x7FF reserved for \"Not Available\"";
CM_ BO_ 2566736126 "Provides bank 2 short-term and long-term fuel trim values";
CM_ SG_ 2566736126 EngExhstGsOxygnSnsrClsdLpOprtnBn "This parameter indicates the status of the bank 2 O2 sensor feedback closed loop operation
0000 = Open loop - has not yet satisfied conditions to go closed loop
0001 = Closed loop - using oxygen sensor(s) as feedback for fuel control
0010 = Open ...";
CM_ SG_ 2566736126 ShorttermFuelTrimBank2 "This parameter is the short-term percent change in fueling based on the O2 sensor feedback for cylinder bank 2, based on the operating point in the nominal fuel map.";
CM_ SG_ 2566736126 LongtermFuelTrimBank2 "This parameter is the long-term percent change in fueling based on the O2 sensor feedback for cylinder bank 2, based on the operating point in the nominal fuel map.";
CM_ BO_ 2566736382 "Provides bank 1 short-term and long-term fuel trim values";
CM_ SG_ 2566736382 EngExhstGsOxygnSnsrClsdLpOprtnBn "This parameter indicates the status of the bank 1 O2 sensor feedback closed loop operation
0000 = Open loop - has not yet satisfied conditions to go closed loop
0001 = Closed loop - using oxygen sensor(s) as feedback for fuel control
0010 = Open ...";
CM_ SG_ 2566736382 ShorttermFuelTrimBank1 "This parameter is the short-term percent change in fueling based on the O2 sensor feedback for cylinder bank 1, based on the operating point in the nominal fuel map.

Note:  This is similar to SPN 1695, but with higher resolution.";
CM_ SG_ 2566736382 LongtermFuelTrimBank1 "This parameter is the long-term percent change in fueling based on the O2 sensor feedback for cylinder bank 1, based on the operating point in the nominal fuel map.";
BA_DEF_ SG_  "SigType" ENUM  "Default","Range","RangeSigned","ASCII","Discrete","Control","ReferencePGN","DTC","StringDelimiter","StringLength","StringLengthControl","MessageCounter","MessageChecksum";
BA_DEF_ SG_  "GenSigStartValue" INT 0 10000;
BA_DEF_ SG_  "GenSigSendType" ENUM  "Cyclic","OnWrite","OnWriteWithRepetition","OnChange","OnChangeWithRepetition","IfActive","IfActiveWithRepetition","NoSigSendType";
BA_DEF_ SG_  "GenSigILSupport" ENUM  "No","Yes";
BA_DEF_ SG_  "GenSigEVName" STRING ;
BA_DEF_ SG_  "SPN" INT 0 524287;
BA_DEF_ BO_  "TpJ1939VarDlc" ENUM  "No","Yes";
BA_DEF_ BO_  "GenMsgStartDelayTime" INT 0 100000;
BA_DEF_ BO_  "GenMsgILSupport" ENUM  "No","Yes";
BA_DEF_ BO_  "GenMsgDelayTime" INT 0 1000;
BA_DEF_ BO_  "GenMsgRequestable" INT 0 1;
BA_DEF_ BO_  "GenMsgSendType" ENUM  "cyclic","NotUsed","NotUsed","NotUsed","NotUsed","NotUsed","NotUsed","IfActive","noMsgSendType";
BA_DEF_ BO_  "VFrameFormat" ENUM  "StandardCAN","ExtendedCAN","reserved","J1939PG";
BA_DEF_ BO_  "GenMsgCycleTime" INT 0 3600000;
BA_DEF_ SG_  "SystemSignalLongSymbol" STRING ;
BA_DEF_DEF_  "SigType" "Default";
BA_DEF_DEF_  "GenSigStartValue" 0;
BA_DEF_DEF_  "GenSigSendType" "NoSigSendType";
BA_DEF_DEF_  "GenSigILSupport" "Yes";
BA_DEF_DEF_  "GenSigEVName" "Env@Nodename_@Signame";
BA_DEF_DEF_  "SPN" 0;
BA_DEF_DEF_  "TpJ1939VarDlc" "No";
BA_DEF_DEF_  "GenMsgStartDelayTime" 0;
BA_DEF_DEF_  "GenMsgILSupport" "Yes";
BA_DEF_DEF_  "GenMsgDelayTime" 0;
BA_DEF_DEF_  "GenMsgRequestable" 1;
BA_DEF_DEF_  "GenMsgSendType" "noMsgSendType";
BA_DEF_DEF_  "VFrameFormat" "J1939PG";
BA_DEF_DEF_  "GenMsgCycleTime" 0;
BA_DEF_DEF_  "SystemSignalLongSymbol" "";
BA_ "GenMsgCycleTime" BO_ 2566735614 500;
BA_ "GenMsgSendType" BO_ 2566735614 0;
BA_ "GenMsgCycleTime" BO_ 2566805246 1000;
BA_ "GenMsgSendType" BO_ 2566805246 0;
BA_ "GenMsgCycleTime" BO_ 2365394942 1000;
BA_ "GenMsgSendType" BO_ 2365394942 0;
BA_ "GenMsgCycleTime" BO_ 2365395454 1000;
BA_ "GenMsgSendType" BO_ 2365395454 0;
BA_ "GenMsgCycleTime" BO_ 2566711806 100;
BA_ "GenMsgSendType" BO_ 2566711806 0;
BA_ "GenMsgCycleTime" BO_ 2364549886 10;
BA_ "GenMsgSendType" BO_ 2364549886 0;
BA_ "GenMsgCycleTime" BO_ 2566712318 1000;
BA_ "GenMsgSendType" BO_ 2566712318 0;
BA_ "GenMsgCycleTime" BO_ 2566712574 1000;
BA_ "GenMsgSendType" BO_ 2566712574 0;
BA_ "GenMsgCycleTime" BO_ 2566731006 1000;
BA_ "GenMsgSendType" BO_ 2566731006 0;
BA_ "GenMsgCycleTime" BO_ 2566731262 1000;
BA_ "GenMsgSendType" BO_ 2566731262 0;
BA_ "GenMsgCycleTime" BO_ 2566730750 1000;
BA_ "GenMsgSendType" BO_ 2566730750 0;
BA_ "GenMsgCycleTime" BO_ 2566731518 1000;
BA_ "GenMsgSendType" BO_ 2566731518 0;
BA_ "GenMsgCycleTime" BO_ 2566732030 500;
BA_ "GenMsgSendType" BO_ 2566732030 0;
BA_ "GenMsgCycleTime" BO_ 2566732286 500;
BA_ "GenMsgSendType" BO_ 2566732286 0;
BA_ "GenMsgCycleTime" BO_ 2164079358 500;
BA_ "GenMsgSendType" BO_ 2164079358 0;
BA_ "GenMsgCycleTime" BO_ 2364549118 50;
BA_ "GenMsgSendType" BO_ 2364549118 0;
BA_ "GenMsgCycleTime" BO_ 2566732798 500;
BA_ "GenMsgSendType" BO_ 2566732798 0;
BA_ "GenMsgCycleTime" BO_ 2364548862 50;
BA_ "GenMsgSendType" BO_ 2364548862 0;
BA_ "GenMsgCycleTime" BO_ 2364549374 50;
BA_ "GenMsgSendType" BO_ 2364549374 0;
BA_ "GenMsgCycleTime" BO_ 2566726142 500;
BA_ "GenMsgSendType" BO_ 2566726142 0;
BA_ "GenMsgCycleTime" BO_ 2566725630 500;
BA_ "GenMsgSendType" BO_ 2566725630 0;
BA_ "GenMsgCycleTime" BO_ 2566733310 1000;
BA_ "GenMsgSendType" BO_ 2566733310 0;
BA_ "GenMsgCycleTime" BO_ 2566733054 1000;
BA_ "GenMsgSendType" BO_ 2566733054 0;
BA_ "GenMsgCycleTime" BO_ 2499624702 500;
BA_ "GenMsgSendType" BO_ 2499624702 0;
BA_ "GenMsgCycleTime" BO_ 2566733822 500;
BA_ "GenMsgSendType" BO_ 2566733822 0;
BA_ "GenMsgCycleTime" BO_ 2566734078 500;
BA_ "GenMsgSendType" BO_ 2566734078 0;
BA_ "GenMsgCycleTime" BO_ 2364548350 50;
BA_ "GenMsgSendType" BO_ 2364548350 0;
BA_ "GenMsgCycleTime" BO_ 2566734334 500;
BA_ "GenMsgSendType" BO_ 2566734334 0;
BA_ "GenMsgCycleTime" BO_ 2364548094 50;
BA_ "GenMsgSendType" BO_ 2364548094 0;
BA_ "GenMsgCycleTime" BO_ 2364548606 50;
BA_ "GenMsgSendType" BO_ 2364548606 0;
BA_ "GenMsgCycleTime" BO_ 2566726398 500;
BA_ "GenMsgSendType" BO_ 2566726398 0;
BA_ "GenMsgCycleTime" BO_ 2566809342 1000;
BA_ "GenMsgSendType" BO_ 2566809342 0;
BA_ "GenMsgCycleTime" BO_ 2365446910 100;
BA_ "GenMsgSendType" BO_ 2365446910 0;
BA_ "GenMsgDelayTime" BO_ 2365446910 20;
BA_ "GenMsgCycleTime" BO_ 2365446398 100;
BA_ "GenMsgSendType" BO_ 2365446398 0;
BA_ "GenMsgDelayTime" BO_ 2365446398 20;
BA_ "GenMsgCycleTime" BO_ 2365445886 100;
BA_ "GenMsgSendType" BO_ 2365445886 0;
BA_ "GenMsgDelayTime" BO_ 2365445886 20;
BA_ "GenMsgCycleTime" BO_ 2566847230 1000;
BA_ "GenMsgSendType" BO_ 2566847230 0;
BA_ "GenMsgCycleTime" BO_ 2566848254 1000;
BA_ "GenMsgSendType" BO_ 2566848254 0;
BA_ "GenMsgCycleTime" BO_ 2566725886 500;
BA_ "GenMsgSendType" BO_ 2566725886 0;
BA_ "TpJ1939VarDlc" BO_ 2633844734 1;
BA_ "TpJ1939VarDlc" BO_ 2560360190 1;
BA_ "SPN" SG_ 2566735614 AT1ThrWyCtlytcCnvrtrDffPrssPrlmn 4294;
BA_ "SPN" SG_ 2566735614 AT1ThrWyCtlystOtltTmpPrlmnaryFMI 4293;
BA_ "SPN" SG_ 2566735614 AT1ThrWyCtlystIntkTmpPrlmnaryFMI 4292;
BA_ "SPN" SG_ 2566735614 AT1ThreeWayCatalystDiffPress 4291;
BA_ "SigType" SG_ 2566735614 AT1ThreeWayCatalystDiffPress 1;
BA_ "SPN" SG_ 2566735614 AT1ThreeWayCatalystOutletTemp 4290;
BA_ "SigType" SG_ 2566735614 AT1ThreeWayCatalystOutletTemp 1;
BA_ "SPN" SG_ 2566735614 AT1ThreeWayCatalystIntakeTemp 4289;
BA_ "SigType" SG_ 2566735614 AT1ThreeWayCatalystIntakeTemp 1;
BA_ "SPN" SG_ 2566805246 AT1DslExhstFldTnk1HtrPrlmnaryFMI 4366;
BA_ "SPN" SG_ 2566805246 AT1DieselExhaustFluidTankHeater 3363;
BA_ "SigType" SG_ 2566805246 AT1DieselExhaustFluidTankHeater 1;
BA_ "SPN" SG_ 2566805246 ATSCROperatorInducementSeverity 5246;
BA_ "SPN" SG_ 2566805246 AT1DslExhstFldTnk1TmpPrlmnaryFMI 4365;
BA_ "SPN" SG_ 2566805246 ATSlctvCtlytcRdctnOprtrIndcmntAc 5245;
BA_ "SPN" SG_ 2566805246 AT1DslExhstFldTnkLvlPrlminaryFMI 3532;
BA_ "SPN" SG_ 2566805246 AT1DieselExhaustFluidTankLevel 3517;
BA_ "SigType" SG_ 2566805246 AT1DieselExhaustFluidTankLevel 1;
BA_ "SPN" SG_ 2566805246 AT1DieselExhaustFluidTankTemp 3031;
BA_ "SigType" SG_ 2566805246 AT1DieselExhaustFluidTankTemp 1;
BA_ "SPN" SG_ 2566805246 AT1DieselExhaustFluidTankVolume 1761;
BA_ "SigType" SG_ 2566805246 AT1DieselExhaustFluidTankVolume 1;
BA_ "SPN" SG_ 2365394686 AT1OutletCorrectedNOx 7351;
BA_ "SigType" SG_ 2365394686 AT1OutletCorrectedNOx 1;
BA_ "SPN" SG_ 2365394686 AT1OtltNOxSnsrSlfdgnssFnalResult 5717;
BA_ "SigType" SG_ 2365394686 AT1OtltNOxSnsrSlfdgnssFnalResult 1;
BA_ "SPN" SG_ 2365394686 AT1OutletNOxSensorNH3Correction 5037;
BA_ "SigType" SG_ 2365394686 AT1OutletNOxSensorNH3Correction 1;
BA_ "SPN" SG_ 2365394686 AT1OutletNOxSensorNO2Correction 5036;
BA_ "SigType" SG_ 2365394686 AT1OutletNOxSensorNO2Correction 1;
BA_ "SPN" SG_ 2365394686 AT1OtltNOxSnsrNOxPressCorrection 5035;
BA_ "SigType" SG_ 2365394686 AT1OtltNOxSnsrNOxPressCorrection 1;
BA_ "SPN" SG_ 2365394686 AT1OtltNOxSnsorO2PressCorrection 5034;
BA_ "SigType" SG_ 2365394686 AT1OtltNOxSnsorO2PressCorrection 1;
BA_ "SPN" SG_ 2365394942 AT1OutletNOxSensorOperationHours 5721;
BA_ "SigType" SG_ 2365394942 AT1OutletNOxSensorOperationHours 1;
BA_ "SPN" SG_ 2365394942 AT1OtltNOxSnsrNwPrtDvtnNOxOffset 5033;
BA_ "SigType" SG_ 2365394942 AT1OtltNOxSnsrNwPrtDvtnNOxOffset 1;
BA_ "SPN" SG_ 2365394942 AT1OtltNOxSnsrNwPrtDvtionNOxGain 5032;
BA_ "SigType" SG_ 2365394942 AT1OtltNOxSnsrNwPrtDvtionNOxGain 1;
BA_ "SPN" SG_ 2365394942 AT1OutletNOxSensorHeaterRatio 5031;
BA_ "SigType" SG_ 2365394942 AT1OutletNOxSensorHeaterRatio 1;
BA_ "SPN" SG_ 2365395198 AT1SCRIntakeCorrectedNOx 7353;
BA_ "SigType" SG_ 2365395198 AT1SCRIntakeCorrectedNOx 1;
BA_ "SPN" SG_ 2365395198 AT1IntkNOxSnsrSlfdgnssFnalResult 5718;
BA_ "SigType" SG_ 2365395198 AT1IntkNOxSnsrSlfdgnssFnalResult 1;
BA_ "SPN" SG_ 2365395198 AT1IntakeNOxSensorNH3Correction 5030;
BA_ "SigType" SG_ 2365395198 AT1IntakeNOxSensorNH3Correction 1;
BA_ "SPN" SG_ 2365395198 AT1IntakeNOxSensorNO2Correction 5029;
BA_ "SigType" SG_ 2365395198 AT1IntakeNOxSensorNO2Correction 1;
BA_ "SPN" SG_ 2365395198 AT1IntkNOxSnsrNOxPressCorrection 5028;
BA_ "SigType" SG_ 2365395198 AT1IntkNOxSnsrNOxPressCorrection 1;
BA_ "SPN" SG_ 2365395198 AT1IntkNOxSnsorO2PressCorrection 5027;
BA_ "SigType" SG_ 2365395198 AT1IntkNOxSnsorO2PressCorrection 1;
BA_ "SPN" SG_ 2365395454 AT1IntakeNOxSensorOperationHours 5722;
BA_ "SigType" SG_ 2365395454 AT1IntakeNOxSensorOperationHours 1;
BA_ "SPN" SG_ 2365395454 AT1IntkNOxSnsrNwPrtDvtnNOxOffset 5026;
BA_ "SigType" SG_ 2365395454 AT1IntkNOxSnsrNwPrtDvtnNOxOffset 1;
BA_ "SPN" SG_ 2365395454 AT1IntkNOxSnsrNwPrtDvtionNOxGain 5025;
BA_ "SigType" SG_ 2365395454 AT1IntkNOxSnsrNwPrtDvtionNOxGain 1;
BA_ "SPN" SG_ 2365395454 AT1IntakeNOxSensorHeaterRatio 5024;
BA_ "SigType" SG_ 2365395454 AT1IntakeNOxSensorHeaterRatio 1;
BA_ "SPN" SG_ 2157248254 AT1DslPrtcltFltrStStndrdDvtnClbO 5496;
BA_ "SigType" SG_ 2157248254 AT1DslPrtcltFltrStStndrdDvtnClbO 1;
BA_ "SPN" SG_ 2157248254 AT1DslPrtcltFltrStManCalibOffset 5495;
BA_ "SigType" SG_ 2157248254 AT1DslPrtcltFltrStManCalibOffset 1;
BA_ "SPN" SG_ 2566711806 Armrest2Switch2 5494;
BA_ "SigType" SG_ 2566711806 Armrest2Switch2 5;
BA_ "SPN" SG_ 2566711806 Armrest2Switch1 5493;
BA_ "SigType" SG_ 2566711806 Armrest2Switch1 5;
BA_ "SPN" SG_ 2566711806 Armrest1Switch2 5492;
BA_ "SigType" SG_ 2566711806 Armrest1Switch2 5;
BA_ "SPN" SG_ 2566711806 Armrest1Switch1 1503;
BA_ "SigType" SG_ 2566711806 Armrest1Switch1 5;
BA_ "SPN" SG_ 2364549886 AngularRateMeasurementLatency 4989;
BA_ "SigType" SG_ 2364549886 AngularRateMeasurementLatency 1;
BA_ "SPN" SG_ 2364549886 YawRateExRangeFigureOfMerit 4988;
BA_ "SigType" SG_ 2364549886 YawRateExRangeFigureOfMerit 5;
BA_ "SPN" SG_ 2364549886 RollRateExRangeFigureOfMerit 4987;
BA_ "SigType" SG_ 2364549886 RollRateExRangeFigureOfMerit 5;
BA_ "SPN" SG_ 2364549886 PitchRateExRangeFigureOfMerit 4986;
BA_ "SigType" SG_ 2364549886 PitchRateExRangeFigureOfMerit 5;
BA_ "SPN" SG_ 2364549886 YawRateExRange 4985;
BA_ "SigType" SG_ 2364549886 YawRateExRange 1;
BA_ "SPN" SG_ 2364549886 RollRateExRange 4984;
BA_ "SigType" SG_ 2364549886 RollRateExRange 1;
BA_ "SPN" SG_ 2364549886 PitchRateExRange 4983;
BA_ "SigType" SG_ 2364549886 PitchRateExRange 1;
BA_ "SPN" SG_ 2566712318 AT2NOxAdsorberDesulfationStatus 5462;
BA_ "SigType" SG_ 2566712318 AT2NOxAdsorberDesulfationStatus 5;
BA_ "SPN" SG_ 2566712318 AT2NOxAdsorberRegenerationStatus 5460;
BA_ "SigType" SG_ 2566712318 AT2NOxAdsorberRegenerationStatus 5;
BA_ "SPN" SG_ 2566712574 AT1NOxAdsorberDesulfationStatus 5461;
BA_ "SigType" SG_ 2566712574 AT1NOxAdsorberDesulfationStatus 5;
BA_ "SPN" SG_ 2566712574 AT1NOxAdsorberRegenerationStatus 5459;
BA_ "SigType" SG_ 2566712574 AT1NOxAdsorberRegenerationStatus 5;
BA_ "SPN" SG_ 2164078590 AT2SCRConversionEfficiency 4419;
BA_ "SigType" SG_ 2164078590 AT2SCRConversionEfficiency 1;
BA_ "SPN" SG_ 2164078590 AT2SCRCmmnddDslExhstFldCnsmption 4418;
BA_ "SigType" SG_ 2164078590 AT2SCRCmmnddDslExhstFldCnsmption 1;
BA_ "SPN" SG_ 2164078590 AT2DslExhstFldAverageConsumption 4417;
BA_ "SigType" SG_ 2164078590 AT2DslExhstFldAverageConsumption 1;
BA_ "SPN" SG_ 2566731006 AT2DslExhstFldQckThwHtrPrlmnryFM 4439;
BA_ "SPN" SG_ 2566731006 AT2DslExhustFluidQuickThawHeater 4438;
BA_ "SPN" SG_ 2566731006 AT2DslExhstFldQckThwTmpPrlmnryFM 4437;
BA_ "SPN" SG_ 2566731006 AT2DslExhstFldQckThwLvlPrlmnryFM 4436;
BA_ "SPN" SG_ 2566731006 AT2DslExhstFldQuickThawTankLevel 4435;
BA_ "SigType" SG_ 2566731006 AT2DslExhstFldQuickThawTankLevel 1;
BA_ "SPN" SG_ 2566731006 AT2DselExhaustFluidQuickThawTemp 4434;
BA_ "SigType" SG_ 2566731006 AT2DselExhaustFluidQuickThawTemp 1;
BA_ "SPN" SG_ 2566731006 AT2DslExhstFldQickThawTankVolume 4433;
BA_ "SigType" SG_ 2566731006 AT2DslExhstFldQickThawTankVolume 1;
BA_ "SPN" SG_ 2566731262 AT2DslExhstFldTnk1HtrPrlmnaryFMI 4432;
BA_ "SPN" SG_ 2566731262 AT2DieselExhaustFluidTankHeater 4431;
BA_ "SigType" SG_ 2566731262 AT2DieselExhaustFluidTankHeater 1;
BA_ "SPN" SG_ 2566731262 AT2DslExhstFldTnk1TmpPrlmnaryFMI 4430;
BA_ "SPN" SG_ 2566731262 AT2DslExhstFldTnkLvlPrlminaryFMI 4429;
BA_ "SPN" SG_ 2566731262 AT2DieselExhaustFluidTankLevel 4428;
BA_ "SigType" SG_ 2566731262 AT2DieselExhaustFluidTankLevel 1;
BA_ "SPN" SG_ 2566731262 AT2DieselExhaustFluidTankTemp 4427;
BA_ "SigType" SG_ 2566731262 AT2DieselExhaustFluidTankTemp 1;
BA_ "SPN" SG_ 2566731262 AT2DieselExhaustFluidTankVolume 4426;
BA_ "SigType" SG_ 2566731262 AT2DieselExhaustFluidTankVolume 1;
BA_ "SPN" SG_ 2566730750 AT2DslExhstFldDsngUnt2RturnValve 7537;
BA_ "SigType" SG_ 2566730750 AT2DslExhstFldDsngUnt2RturnValve 1;
BA_ "SPN" SG_ 2566730750 AT2DslExhstFlidTankDrainValveCmd 5439;
BA_ "SigType" SG_ 2566730750 AT2DslExhstFlidTankDrainValveCmd 1;
BA_ "SPN" SG_ 2566730750 AT2DieselExhaustFluidPumpState 5438;
BA_ "SigType" SG_ 2566730750 AT2DieselExhaustFluidPumpState 5;
BA_ "SPN" SG_ 2566730750 AT2DslExhstFluidTankFillValveCmd 5437;
BA_ "SigType" SG_ 2566730750 AT2DslExhstFluidTankFillValveCmd 1;
BA_ "SPN" SG_ 2566730750 AT2DslExhstFldDsngUnt1RturnValve 4442;
BA_ "SigType" SG_ 2566730750 AT2DslExhstFldDsngUnt1RturnValve 1;
BA_ "SPN" SG_ 2566730750 AT2DslExhstFldPmpDrivePercentage 4441;
BA_ "SigType" SG_ 2566730750 AT2DslExhstFldPmpDrivePercentage 1;
BA_ "SPN" SG_ 2566730750 AT2DslExhustFluidPump1MotorSpeed 4440;
BA_ "SigType" SG_ 2566730750 AT2DslExhustFluidPump1MotorSpeed 1;
BA_ "SPN" SG_ 2566731518 AT2DieselExhaustFluidType 4425;
BA_ "SPN" SG_ 2566731518 AT2DslExhstFldPrprtsPrlminaryFMI 4424;
BA_ "SPN" SG_ 2566731518 AT2DslExhstFldTmp2PreliminaryFMI 4423;
BA_ "SPN" SG_ 2566731518 AT2DeselExhaustFluidConductivity 4422;
BA_ "SigType" SG_ 2566731518 AT2DeselExhaustFluidConductivity 1;
BA_ "SPN" SG_ 2566731518 AT2DselExhaustFluidConcentration 4421;
BA_ "SigType" SG_ 2566731518 AT2DselExhaustFluidConcentration 1;
BA_ "SPN" SG_ 2566731518 AT2DieselExhaustFluidTemp2 4420;
BA_ "SigType" SG_ 2566731518 AT2DieselExhaustFluidTemp2 1;
BA_ "SPN" SG_ 2566732030 AT2SCROutletTempPreliminaryFMI 4416;
BA_ "SPN" SG_ 2566732030 AT2SCROutletTemp 4415;
BA_ "SigType" SG_ 2566732030 AT2SCROutletTemp 1;
BA_ "SPN" SG_ 2566732030 AT2SCRIntakeTempPreliminaryFMI 4414;
BA_ "SPN" SG_ 2566732030 AT2SCRIntakeTemp 4413;
BA_ "SigType" SG_ 2566732030 AT2SCRIntakeTemp 1;
BA_ "SPN" SG_ 2566732286 AT2SCRIntakeAbsPress 6798;
BA_ "SigType" SG_ 2566732286 AT2SCRIntakeAbsPress 1;
BA_ "SPN" SG_ 2566732286 AT2SCRIntakePress 6587;
BA_ "SigType" SG_ 2566732286 AT2SCRIntakePress 1;
BA_ "SPN" SG_ 2566732286 AT2SCRDiffPressPreliminaryFMI 4412;
BA_ "SPN" SG_ 2566732286 AT2SCRDiffPress 4411;
BA_ "SigType" SG_ 2566732286 AT2SCRDiffPress 1;
BA_ "SPN" SG_ 2164079358 AT2DeselExhaustFluidLineHeater10 7571;
BA_ "SigType" SG_ 2164079358 AT2DeselExhaustFluidLineHeater10 5;
BA_ "SPN" SG_ 2164079358 AT2DieselExhaustFluidLineHeater9 7570;
BA_ "SigType" SG_ 2164079358 AT2DieselExhaustFluidLineHeater9 5;
BA_ "SPN" SG_ 2164079358 AT2DieselExhaustFluidLineHeater8 7569;
BA_ "SigType" SG_ 2164079358 AT2DieselExhaustFluidLineHeater8 5;
BA_ "SPN" SG_ 2164079358 AT2DieselExhaustFluidLineHeater7 7568;
BA_ "SigType" SG_ 2164079358 AT2DieselExhaustFluidLineHeater7 5;
BA_ "SPN" SG_ 2164079358 AT2DieselExhaustFluidLineHeater6 7567;
BA_ "SigType" SG_ 2164079358 AT2DieselExhaustFluidLineHeater6 5;
BA_ "SPN" SG_ 2164079358 AT2DieselExhaustFluidLineHeater5 5490;
BA_ "SigType" SG_ 2164079358 AT2DieselExhaustFluidLineHeater5 4;
BA_ "SPN" SG_ 2164079358 AT2DslExhstFluidLineHeaterRelay3 7527;
BA_ "SigType" SG_ 2164079358 AT2DslExhstFluidLineHeaterRelay3 5;
BA_ "SPN" SG_ 2164079358 AT2DslExhstFluidLineHeaterRelay2 7526;
BA_ "SigType" SG_ 2164079358 AT2DslExhstFluidLineHeaterRelay2 5;
BA_ "SPN" SG_ 2164079358 AT2DslExhstFluidLineHeaterRelay1 5973;
BA_ "SigType" SG_ 2164079358 AT2DslExhstFluidLineHeaterRelay1 5;
BA_ "SPN" SG_ 2164079358 AT2DslExhstFldQuickThawHeaterCmd 5415;
BA_ "SigType" SG_ 2164079358 AT2DslExhstFldQuickThawHeaterCmd 1;
BA_ "SPN" SG_ 2164079358 AT2DselExhaustFluidTankHeaterCmd 5138;
BA_ "SigType" SG_ 2164079358 AT2DselExhaustFluidTankHeaterCmd 1;
BA_ "SPN" SG_ 2164079358 AT2DieselExhaustFluidLineHeater4 4410;
BA_ "SigType" SG_ 2164079358 AT2DieselExhaustFluidLineHeater4 5;
BA_ "SPN" SG_ 2164079358 AT2DieselExhaustFluidLineHeater3 4409;
BA_ "SigType" SG_ 2164079358 AT2DieselExhaustFluidLineHeater3 5;
BA_ "SPN" SG_ 2164079358 AT2DieselExhaustFluidLineHeater2 4408;
BA_ "SigType" SG_ 2164079358 AT2DieselExhaustFluidLineHeater2 5;
BA_ "SPN" SG_ 2164079358 AT2DieselExhaustFluidLineHeater1 4407;
BA_ "SigType" SG_ 2164079358 AT2DieselExhaustFluidLineHeater1 5;
BA_ "SPN" SG_ 2164079358 AT2DslExhstFldDoserHeatingModeRq 4406;
BA_ "SPN" SG_ 2164079358 AT2DslExhstFldDsrFltSppressionRq 4405;
BA_ "SigType" SG_ 2164079358 AT2DslExhstFldDsrFltSppressionRq 5;
BA_ "SPN" SG_ 2364549118 AT2DslExhstFldRqstdQnttyOfIntgrt 4403;
BA_ "SigType" SG_ 2364549118 AT2DslExhstFldRqstdQnttyOfIntgrt 1;
BA_ "SPN" SG_ 2364549118 AT2DslExhstFldDsngRqstedQuan6594 6594;
BA_ "SigType" SG_ 2364549118 AT2DslExhstFldDsngRqstedQuan6594 1;
BA_ "SPN" SG_ 2364549118 AT2DselExhaustFluidPumpHeaterCmd 7087;
BA_ "SigType" SG_ 2364549118 AT2DselExhaustFluidPumpHeaterCmd 1;
BA_ "SPN" SG_ 2364549118 AT2DslExhstFldDsngTstInjctnPrmss 7520;
BA_ "SigType" SG_ 2364549118 AT2DslExhstFldDsngTstInjctnPrmss 5;
BA_ "SPN" SG_ 2364549118 AT2DslExhstFldHydStffnssChckPrms 7519;
BA_ "SigType" SG_ 2364549118 AT2DslExhstFldHydStffnssChckPrms 5;
BA_ "SPN" SG_ 2364549118 AT2SCRSystemRequestedState 4402;
BA_ "SPN" SG_ 2364549118 AT2DslExhstFldDsngRqstedQuantity 4401;
BA_ "SigType" SG_ 2364549118 AT2DslExhstFldDsngRqstedQuantity 1;
BA_ "SPN" SG_ 2566732798 AT2DslExhstFldLnHtr4PrlminaryFMI 4400;
BA_ "SPN" SG_ 2566732798 AT2DslExhstFluidLineHeater4State 4399;
BA_ "SigType" SG_ 2566732798 AT2DslExhstFluidLineHeater4State 5;
BA_ "SPN" SG_ 2566732798 AT2DslExhstFldLnHtr3PrlminaryFMI 4398;
BA_ "SPN" SG_ 2566732798 AT2DslExhstFluidLineHeater3State 4397;
BA_ "SigType" SG_ 2566732798 AT2DslExhstFluidLineHeater3State 5;
BA_ "SPN" SG_ 2566732798 AT2DslExhstFldLnHtr2PrlminaryFMI 4396;
BA_ "SPN" SG_ 2566732798 AT2DslExhstFluidLineHeater2State 4395;
BA_ "SigType" SG_ 2566732798 AT2DslExhstFluidLineHeater2State 5;
BA_ "SPN" SG_ 2566732798 AT2DslExhstFldLnHtr1PrlminaryFMI 4394;
BA_ "SPN" SG_ 2566732798 AT2DslExhstFluidLineHeater1State 4393;
BA_ "SigType" SG_ 2566732798 AT2DslExhstFluidLineHeater1State 5;
BA_ "SPN" SG_ 2566732798 AT2SCRFeedbackCtrlStatus 4392;
BA_ "SPN" SG_ 2566732798 AT2SCRDsngVlvExhstTmpReductionRq 4391;
BA_ "SPN" SG_ 2566732798 AT2DieselExhaustFluidDoser1Temp 4390;
BA_ "SigType" SG_ 2566732798 AT2DieselExhaustFluidDoser1Temp 1;
BA_ "SPN" SG_ 2566732798 AT2SCRDosingAirAssistValve 4389;
BA_ "SigType" SG_ 2566732798 AT2SCRDosingAirAssistValve 1;
BA_ "SPN" SG_ 2566732798 AT2SCRDosingAirAssistAbsPress 4388;
BA_ "SigType" SG_ 2566732798 AT2SCRDosingAirAssistAbsPress 1;
BA_ "SPN" SG_ 2364548862 AT2DslExhstFldActlDosingQuan6596 6596;
BA_ "SigType" SG_ 2364548862 AT2DslExhstFldActlDosingQuan6596 1;
BA_ "SPN" SG_ 2364548862 AT2SCRSystem2State 7525;
BA_ "SPN" SG_ 2364548862 AT2DslExhaustFluidDoser1AbsPress 4387;
BA_ "SigType" SG_ 2364548862 AT2DslExhaustFluidDoser1AbsPress 1;
BA_ "SPN" SG_ 2364548862 AT2DslExhstFldActlQnttyOfIntgrtr 4386;
BA_ "SigType" SG_ 2364548862 AT2DslExhstFldActlQnttyOfIntgrtr 1;
BA_ "SPN" SG_ 2364548862 AT2SCRSystem1State 4385;
BA_ "SPN" SG_ 2364548862 AT2DslExhstFldActlDosingQuantity 4384;
BA_ "SigType" SG_ 2364548862 AT2DslExhstFldActlDosingQuantity 1;
BA_ "SPN" SG_ 2364549374 AT2OutletNH3GasSensorHeaterCtrl 4449;
BA_ "SigType" SG_ 2364549374 AT2OutletNH3GasSensorHeaterCtrl 5;
BA_ "SPN" SG_ 2364549374 AT2OtltNH3GsSnsrHtrPrliminaryFMI 4448;
BA_ "SPN" SG_ 2364549374 AT2OutletNH3GasSensorAtTemp 4447;
BA_ "SigType" SG_ 2364549374 AT2OutletNH3GasSensorAtTemp 5;
BA_ "SPN" SG_ 2364549374 AT2OtletNH3GasSensorPowerInRange 4446;
BA_ "SigType" SG_ 2364549374 AT2OtletNH3GasSensorPowerInRange 5;
BA_ "SPN" SG_ 2364549374 AT2OutletNH3ReadingStable 4445;
BA_ "SigType" SG_ 2364549374 AT2OutletNH3ReadingStable 5;
BA_ "SPN" SG_ 2364549374 AT2OutletNH3SensorPreliminaryFMI 4444;
BA_ "SPN" SG_ 2364549374 AT2OutletNH3 4443;
BA_ "SigType" SG_ 2364549374 AT2OutletNH3 1;
BA_ "SPN" SG_ 2566726142 AT2GsOxdtnCtlystDffPrssPrlmnryFM 4764;
BA_ "SPN" SG_ 2566726142 AT2GsOxdtnCtlystOtltTmpPrlmnryFM 4763;
BA_ "SPN" SG_ 2566726142 AT2GsOxdtnCtlystIntkTmpPrlmnryFM 4762;
BA_ "SPN" SG_ 2566726142 AT2GasOxidationCatalystDiffPress 4761;
BA_ "SigType" SG_ 2566726142 AT2GasOxidationCatalystDiffPress 1;
BA_ "SPN" SG_ 2566726142 AT2GsOxidationCatalystOutletTemp 4760;
BA_ "SigType" SG_ 2566726142 AT2GsOxidationCatalystOutletTemp 1;
BA_ "SPN" SG_ 2566726142 AT2GsOxidationCatalystIntakeTemp 4759;
BA_ "SigType" SG_ 2566726142 AT2GsOxidationCatalystIntakeTemp 1;
BA_ "SPN" SG_ 2566725630 AT2DslOxdtnCtlystDffPrssPrlmnryF 4776;
BA_ "SPN" SG_ 2566725630 AT2DslOxdtnCtlystOtltTmpPrlmnryF 4775;
BA_ "SPN" SG_ 2566725630 AT2DslOxdtnCtlystIntkTmpPrlmnryF 4774;
BA_ "SPN" SG_ 2566725630 AT2DslOxidationCatalystDiffPress 4773;
BA_ "SigType" SG_ 2566725630 AT2DslOxidationCatalystDiffPress 1;
BA_ "SPN" SG_ 2566725630 AT2DslOxdationCatalystOutletTemp 4772;
BA_ "SigType" SG_ 2566725630 AT2DslOxdationCatalystOutletTemp 1;
BA_ "SPN" SG_ 2566725630 AT2DslOxdationCatalystIntakeTemp 4771;
BA_ "SigType" SG_ 2566725630 AT2DslOxdationCatalystIntakeTemp 1;
BA_ "SPN" SG_ 2566733310 AT1DslExhstFldQckThwHtrPrlmnryFM 4373;
BA_ "SPN" SG_ 2566733310 AT1DslExhustFluidQuickThawHeater 4372;
BA_ "SigType" SG_ 2566733310 AT1DslExhustFluidQuickThawHeater 1;
BA_ "SPN" SG_ 2566733310 AT1DslExhstFldQckThwTmpPrlmnryFM 4371;
BA_ "SPN" SG_ 2566733310 AT1DslExhstFldQckThwLvlPrlmnryFM 4370;
BA_ "SPN" SG_ 2566733310 AT1DslExhstFldQuickThawTankLevel 4369;
BA_ "SigType" SG_ 2566733310 AT1DslExhstFldQuickThawTankLevel 1;
BA_ "SPN" SG_ 2566733310 AT1DselExhaustFluidQuickThawTemp 4368;
BA_ "SigType" SG_ 2566733310 AT1DselExhaustFluidQuickThawTemp 1;
BA_ "SPN" SG_ 2566733310 AT1DslExhstFldQickThawTankVolume 4367;
BA_ "SigType" SG_ 2566733310 AT1DslExhstFldQickThawTankVolume 1;
BA_ "SPN" SG_ 2566733054 AT1DslExhstFldDsngUnt2RturnValve 7536;
BA_ "SigType" SG_ 2566733054 AT1DslExhstFldDsngUnt2RturnValve 1;
BA_ "SPN" SG_ 2566733054 AT1DieselExhaustFluidPump 7107;
BA_ "SigType" SG_ 2566733054 AT1DieselExhaustFluidPump 4;
BA_ "SPN" SG_ 2566733054 AT1DslExhaustFluidPumpPowerRelay 7416;
BA_ "SigType" SG_ 2566733054 AT1DslExhaustFluidPumpPowerRelay 4;
BA_ "SPN" SG_ 2566733054 AT1DslExhstFlidTankDrainValveCmd 5436;
BA_ "SigType" SG_ 2566733054 AT1DslExhstFlidTankDrainValveCmd 1;
BA_ "SPN" SG_ 2566733054 AT1DieselExhaustFluidPumpState 5435;
BA_ "SigType" SG_ 2566733054 AT1DieselExhaustFluidPumpState 5;
BA_ "SPN" SG_ 2566733054 AT1DslExhstFluidTankFillValveCmd 5434;
BA_ "SigType" SG_ 2566733054 AT1DslExhstFluidTankFillValveCmd 1;
BA_ "SPN" SG_ 2566733054 AT1DslExhstFldDsngUnt1RturnValve 4376;
BA_ "SigType" SG_ 2566733054 AT1DslExhstFldDsngUnt1RturnValve 1;
BA_ "SPN" SG_ 2566733054 AT1DslExhstFldPmpDrivePercentage 4375;
BA_ "SigType" SG_ 2566733054 AT1DslExhstFldPmpDrivePercentage 1;
BA_ "SPN" SG_ 2566733054 AT1DslExhustFluidPump1MotorSpeed 4374;
BA_ "SigType" SG_ 2566733054 AT1DslExhustFluidPump1MotorSpeed 1;
BA_ "SPN" SG_ 2499624702 AT1SCROutletTempPreliminaryFMI 4362;
BA_ "SPN" SG_ 2499624702 AT1SCROutletTemp 4363;
BA_ "SigType" SG_ 2499624702 AT1SCROutletTemp 1;
BA_ "SPN" SG_ 2499624702 AT1SCRIntakeTempPreliminaryFMI 4361;
BA_ "SPN" SG_ 2499624702 AT1SCRIntakeTemp 4360;
BA_ "SigType" SG_ 2499624702 AT1SCRIntakeTemp 1;
BA_ "SPN" SG_ 2566733822 AT1SCRIntakeAbsPress 6797;
BA_ "SigType" SG_ 2566733822 AT1SCRIntakeAbsPress 1;
BA_ "SPN" SG_ 2566733822 AT1SCRIntakePress 6586;
BA_ "SigType" SG_ 2566733822 AT1SCRIntakePress 1;
BA_ "SPN" SG_ 2566733822 AT1SCRDiffPressPreliminaryFMI 4359;
BA_ "SPN" SG_ 2566733822 AT1SCRDiffPress 4358;
BA_ "SigType" SG_ 2566733822 AT1SCRDiffPress 1;
BA_ "SPN" SG_ 2566734078 AT1DeselExhaustFluidLineHeater10 7566;
BA_ "SigType" SG_ 2566734078 AT1DeselExhaustFluidLineHeater10 5;
BA_ "SPN" SG_ 2566734078 AT1DieselExhaustFluidLineHeater9 7565;
BA_ "SigType" SG_ 2566734078 AT1DieselExhaustFluidLineHeater9 5;
BA_ "SPN" SG_ 2566734078 AT1DieselExhaustFluidLineHeater8 7564;
BA_ "SigType" SG_ 2566734078 AT1DieselExhaustFluidLineHeater8 5;
BA_ "SPN" SG_ 2566734078 AT1DieselExhaustFluidLineHeater7 7563;
BA_ "SigType" SG_ 2566734078 AT1DieselExhaustFluidLineHeater7 5;
BA_ "SPN" SG_ 2566734078 AT1DieselExhaustFluidLineHeater6 7562;
BA_ "SigType" SG_ 2566734078 AT1DieselExhaustFluidLineHeater6 5;
BA_ "SPN" SG_ 2566734078 AT1DieselExhaustFluidLineHeater5 7561;
BA_ "SigType" SG_ 2566734078 AT1DieselExhaustFluidLineHeater5 5;
BA_ "SPN" SG_ 2566734078 AT1DslExhstFluidLineHeaterRelay3 7540;
BA_ "SigType" SG_ 2566734078 AT1DslExhstFluidLineHeaterRelay3 5;
BA_ "SPN" SG_ 2566734078 AT1DslExhstFluidLineHeaterRelay2 7069;
BA_ "SigType" SG_ 2566734078 AT1DslExhstFluidLineHeaterRelay2 4;
BA_ "SPN" SG_ 2566734078 AT1DslExhstFluidLineHeaterRelay1 5491;
BA_ "SigType" SG_ 2566734078 AT1DslExhstFluidLineHeaterRelay1 4;
BA_ "SPN" SG_ 2566734078 AT1DselExhaustFluidPumpHeaterCmd 5707;
BA_ "SigType" SG_ 2566734078 AT1DselExhaustFluidPumpHeaterCmd 1;
BA_ "SPN" SG_ 2566734078 AT1DslExhstFldQuickThawHeaterCmd 5414;
BA_ "SigType" SG_ 2566734078 AT1DslExhstFldQuickThawHeaterCmd 1;
BA_ "SPN" SG_ 2566734078 AT1DselExhaustFluidTankHeaterCmd 5137;
BA_ "SigType" SG_ 2566734078 AT1DselExhaustFluidTankHeaterCmd 1;
BA_ "SPN" SG_ 2566734078 AT1DieselExhaustFluidLineHeater4 4357;
BA_ "SigType" SG_ 2566734078 AT1DieselExhaustFluidLineHeater4 5;
BA_ "SPN" SG_ 2566734078 AT1DieselExhaustFluidLineHeater3 4356;
BA_ "SigType" SG_ 2566734078 AT1DieselExhaustFluidLineHeater3 5;
BA_ "SPN" SG_ 2566734078 AT1DieselExhaustFluidLineHeater2 4355;
BA_ "SigType" SG_ 2566734078 AT1DieselExhaustFluidLineHeater2 5;
BA_ "SPN" SG_ 2566734078 AT1DieselExhaustFluidLineHeater1 4354;
BA_ "SigType" SG_ 2566734078 AT1DieselExhaustFluidLineHeater1 5;
BA_ "SPN" SG_ 2566734078 AT1DslExhstFldDoserHeatingModeRq 4353;
BA_ "SPN" SG_ 2566734078 AT1DslExhstFldDsrFltSppressionRq 4352;
BA_ "SigType" SG_ 2566734078 AT1DslExhstFldDsrFltSppressionRq 5;
BA_ "SPN" SG_ 2364548350 AT1DslExhstFldDsngRqstedQuan6593 6593;
BA_ "SigType" SG_ 2364548350 AT1DslExhstFldDsngRqstedQuan6593 1;
BA_ "SPN" SG_ 2364548350 AT1DslExhstFldDsngTstInjctnPrmss 7518;
BA_ "SigType" SG_ 2364548350 AT1DslExhstFldDsngTstInjctnPrmss 5;
BA_ "SPN" SG_ 2364548350 AT1DslExhstFldHydStffnssChckPrms 7517;
BA_ "SigType" SG_ 2364548350 AT1DslExhstFldHydStffnssChckPrms 5;
BA_ "SPN" SG_ 2364548350 AT1DslExhstFldRqstdQnttyOfIntgrt 4350;
BA_ "SigType" SG_ 2364548350 AT1DslExhstFldRqstdQnttyOfIntgrt 1;
BA_ "SPN" SG_ 2364548350 AT1SCRSystemRequestedState 4349;
BA_ "SPN" SG_ 2364548350 AT1DslExhstFldDsngRqstedQuantity 4348;
BA_ "SigType" SG_ 2364548350 AT1DslExhstFldDsngRqstedQuantity 1;
BA_ "SPN" SG_ 2566734334 AT1DslExhstFldLnHtr4PrlminaryFMI 4347;
BA_ "SPN" SG_ 2566734334 AT1DslExhstFluidLineHeater4State 4346;
BA_ "SigType" SG_ 2566734334 AT1DslExhstFluidLineHeater4State 5;
BA_ "SPN" SG_ 2566734334 AT1DslExhstFldLnHtr3PrlminaryFMI 4345;
BA_ "SPN" SG_ 2566734334 AT1DslExhstFluidLineHeater3State 4344;
BA_ "SigType" SG_ 2566734334 AT1DslExhstFluidLineHeater3State 5;
BA_ "SPN" SG_ 2566734334 AT1DslExhstFldLnHtr2PrlminaryFMI 4343;
BA_ "SPN" SG_ 2566734334 AT1DslExhstFluidLineHeater2State 4342;
BA_ "SigType" SG_ 2566734334 AT1DslExhstFluidLineHeater2State 5;
BA_ "SPN" SG_ 2566734334 AT1DslExhstFldLnHtr1PrlminaryFMI 4341;
BA_ "SPN" SG_ 2566734334 AT1DslExhstFluidLineHeater1State 4340;
BA_ "SigType" SG_ 2566734334 AT1DslExhstFluidLineHeater1State 5;
BA_ "SPN" SG_ 2566734334 AT1SCRFeedbackCtrlStatus 4339;
BA_ "SPN" SG_ 2566734334 AT1SCRDsngVlvExhstTmpReductionRq 4338;
BA_ "SPN" SG_ 2566734334 AT1DieselExhaustFluidDoser1Temp 4337;
BA_ "SigType" SG_ 2566734334 AT1DieselExhaustFluidDoser1Temp 1;
BA_ "SPN" SG_ 2566734334 AT1SCRDosingAirAssistValve 4336;
BA_ "SigType" SG_ 2566734334 AT1SCRDosingAirAssistValve 1;
BA_ "SPN" SG_ 2566734334 AT1SCRDosingAirAssistAbsPress 4335;
BA_ "SigType" SG_ 2566734334 AT1SCRDosingAirAssistAbsPress 1;
BA_ "SPN" SG_ 2364548094 AT1DslExhaustFluidDoser1AbsPress 4334;
BA_ "SigType" SG_ 2364548094 AT1DslExhaustFluidDoser1AbsPress 1;
BA_ "SPN" SG_ 2364548094 AT1DslExhstFldActlDosingQuan6595 6595;
BA_ "SigType" SG_ 2364548094 AT1DslExhstFldActlDosingQuan6595 1;
BA_ "SPN" SG_ 2364548094 AT1DslExhstFldActlQnttyOfIntgrtr 4333;
BA_ "SigType" SG_ 2364548094 AT1DslExhstFldActlQnttyOfIntgrtr 1;
BA_ "SPN" SG_ 2364548094 AT1SCRSystem2State 7524;
BA_ "SPN" SG_ 2364548094 AT1SCRSystem1State 4332;
BA_ "SPN" SG_ 2364548094 AT1DslExhstFldActlDosingQuantity 4331;
BA_ "SigType" SG_ 2364548094 AT1DslExhstFldActlDosingQuantity 1;
BA_ "SPN" SG_ 2364548606 AT1OutletNH3GasSensorHeaterCtrl 4383;
BA_ "SigType" SG_ 2364548606 AT1OutletNH3GasSensorHeaterCtrl 5;
BA_ "SPN" SG_ 2364548606 AT1OtltNH3GsSnsrHtrPrliminaryFMI 4382;
BA_ "SPN" SG_ 2364548606 AT1OutletNH3GasSensorAtTemp 4381;
BA_ "SigType" SG_ 2364548606 AT1OutletNH3GasSensorAtTemp 5;
BA_ "SPN" SG_ 2364548606 AT1OtletNH3GasSensorPowerInRange 4380;
BA_ "SigType" SG_ 2364548606 AT1OtletNH3GasSensorPowerInRange 5;
BA_ "SPN" SG_ 2364548606 AT1OutletNH3ReadingStable 4379;
BA_ "SigType" SG_ 2364548606 AT1OutletNH3ReadingStable 5;
BA_ "SPN" SG_ 2364548606 AT1OutletNH3SensorPreliminaryFMI 4378;
BA_ "SPN" SG_ 2364548606 AT1OutletNH3 4377;
BA_ "SigType" SG_ 2364548606 AT1OutletNH3 1;
BA_ "SPN" SG_ 2566726398 AT1GsOxdtnCtlystDffPrssPrlmnryFM 4758;
BA_ "SPN" SG_ 2566726398 AT1GsOxdtnCtlystOtltTmpPrlmnryFM 4757;
BA_ "SPN" SG_ 2566726398 AT1GsOxdtnCtlystIntkTmpPrlmnryFM 4756;
BA_ "SPN" SG_ 2566726398 AT1GasOxidationCatalystDiffPress 4755;
BA_ "SigType" SG_ 2566726398 AT1GasOxidationCatalystDiffPress 1;
BA_ "SPN" SG_ 2566726398 AT1GsOxidationCatalystOutletTemp 4754;
BA_ "SigType" SG_ 2566726398 AT1GsOxidationCatalystOutletTemp 1;
BA_ "SPN" SG_ 2566726398 AT1GsOxidationCatalystIntakeTemp 4753;
BA_ "SigType" SG_ 2566726398 AT1GsOxidationCatalystIntakeTemp 1;
BA_ "SPN" SG_ 2365415678 SPN1 1214;
BA_ "SPN" SG_ 2365415678 FailureModeIdentifier1 1215;
BA_ "SPN" SG_ 2365415678 FailureSpecificB1Counter 4147;
BA_ "SigType" SG_ 2365415678 FailureSpecificB1Counter 1;
BA_ "SPN" SG_ 2365415934 SysGreatestB1Counter 4146;
BA_ "SigType" SG_ 2365415934 SysGreatestB1Counter 1;
BA_ "SPN" SG_ 2365415934 SysCumulativeContinuousMITime 4145;
BA_ "SigType" SG_ 2365415934 SysCumulativeContinuousMITime 1;
BA_ "SPN" SG_ 2365416190 RegulationDescription 4144;
BA_ "SigType" SG_ 2365416190 RegulationDescription 8;
BA_ "SPN" SG_ 2365416446 SysIncompleteMonitorCount 4143;
BA_ "SigType" SG_ 2365416446 SysIncompleteMonitorCount 1;
BA_ "SPN" SG_ 2365416446 SysMalIndActivationMode 4142;
BA_ "SPN" SG_ 2365416446 SysMalIndDisplayStrategy 4141;
BA_ "SigType" SG_ 2365416446 SysMalIndDisplayStrategy 4;
BA_ "SPN" SG_ 2365416446 SysContinuousMalfunctionInd 4140;
BA_ "SigType" SG_ 2365416446 SysContinuousMalfunctionInd 4;
BA_ "SPN" SG_ 2365416446 SysNonRoadworthyCompCount 4139;
BA_ "SigType" SG_ 2365416446 SysNonRoadworthyCompCount 1;
BA_ "SPN" SG_ 2365416702 VehicleCurrentMIAccumTime 4138;
BA_ "SigType" SG_ 2365416702 VehicleCurrentMIAccumTime 1;
BA_ "SPN" SG_ 2365416702 VehicleIncompleteMonitorCount 4137;
BA_ "SigType" SG_ 2365416702 VehicleIncompleteMonitorCount 1;
BA_ "SPN" SG_ 2365416702 VehicleMalfunctionIndActMode 4136;
BA_ "SigType" SG_ 2365416702 VehicleMalfunctionIndActMode 4;
BA_ "SPN" SG_ 2365416702 VehicleMalfunctionIndStrategy 4135;
BA_ "SigType" SG_ 2365416702 VehicleMalfunctionIndStrategy 4;
BA_ "SPN" SG_ 2365416702 VehicleContinuousMalfunctionInd 4134;
BA_ "SigType" SG_ 2365416702 VehicleContinuousMalfunctionInd 4;
BA_ "SPN" SG_ 2365416702 VehicleNonRoadworthyCompCount 4133;
BA_ "SigType" SG_ 2365416702 VehicleNonRoadworthyCompCount 1;
BA_ "SPN" SG_ 2359361278 PMNTEDeficiencyAreaStatus 4132;
BA_ "SigType" SG_ 2359361278 PMNTEDeficiencyAreaStatus 4;
BA_ "SPN" SG_ 2359361278 MnfcPMNTECarveOutAreaStatus 4131;
BA_ "SigType" SG_ 2359361278 MnfcPMNTECarveOutAreaStatus 4;
BA_ "SPN" SG_ 2359361278 PMNTEControlAreaStatus 4130;
BA_ "SPN" SG_ 2359361278 NOxNTEDeficiencyAreaStatus 4129;
BA_ "SigType" SG_ 2359361278 NOxNTEDeficiencyAreaStatus 4;
BA_ "SPN" SG_ 2359361278 MnfcNOxNTECarveOutAreaStatus 4128;
BA_ "SigType" SG_ 2359361278 MnfcNOxNTECarveOutAreaStatus 4;
BA_ "SPN" SG_ 2359361278 NOxNTEControlAreaStatus 4127;
BA_ "SPN" SG_ 2292317950 AECDEngineHours1Timer2 4126;
BA_ "SigType" SG_ 2292317950 AECDEngineHours1Timer2 1;
BA_ "SPN" SG_ 2292317950 AECDEngineHours1Timer1 4125;
BA_ "SigType" SG_ 2292317950 AECDEngineHours1Timer1 1;
BA_ "SPN" SG_ 2292317950 AECDNumber1 4124;
BA_ "SigType" SG_ 2292317950 AECDNumber1 1;
BA_ "SPN" SG_ 2566809342 BatteryMainSwitchHoldState 1681;
BA_ "SigType" SG_ 2566809342 BatteryMainSwitchHoldState 4;
BA_ "SPN" SG_ 2365446910 Joystick3XAxisDetentPosStatus 2754;
BA_ "SigType" SG_ 2365446910 Joystick3XAxisDetentPosStatus 4;
BA_ "SPN" SG_ 2365446910 Joystick3Button9PressedStatus 2767;
BA_ "SigType" SG_ 2365446910 Joystick3Button9PressedStatus 4;
BA_ "SPN" SG_ 2365446910 Joystick3Button10PressedStatus 2768;
BA_ "SigType" SG_ 2365446910 Joystick3Button10PressedStatus 4;
BA_ "SPN" SG_ 2365446910 Joystick3Button11PressedStatus 2769;
BA_ "SigType" SG_ 2365446910 Joystick3Button11PressedStatus 4;
BA_ "SPN" SG_ 2365446910 Joystick3Button12PressedStatus 2770;
BA_ "SigType" SG_ 2365446910 Joystick3Button12PressedStatus 4;
BA_ "SPN" SG_ 2365446910 Joystick3YAxisDetentPosStatus 2755;
BA_ "SigType" SG_ 2365446910 Joystick3YAxisDetentPosStatus 4;
BA_ "SPN" SG_ 2365446910 Joystick3YAxisPos 2735;
BA_ "SPN" SG_ 2365446910 Jystck3YAxsLvrFrwrdPstvPosStatus 2740;
BA_ "SigType" SG_ 2365446910 Jystck3YAxsLvrFrwrdPstvPosStatus 4;
BA_ "SPN" SG_ 2365446910 Jystck3YAxsLvrBckNgtivePosStatus 2745;
BA_ "SigType" SG_ 2365446910 Jystck3YAxsLvrBckNgtivePosStatus 4;
BA_ "SPN" SG_ 2365446910 Joystick3YAxisNeutralPosStatus 2750;
BA_ "SigType" SG_ 2365446910 Joystick3YAxisNeutralPosStatus 4;
BA_ "SPN" SG_ 2365446910 Joystick3XAxisPos 2734;
BA_ "SPN" SG_ 2365446910 Jystck3XAxsLvrRghtPstvePosStatus 2739;
BA_ "SigType" SG_ 2365446910 Jystck3XAxsLvrRghtPstvePosStatus 4;
BA_ "SPN" SG_ 2365446910 Jystck3XAxsLvrLftNgtivePosStatus 2744;
BA_ "SigType" SG_ 2365446910 Jystck3XAxsLvrLftNgtivePosStatus 4;
BA_ "SPN" SG_ 2365446910 Joystick3XAxisNeutralPosStatus 2749;
BA_ "SigType" SG_ 2365446910 Joystick3XAxisNeutralPosStatus 4;
BA_ "SPN" SG_ 2365446910 Joystick3Button5PressedStatus 2763;
BA_ "SigType" SG_ 2365446910 Joystick3Button5PressedStatus 4;
BA_ "SPN" SG_ 2365446910 Joystick3Button6PressedStatus 2764;
BA_ "SigType" SG_ 2365446910 Joystick3Button6PressedStatus 4;
BA_ "SPN" SG_ 2365446910 Joystick3Button7PressedStatus 2765;
BA_ "SigType" SG_ 2365446910 Joystick3Button7PressedStatus 4;
BA_ "SPN" SG_ 2365446910 Joystick3Button8PressedStatus 2766;
BA_ "SigType" SG_ 2365446910 Joystick3Button8PressedStatus 4;
BA_ "SPN" SG_ 2365446910 Joystick3Button1PressedStatus 2759;
BA_ "SigType" SG_ 2365446910 Joystick3Button1PressedStatus 4;
BA_ "SPN" SG_ 2365446910 Joystick3Button2PressedStatus 2760;
BA_ "SigType" SG_ 2365446910 Joystick3Button2PressedStatus 4;
BA_ "SPN" SG_ 2365446910 Joystick3Button3PressedStatus 2761;
BA_ "SigType" SG_ 2365446910 Joystick3Button3PressedStatus 4;
BA_ "SPN" SG_ 2365446910 Joystick3Button4PressedStatus 2762;
BA_ "SigType" SG_ 2365446910 Joystick3Button4PressedStatus 4;
BA_ "SPN" SG_ 2365446398 Joystick2XAxisDetentPosStatus 2717;
BA_ "SigType" SG_ 2365446398 Joystick2XAxisDetentPosStatus 4;
BA_ "SPN" SG_ 2365446398 Joystick2YAxisDetentPosStatus 2718;
BA_ "SigType" SG_ 2365446398 Joystick2YAxisDetentPosStatus 4;
BA_ "SPN" SG_ 2365446398 Joystick2YAxisPos 2698;
BA_ "SPN" SG_ 2365446398 Jystck2YAxsLvrFrwrdPstvPosStatus 2703;
BA_ "SigType" SG_ 2365446398 Jystck2YAxsLvrFrwrdPstvPosStatus 4;
BA_ "SPN" SG_ 2365446398 Jystck2YAxsLvrBckNgtivePosStatus 2708;
BA_ "SigType" SG_ 2365446398 Jystck2YAxsLvrBckNgtivePosStatus 4;
BA_ "SPN" SG_ 2365446398 Joystick2YAxisNeutralPosStatus 2713;
BA_ "SigType" SG_ 2365446398 Joystick2YAxisNeutralPosStatus 4;
BA_ "SPN" SG_ 2365446398 Joystick2XAxisPos 2697;
BA_ "SPN" SG_ 2365446398 Jystck2XAxsLvrRghtPstvePosStatus 2702;
BA_ "SigType" SG_ 2365446398 Jystck2XAxsLvrRghtPstvePosStatus 4;
BA_ "SPN" SG_ 2365446398 Jystck2XAxsLvrLftNgtivePosStatus 2707;
BA_ "SigType" SG_ 2365446398 Jystck2XAxsLvrLftNgtivePosStatus 4;
BA_ "SPN" SG_ 2365446398 Joystick2XAxisNeutralPosStatus 2712;
BA_ "SigType" SG_ 2365446398 Joystick2XAxisNeutralPosStatus 4;
BA_ "SPN" SG_ 2365446398 Joystick2Button9PressedStatus 2730;
BA_ "SigType" SG_ 2365446398 Joystick2Button9PressedStatus 4;
BA_ "SPN" SG_ 2365446398 Joystick2Button10PressedStatus 2731;
BA_ "SigType" SG_ 2365446398 Joystick2Button10PressedStatus 4;
BA_ "SPN" SG_ 2365446398 Joystick2Button11PressedStatus 2732;
BA_ "SigType" SG_ 2365446398 Joystick2Button11PressedStatus 4;
BA_ "SPN" SG_ 2365446398 Joystick2Button12PressedStatus 2733;
BA_ "SigType" SG_ 2365446398 Joystick2Button12PressedStatus 4;
BA_ "SPN" SG_ 2365446398 Joystick2Button5PressedStatus 2726;
BA_ "SigType" SG_ 2365446398 Joystick2Button5PressedStatus 4;
BA_ "SPN" SG_ 2365446398 Joystick2Button6PressedStatus 2727;
BA_ "SigType" SG_ 2365446398 Joystick2Button6PressedStatus 4;
BA_ "SPN" SG_ 2365446398 Joystick2Button7PressedStatus 2728;
BA_ "SigType" SG_ 2365446398 Joystick2Button7PressedStatus 4;
BA_ "SPN" SG_ 2365446398 Joystick2Button8PressedStatus 2729;
BA_ "SigType" SG_ 2365446398 Joystick2Button8PressedStatus 4;
BA_ "SPN" SG_ 2365446398 Joystick2Button1PressedStatus 2722;
BA_ "SigType" SG_ 2365446398 Joystick2Button1PressedStatus 4;
BA_ "SPN" SG_ 2365446398 Joystick2Button2PressedStatus 2723;
BA_ "SigType" SG_ 2365446398 Joystick2Button2PressedStatus 4;
BA_ "SPN" SG_ 2365446398 Joystick2Button3PressedStatus 2724;
BA_ "SigType" SG_ 2365446398 Joystick2Button3PressedStatus 4;
BA_ "SPN" SG_ 2365446398 Joystick2Button4PressedStatus 2725;
BA_ "SigType" SG_ 2365446398 Joystick2Button4PressedStatus 4;
BA_ "SPN" SG_ 2365445886 Joystick1XAxisDetentPosStatus 2680;
BA_ "SigType" SG_ 2365445886 Joystick1XAxisDetentPosStatus 4;
BA_ "SPN" SG_ 2365445886 Joystick1YAxisDetentPosStatus 2681;
BA_ "SigType" SG_ 2365445886 Joystick1YAxisDetentPosStatus 4;
BA_ "SPN" SG_ 2365445886 Joystick1YAxisPos 2661;
BA_ "SPN" SG_ 2365445886 Jystck1YAxsLvrFrwrdPstvPosStatus 2666;
BA_ "SigType" SG_ 2365445886 Jystck1YAxsLvrFrwrdPstvPosStatus 4;
BA_ "SPN" SG_ 2365445886 Jystck1YAxsLvrBckNgtivePosStatus 2671;
BA_ "SigType" SG_ 2365445886 Jystck1YAxsLvrBckNgtivePosStatus 4;
BA_ "SPN" SG_ 2365445886 Joystick1YAxisNeutralPosStatus 2676;
BA_ "SigType" SG_ 2365445886 Joystick1YAxisNeutralPosStatus 4;
BA_ "SPN" SG_ 2365445886 Joystick1XAxisPos 2660;
BA_ "SPN" SG_ 2365445886 Joystick1Button9PressedStatus 2693;
BA_ "SigType" SG_ 2365445886 Joystick1Button9PressedStatus 4;
BA_ "SPN" SG_ 2365445886 Joystick1Button10PressedStatus 2694;
BA_ "SigType" SG_ 2365445886 Joystick1Button10PressedStatus 4;
BA_ "SPN" SG_ 2365445886 Joystick1Button11PressedStatus 2695;
BA_ "SigType" SG_ 2365445886 Joystick1Button11PressedStatus 4;
BA_ "SPN" SG_ 2365445886 Joystick1Button12PressedStatus 2696;
BA_ "SigType" SG_ 2365445886 Joystick1Button12PressedStatus 4;
BA_ "SPN" SG_ 2365445886 Joystick1Button5PressedStatus 2689;
BA_ "SigType" SG_ 2365445886 Joystick1Button5PressedStatus 4;
BA_ "SPN" SG_ 2365445886 Joystick1Button6PressedStatus 2690;
BA_ "SigType" SG_ 2365445886 Joystick1Button6PressedStatus 4;
BA_ "SPN" SG_ 2365445886 Joystick1Button7PressedStatus 2691;
BA_ "SigType" SG_ 2365445886 Joystick1Button7PressedStatus 4;
BA_ "SPN" SG_ 2365445886 Joystick1Button8PressedStatus 2692;
BA_ "SigType" SG_ 2365445886 Joystick1Button8PressedStatus 4;
BA_ "SPN" SG_ 2365445886 Joystick1Button1PressedStatus 2685;
BA_ "SigType" SG_ 2365445886 Joystick1Button1PressedStatus 4;
BA_ "SPN" SG_ 2365445886 Joystick1Button2PressedStatus 2686;
BA_ "SigType" SG_ 2365445886 Joystick1Button2PressedStatus 4;
BA_ "SPN" SG_ 2365445886 Joystick1Button3PressedStatus 2687;
BA_ "SigType" SG_ 2365445886 Joystick1Button3PressedStatus 4;
BA_ "SPN" SG_ 2365445886 Joystick1Button4PressedStatus 2688;
BA_ "SigType" SG_ 2365445886 Joystick1Button4PressedStatus 4;
BA_ "SPN" SG_ 2365445886 Jystck1XAxsLvrRghtPstvePosStatus 2665;
BA_ "SigType" SG_ 2365445886 Jystck1XAxsLvrRghtPstvePosStatus 4;
BA_ "SPN" SG_ 2365445886 Jystck1XAxsLvrLftNgtivePosStatus 2670;
BA_ "SigType" SG_ 2365445886 Jystck1XAxsLvrLftNgtivePosStatus 4;
BA_ "SPN" SG_ 2365445886 Joystick1XAxisNeutralPosStatus 2675;
BA_ "SigType" SG_ 2365445886 Joystick1XAxisNeutralPosStatus 4;
BA_ "SPN" SG_ 2566847230 ParkingBrakeRedWarningSignal 3557;
BA_ "SigType" SG_ 2566847230 ParkingBrakeRedWarningSignal 5;
BA_ "SPN" SG_ 2566847230 ParkBrakeReleaseInhibitStatus 3808;
BA_ "SigType" SG_ 2566847230 ParkBrakeReleaseInhibitStatus 4;
BA_ "SPN" SG_ 2566847230 ParkingBrakeActuator 619;
BA_ "SigType" SG_ 2566847230 ParkingBrakeActuator 4;
BA_ "SPN" SG_ 2566847230 BrakeSecondPress 118;
BA_ "SigType" SG_ 2566847230 BrakeSecondPress 1;
BA_ "SPN" SG_ 2566847230 BrakePrimaryPress 117;
BA_ "SigType" SG_ 2566847230 BrakePrimaryPress 1;
BA_ "SPN" SG_ 2566847230 BrakeAppPress 116;
BA_ "SigType" SG_ 2566847230 BrakeAppPress 1;
BA_ "SPN" SG_ 2566848254 AuxPumpPress 73;
BA_ "SigType" SG_ 2566848254 AuxPumpPress 1;
BA_ "SPN" SG_ 2566725886 AT1DslOxdtnCtlystDffPrssPrlmnryF 4770;
BA_ "SPN" SG_ 2566725886 AT1DslOxdtnCtlystOtltTmpPrlmnryF 4769;
BA_ "SPN" SG_ 2566725886 AT1DslOxdtnCtlystIntkTmpPrlmnryF 4768;
BA_ "SPN" SG_ 2566725886 AT1DslOxidationCatalystDiffPress 4767;
BA_ "SigType" SG_ 2566725886 AT1DslOxidationCatalystDiffPress 1;
BA_ "SPN" SG_ 2566725886 AT1DslOxdationCatalystOutletTemp 4766;
BA_ "SigType" SG_ 2566725886 AT1DslOxdationCatalystOutletTemp 1;
BA_ "SPN" SG_ 2566725886 AT1DslOxdationCatalystIntakeTemp 4765;
BA_ "SigType" SG_ 2566725886 AT1DslOxdationCatalystIntakeTemp 1;
BA_ "SPN" SG_ 2359557886 DTCWarnLampSupportStatus 4115;
BA_ "SigType" SG_ 2359557886 DTCWarnLampSupportStatus 4;
BA_ "SPN" SG_ 2359557886 DTCWarnLampSupportFlash 4119;
BA_ "SigType" SG_ 2359557886 DTCWarnLampSupportFlash 4;
BA_ "SPN" SG_ 2359557886 DTCStopLampSupportStatus 4114;
BA_ "SigType" SG_ 2359557886 DTCStopLampSupportStatus 4;
BA_ "SPN" SG_ 2359557886 DTCStopLampSupportFlash 4118;
BA_ "SigType" SG_ 2359557886 DTCStopLampSupportFlash 4;
BA_ "SPN" SG_ 2359557886 DTCProtectLampSupportStatus 4116;
BA_ "SigType" SG_ 2359557886 DTCProtectLampSupportStatus 4;
BA_ "SPN" SG_ 2359557886 DTCProtectLampSupportFlash 4120;
BA_ "SigType" SG_ 2359557886 DTCProtectLampSupportFlash 4;
BA_ "SPN" SG_ 2359557886 DTCMilSupportStatus 4113;
BA_ "SPN" SG_ 2359557886 DTCMilSupportFlash 4117;
BA_ "SigType" SG_ 2359557886 DTC1 7;
BA_ "SigType" SG_ 2633844734 TransModeLabel8 8;
BA_ "SigType" SG_ 2633844734 TransModeLabel7 8;
BA_ "SigType" SG_ 2633844734 TransModeLabel6 8;
BA_ "SigType" SG_ 2633844734 TransModeLabel5 8;
BA_ "SigType" SG_ 2633844734 TransModeLabel4 8;
BA_ "SigType" SG_ 2633844734 TransModeLabel3 8;
BA_ "SigType" SG_ 2633844734 TransModeLabel2 8;
BA_ "SPN" SG_ 2633844734 TransModeLabel 4254;
BA_ "SigType" SG_ 2633844734 TransModeLabel 8;
BA_ "SPN" SG_ 2560360190 DataDictionaryMethod 4181;
BA_ "SPN" SG_ 2560360190 DataDictionaryManufacturerCode 4180;
BA_ "SPN" SG_ 2566736126 EngExhstGsOxygnSnsrClsdLpOprtnBn 4241;
BA_ "SPN" SG_ 2566736126 ShorttermFuelTrimBank2 4238;
BA_ "SigType" SG_ 2566736126 ShorttermFuelTrimBank2 1;
BA_ "SPN" SG_ 2566736126 LongtermFuelTrimBank2 4239;
BA_ "SigType" SG_ 2566736126 LongtermFuelTrimBank2 1;
BA_ "SPN" SG_ 2566736382 EngExhstGsOxygnSnsrClsdLpOprtnBn 4240;
BA_ "SPN" SG_ 2566736382 ShorttermFuelTrimBank1 4236;
BA_ "SigType" SG_ 2566736382 ShorttermFuelTrimBank1 1;
BA_ "SPN" SG_ 2566736382 LongtermFuelTrimBank1 4237;
BA_ "SigType" SG_ 2566736382 LongtermFuelTrimBank1 1;
VAL_ 2566805246 ATSCROperatorInducementSeverity 7 "Not Available / Not Supported" 6 "Reserved" 5 "Inducement Level 5" 4 "Inducement Level 4" 3 "Inducement Level 3" 2 "Inducement Level 2" 1 "Inducement Level 1" 0 "No Inducement Active" ;
VAL_ 2566805246 ATSlctvCtlytcRdctnOprtrIndcmntAc 5 "reserved for SAE assignment" 3 "reserved for SAE assignment" 2 "reserved for SAE assignment" 7 "not available" 4 "On  fast blink 1 HZ" 6 "reserved for SAE assignment" 1 "On  solid" 0 "Off" ;
VAL_ 2566711806 Armrest2Switch2 3 "Dont care/take no action" 2 "Reserved" 1 "On" 0 "Off" ;
VAL_ 2566711806 Armrest2Switch1 3 "Dont care/take no action" 2 "Reserved" 1 "On" 0 "Off" ;
VAL_ 2566711806 Armrest1Switch2 3 "Dont care/take no action" 2 "Reserved" 1 "On" 0 "Off" ;
VAL_ 2566711806 Armrest1Switch1 3 "Dont care/take no action" 2 "Reserved" 1 "On" 0 "Off" ;
VAL_ 2364549886 YawRateExRangeFigureOfMerit 3 "Not available" 2 "Error" 1 "Yaw rate degraded Data is suspect due to environmental conditions" 0 "Yaw rate fully functional Data is within sensor specification" ;
VAL_ 2364549886 RollRateExRangeFigureOfMerit 3 "Not available" 2 "Error" 1 "Roll rate degraded Data is suspect due to environmental conditions" 0 "Roll rate fully functional Data is within sensor specification" ;
VAL_ 2364549886 PitchRateExRangeFigureOfMerit 3 "Not available" 2 "Error" 1 "Pitch rate degraded Data is suspect due to environmental conditions" 0 "Pitch rate fully functional Data is within sensor specification" ;
VAL_ 2566712318 AT2NOxAdsorberDesulfationStatus 3 "Not available" 2 "Error indicator" 1 "Active" 0 "Inactive" ;
VAL_ 2566712318 AT2NOxAdsorberRegenerationStatus 3 "Not available" 2 "Error indicator" 1 "Active" 0 "Inactive" ;
VAL_ 2566712574 AT1NOxAdsorberDesulfationStatus 3 "Not available" 2 "Error indicator" 1 "Active" 0 "Inactive" ;
VAL_ 2566712574 AT1NOxAdsorberRegenerationStatus 3 "Not available" 2 "Error indicator" 1 "Active" 0 "Inactive" ;
VAL_ 2566730750 AT2DieselExhaustFluidPumpState 3 "not available" 2 "reserved for SAE assignment" 1 "pump error" 0 "pump operational" ;
VAL_ 2566731518 AT2DieselExhaustFluidType 15 "Not available" 14 "Error detected with urea reagent type detection" 13 "Not able to determine catalyst reagent type type unknown" 3 "Catalyst reagent is proper mixture" 2 "Catalyst reagent is diesel" 1 "Catalyst reagent is urea concentration too low" 0 "Catalyst reagent is urea concentration too high" ;
VAL_ 2164079358 AT2DeselExhaustFluidLineHeater10 3 "not available" 2 "reserved for future assignment by SAE" 1 "request for heater to be active" 0 "request for heater to be inactive" ;
VAL_ 2164079358 AT2DieselExhaustFluidLineHeater9 3 "not available" 2 "reserved for future assignment by SAE" 1 "request for heater to be active" 0 "request for heater to be inactive" ;
VAL_ 2164079358 AT2DieselExhaustFluidLineHeater8 3 "not available" 2 "reserved for future assignment by SAE" 1 "request for heater to be active" 0 "request for heater to be inactive" ;
VAL_ 2164079358 AT2DieselExhaustFluidLineHeater7 3 "not available" 2 "reserved for future assignment by SAE" 1 "request for heater to be active" 0 "request for heater to be inactive" ;
VAL_ 2164079358 AT2DieselExhaustFluidLineHeater6 3 "not available" 2 "reserved for future assignment by SAE" 1 "request for heater to be active" 0 "request for heater to be inactive" ;
VAL_ 2164079358 AT2DieselExhaustFluidLineHeater5 3 "not available" 2 "reserved for future assignment by SAE " 1 "request for heater to be active " 0 "request for heater to be inactive " ;
VAL_ 2164079358 AT2DslExhstFluidLineHeaterRelay3 3 "Not available" 2 "Error" 1 "On" 0 "Off" ;
VAL_ 2164079358 AT2DslExhstFluidLineHeaterRelay2 3 "Not available" 2 "Error" 1 "On" 0 "Off" ;
VAL_ 2164079358 AT2DslExhstFluidLineHeaterRelay1 3 "Not available" 2 "Error" 1 "On" 0 "Off" ;
VAL_ 2164079358 AT2DieselExhaustFluidLineHeater4 3 "not available" 2 "reserved for future assignment by SAE" 1 "request for heater to be active" 0 "request for heater to be inactive" ;
VAL_ 2164079358 AT2DieselExhaustFluidLineHeater3 3 "not available" 2 "reserved for future assignment by SAE" 1 "request for heater to be active" 0 "request for heater to be inactive" ;
VAL_ 2164079358 AT2DieselExhaustFluidLineHeater2 3 "not available" 2 "reserved for future assignment by SAE" 1 "request for heater to be active" 0 "request for heater to be inactive" ;
VAL_ 2164079358 AT2DieselExhaustFluidLineHeater1 3 "not available" 2 "reserved for future assignment by SAE" 1 "request for heater to be active" 0 "request for heater to be inactive" ;
VAL_ 2164079358 AT2DslExhstFldDoserHeatingModeRq 7 "Not available" 3 "Heater on" 2 "Heater automatic mode" 1 "Heater economy mode" 0 "Heater off" ;
VAL_ 2164079358 AT2DslExhstFldDsrFltSppressionRq 3 "Not available" 2 "Reserved" 1 "Error suppression on" 0 "Error suppression off" ;
VAL_ 2364549118 AT2DslExhstFldDsngTstInjctnPrmss 3 "not available" 2 "error" 1 "DEF dosing test injection allowed" 0 "not allowed" ;
VAL_ 2364549118 AT2DslExhstFldHydStffnssChckPrms 3 "not available" 2 "error" 1 "DEF hydraulic stiffness check allowed" 0 "not allowed" ;
VAL_ 2364549118 AT2SCRSystemRequestedState 15 "Not available" 14 "Error" 10 "Service test mode dosing not allowed" 9 "Service test mode dosing allowed" 8 "Diagnosis afterrun" 7 "Shutoff wait for afterrun" 6 "Protect mode against cold defreeze" 5 "Protect mode against heat pressure buildup" 4 "Reserved for future assignment by SAE" 3 "System error pending" 2 "Normal dosing operation" 1 "Preparing dosing readiness wake up prepare to operate wait for start" 0 "Dormant sleep mode" ;
VAL_ 2566732798 AT2DslExhstFluidLineHeater4State 3 "not available" 2 "error" 1 "heater active" 0 "heater inactive" ;
VAL_ 2566732798 AT2DslExhstFluidLineHeater3State 3 "not available" 2 "error" 1 "heater active" 0 "heater inactive" ;
VAL_ 2566732798 AT2DslExhstFluidLineHeater2State 3 "not available" 2 "error" 1 "heater active" 0 "heater inactive" ;
VAL_ 2566732798 AT2DslExhstFluidLineHeater1State 3 "not available" 2 "error" 1 "heater active" 0 "heater inactive" ;
VAL_ 2566732798 AT2SCRFeedbackCtrlStatus 4 "reserved for future assignment by SAE" 3 "reserved for future assignment by SAE" 2 "reserved for future assignment by SAE" 7 "not available" 6 "error" 5 "reserved for future assignment by SAE" 1 "closed loop control active" 0 "open loop control active" ;
VAL_ 2566732798 AT2SCRDsngVlvExhstTmpReductionRq 7 "not available" 6 "error" 5 "reserved for future assignment by SAE" 4 "reserved for future assignment by SAE" 3 "reserved for future assignment by SAE" 2 "reduction request stage 2" 1 "reduction request stage 1" 0 "no request" ;
VAL_ 2364548862 AT2SCRSystem2State 15 "Not available" 14 "Error" 11 "Ok to Power Down (SCR dosing system has complete housekeeping and power may safely be removed.)" 10 "Service test mode, dosing not allowed" 9 "Service test mode, dosing allowed" 8 "Diagnosis (after-run)" 7 "Shutoff (wait for after-run)" 6 "Protect mode against cold (defreeze)" 5 "Protect mode against heat (pressure buildup)" 4 "Purging (SCR dosing system is removing residual DEF from system prior to shutdown)" 3 "System error pending" 2 "Normal dosing operation" 1 "Preparing dosing readiness (wake up; prepare to operate; wait for start)" 0 "Dormant (sleep mode)" ;
VAL_ 2364548862 AT2SCRSystem1State 15 "Not available" 14 "Error" 11 "Ok to Power Down (SCR dosing system has complete housekeeping and power may safely be removed)" 10 "Service test mode, dosing not allowed" 9 "Service test mode, dosing allowed " 8 "Diagnosis (after-run)" 7 "Shutoff (wait for after-run) " 6 "Protect mode against cold (defreeze) " 5 "Protect mode against heat (pressure buildup) " 4 "Reserved for future assignment by SAE" 3 "System error pending" 2 "Normal dosing operation" 1 "Preparing dosing readiness (wake up; prepare to operate; wait for start)" 0 "Dormant (sleep mode)" ;
VAL_ 2364549374 AT2OutletNH3GasSensorHeaterCtrl 3 "Heater off or Not available" 2 "Preheat 1" 1 "Preheat 2" 0 "Automatic" ;
VAL_ 2364549374 AT2OutletNH3GasSensorAtTemp 3 "Not available" 2 "Error" 1 "Heater element is in range" 0 "Heater element is not in range" ;
VAL_ 2364549374 AT2OtletNH3GasSensorPowerInRange 3 "Not available" 2 "Error" 1 "Heater element is in range" 0 "Heater element is not in range" ;
VAL_ 2364549374 AT2OutletNH3ReadingStable 3 "Not available" 2 "Error" 1 "Reading is stable" 0 "Reading is not stable" ;
VAL_ 2566733054 AT1DieselExhaustFluidPump 3 "not available" 2 "error" 1 "on" 0 "off" ;
VAL_ 2566733054 AT1DslExhaustFluidPumpPowerRelay 3 "not available" 2 "error" 1 "active - power is being applied to the relay" 0 "not active - no power is being applied to the relay" ;
VAL_ 2566733054 AT1DieselExhaustFluidPumpState 3 "not available" 2 "reserved for SAE assignment" 1 "pump error" 0 "pump operational" ;
VAL_ 2566734078 AT1DeselExhaustFluidLineHeater10 3 "not available" 2 "reserved for future assignment by SAE" 1 "request for heater to be active" 0 "request for heater to be inactive" ;
VAL_ 2566734078 AT1DieselExhaustFluidLineHeater9 3 "not available" 2 "reserved for future assignment by SAE" 1 "request for heater to be active" 0 "request for heater to be inactive" ;
VAL_ 2566734078 AT1DieselExhaustFluidLineHeater8 3 "not available" 2 "reserved for future assignment by SAE" 1 "request for heater to be active" 0 "request for heater to be inactive" ;
VAL_ 2566734078 AT1DieselExhaustFluidLineHeater7 3 "not available" 2 "reserved for future assignment by SAE" 1 "request for heater to be active" 0 "request for heater to be inactive" ;
VAL_ 2566734078 AT1DieselExhaustFluidLineHeater6 3 "not available" 2 "reserved for future assignment by SAE" 1 "request for heater to be active" 0 "request for heater to be inactive" ;
VAL_ 2566734078 AT1DieselExhaustFluidLineHeater5 3 "not available" 2 "reserved for future assignment by SAE" 1 "request for heater to be active" 0 "request for heater to be inactive" ;
VAL_ 2566734078 AT1DslExhstFluidLineHeaterRelay3 3 "Not available" 2 "Error" 1 "On" 0 "Off" ;
VAL_ 2566734078 AT1DslExhstFluidLineHeaterRelay2 3 "Not available" 2 "Error" 1 "On" 0 "Off" ;
VAL_ 2566734078 AT1DslExhstFluidLineHeaterRelay1 3 "Not available" 2 "Error" 1 "On" 0 "Off" ;
VAL_ 2566734078 AT1DieselExhaustFluidLineHeater4 3 "not available" 2 "reserved for future assignment by SAE" 1 "request for heater to be active" 0 "request for heater to be inactive" ;
VAL_ 2566734078 AT1DieselExhaustFluidLineHeater3 3 "not available" 2 "reserved for future assignment by SAE" 1 "request for heater to be active" 0 "request for heater to be inactive" ;
VAL_ 2566734078 AT1DieselExhaustFluidLineHeater2 3 "not available" 2 "reserved for future assignment by SAE" 1 "request for heater to be active" 0 "request for heater to be inactive" ;
VAL_ 2566734078 AT1DieselExhaustFluidLineHeater1 3 "not available" 2 "reserved for future assignment by SAE" 1 "request for heater to be active" 0 "request for heater to be inactive" ;
VAL_ 2566734078 AT1DslExhstFldDoserHeatingModeRq 7 "Not available" 3 "Heater on" 2 "Heater automatic mode" 1 "Heater economy mode" 0 "Heater off" ;
VAL_ 2566734078 AT1DslExhstFldDsrFltSppressionRq 3 "Not available" 2 "Reserved" 1 "Error suppression on" 0 "Error suppression off" ;
VAL_ 2364548350 AT1DslExhstFldDsngTstInjctnPrmss 3 "not available" 2 "error" 1 "DEF dosing test injection allowed" 0 "not allowed" ;
VAL_ 2364548350 AT1DslExhstFldHydStffnssChckPrms 3 "not available" 2 "error" 1 "DEF hydraulic stiffness check allowed" 0 "not allowed" ;
VAL_ 2364548350 AT1SCRSystemRequestedState 15 "Not available" 14 "Error" 10 "Service test mode dosing not allowed" 9 "Service test mode dosing allowed" 8 "Diagnosis afterrun" 7 "Shutoff wait for afterrun" 6 "Protect mode against cold defreeze" 5 "Protect mode against heat pressure buildup" 4 "Reserved for future assignment by SAE" 3 "System error pending" 2 "Normal dosing operation" 1 "Preparing dosing readiness wake up prepare to operate wait for start" 0 "Dormant sleep mode" ;
VAL_ 2566734334 AT1DslExhstFluidLineHeater4State 3 "not available" 2 "error" 1 "heater active" 0 "heater inactive" ;
VAL_ 2566734334 AT1DslExhstFluidLineHeater3State 3 "not available" 2 "error" 1 "heater active" 0 "heater inactive" ;
VAL_ 2566734334 AT1DslExhstFluidLineHeater2State 3 "not available" 2 "error" 1 "heater active" 0 "heater inactive" ;
VAL_ 2566734334 AT1DslExhstFluidLineHeater1State 3 "not available" 2 "error" 1 "heater active" 0 "heater inactive" ;
VAL_ 2566734334 AT1SCRFeedbackCtrlStatus 7 "not available" 4 "reserved for future assignment by SAE" 3 "reserved for future assignment by SAE" 2 "reserved for future assignment by SAE" 6 "error" 5 "reserved for future assignment by SAE" 1 "closed loop control active" 0 "open loop control active" ;
VAL_ 2566734334 AT1SCRDsngVlvExhstTmpReductionRq 7 "not available" 6 "error" 5 "reserved for future assignment by SAE" 4 "reserved for future assignment by SAE" 3 "reserved for future assignment by SAE" 2 "reduction request stage 2" 1 "reduction request stage 1" 0 "no request" ;
VAL_ 2364548094 AT1SCRSystem2State 15 "Not available" 14 "Error" 11 "Ok to Power Down (SCR dosing system has complete housekeeping and power may safely be removed.)" 10 "Service test mode, dosing not allowed" 9 "Service test mode, dosing allowed" 8 "Diagnosis (after-run)" 7 "Shutoff (wait for after-run)" 6 "Protect mode against cold (defreeze)" 5 "Protect mode against heat (pressure buildup)" 4 "Purging (SCR dosing system is removing residual DEF from system prior to shutdown)" 3 "System error pending" 2 "Normal dosing operation" 1 "Preparing dosing readiness (wake up; prepare to operate; wait for start)" 0 "Dormant (sleep mode)" ;
VAL_ 2364548094 AT1SCRSystem1State 15 "Not available" 14 "Error" 11 "Ok to Power Down (SCR dosing system has complete housekeeping and power may safely be removed.)" 10 "Service test mode, dosing not allowed" 9 "Service test mode, dosing allowed " 8 "Diagnosis (after-run)" 7 "Shutoff  (wait for after-run)" 6 "Protect mode against cold  (defreeze)" 5 "Protect mode against heat  (pressure buildup)" 4 "Purging (SCR dosing system is removing residual DEF from system prior to shutdown)" 3 "System error pending" 2 "Normal dosing operation" 1 "Preparing dosing readiness (wake up; prepare to operate; wait for start)" 0 "Dormant (sleep mode)" ;
VAL_ 2364548606 AT1OutletNH3GasSensorHeaterCtrl 3 "Heater off or not available" 2 "Preheat 1" 1 "Preheat 2" 0 "Automatic" ;
VAL_ 2364548606 AT1OutletNH3GasSensorAtTemp 3 "Not available" 2 "Error" 1 "Heater element is in range" 0 "Heater element is not in range" ;
VAL_ 2364548606 AT1OtletNH3GasSensorPowerInRange 3 "Not available" 2 "Error" 1 "Power is in range" 0 "Power is not in range" ;
VAL_ 2364548606 AT1OutletNH3ReadingStable 3 "Not available" 2 "Error" 1 "Reading is stable" 0 "Reading is not stable" ;
VAL_ 2365415678 FailureModeIdentifier1 31 "Not available" 19 "Received network data in error" 18 "Below normal (moderately severe)" 17 "Below normal (least severe)" 16 "Above normal (moderately severe)" 15 "Above normal (least severe)" 14 "Special intstructions" 13 "Out of calibration" 12 "Bad intelligent device" 11 "Root cause not known" 10 "Abnormal rate of change" 9 "Abnormal update rate" 8 "Abnormal frequency" 7 "Mechanical system not responding" 6 "Current above normal" 5 "Current below normal" 4 "Voltage below normal" 3 "Voltage above normal" 2 "Data erratic" 1 "Below normal (most severe)" 0 "Above normal (most severe)" ;
VAL_ 2359361278 PMNTEDeficiencyAreaStatus 3 "NotAvailable" 2 "Reserved" 1 "InsideControlArea" 0 "OutsideControlArea" ;
VAL_ 2359361278 MnfcPMNTECarveOutAreaStatus 3 "NotAvailable" 2 "Reserved" 1 "InsideControlArea" 0 "OutsideControlArea" ;
VAL_ 2359361278 PMNTEControlAreaStatus 3 "NotAvailable" 2 "Reserved" 1 "InsideControlArea" 0 "OutsideControlArea" ;
VAL_ 2359361278 NOxNTEDeficiencyAreaStatus 3 "NotAvailable" 2 "Reserved" 1 "InsideControlArea" 0 "OutsideControlArea" ;
VAL_ 2359361278 MnfcNOxNTECarveOutAreaStatus 3 "NotAvailable" 2 "Reserved" 1 "InsideControlArea" 0 "OutsideControlArea" ;
VAL_ 2359361278 NOxNTEControlAreaStatus 3 "NotAvailable" 2 "Reserved" 1 "InsideControlArea" 0 "OutsideControlArea" ;
VAL_ 2566809342 BatteryMainSwitchHoldState 3 "Dont care/take no action" 2 "Reserved" 1 "Battery main switch held" 0 "Battery main switch not held" ;
VAL_ 2365446910 Joystick3XAxisDetentPosStatus 3 "Not Available" 2 "Error Indicator" 1 "In the Detent Position" 0 "Not in the Detent Position" ;
VAL_ 2365446910 Joystick3Button9PressedStatus 3 "Not Available" 2 "Error Indicator" 1 "Button pressed" 0 "Button not pressed" ;
VAL_ 2365446910 Joystick3Button10PressedStatus 3 "Not Available" 2 "Error Indicator" 1 "Button pressed" 0 "Button not pressed" ;
VAL_ 2365446910 Joystick3Button11PressedStatus 3 "Not Available" 2 "Error Indicator" 1 "Button pressed" 0 "Button not pressed" ;
VAL_ 2365446910 Joystick3Button12PressedStatus 3 "Not Available" 2 "Error Indicator" 1 "Button pressed" 0 "Button not pressed" ;
VAL_ 2365446910 Joystick3YAxisDetentPosStatus 3 "Not Available" 2 "Error Indicator" 1 "In the Detent Position" 0 "Not in the Detent Position" ;
VAL_ 2365446910 Jystck3YAxsLvrFrwrdPstvPosStatus 3 "Not Available" 2 "Error Indicator" 1 "On positive side of Neutral" 0 "Not on Positive side of Neutral" ;
VAL_ 2365446910 Jystck3YAxsLvrBckNgtivePosStatus 3 "Not Available" 2 "Error Indicator" 1 "On negative side of Neutral" 0 "Not on negative side of Neutral" ;
VAL_ 2365446910 Joystick3YAxisNeutralPosStatus 3 "Not Available" 2 "Error Indicator" 1 "In Neutral Position" 0 "Not in Neutral Position" ;
VAL_ 2365446910 Jystck3XAxsLvrRghtPstvePosStatus 3 "Not Available" 2 "Error Indicator" 1 "On positive side of Neutral" 0 "Not on Positive side of Neutral" ;
VAL_ 2365446910 Jystck3XAxsLvrLftNgtivePosStatus 3 "Not Available" 2 "Error Indicator" 1 "On negative side of Neutral" 0 "Not on negative side of Neutral" ;
VAL_ 2365446910 Joystick3XAxisNeutralPosStatus 3 "Not Available" 2 "Error Indicator" 1 "In Neutral Position" 0 "Not in Neutral Position" ;
VAL_ 2365446910 Joystick3Button5PressedStatus 3 "Not Available" 2 "Error Indicator" 1 "Button pressed" 0 "Button not pressed" ;
VAL_ 2365446910 Joystick3Button6PressedStatus 3 "Not Available" 2 "Error Indicator" 1 "Button pressed" 0 "Button not pressed" ;
VAL_ 2365446910 Joystick3Button7PressedStatus 3 "Not Available" 2 "Error Indicator" 1 "Button pressed" 0 "Button not pressed" ;
VAL_ 2365446910 Joystick3Button8PressedStatus 3 "Not Available" 2 "Error Indicator" 1 "Button pressed" 0 "Button not pressed" ;
VAL_ 2365446910 Joystick3Button1PressedStatus 3 "Not Available" 2 "Error Indicator" 1 "Button pressed" 0 "Button not pressed" ;
VAL_ 2365446910 Joystick3Button2PressedStatus 3 "Not Available" 2 "Error Indicator" 1 "Button pressed" 0 "Button not pressed" ;
VAL_ 2365446910 Joystick3Button3PressedStatus 3 "Not Available" 2 "Error Indicator" 1 "Button pressed" 0 "Button not pressed" ;
VAL_ 2365446910 Joystick3Button4PressedStatus 3 "Not Available" 2 "Error Indicator" 1 "Button pressed" 0 "Button not pressed" ;
VAL_ 2365446398 Joystick2XAxisDetentPosStatus 3 "Not Available" 2 "Error Indicator" 1 "In the Detent Position" 0 "Not in the Detent Position" ;
VAL_ 2365446398 Joystick2YAxisDetentPosStatus 3 "Not Available" 2 "Error Indicator" 1 "In the Detent Position" 0 "Not in the Detent Position" ;
VAL_ 2365446398 Jystck2YAxsLvrFrwrdPstvPosStatus 3 "Not Available" 2 "Error Indicator" 1 "On positive side of Neutral" 0 "Not on Positive side of Neutral" ;
VAL_ 2365446398 Jystck2YAxsLvrBckNgtivePosStatus 3 "Not Available" 2 "Error Indicator" 1 "On negative side of Neutral" 0 "Not on negative side of Neutral" ;
VAL_ 2365446398 Joystick2YAxisNeutralPosStatus 3 "Not Available" 2 "Error Indicator" 1 "In Neutral Position" 0 "Not in Neutral Position" ;
VAL_ 2365446398 Jystck2XAxsLvrRghtPstvePosStatus 3 "Not Available" 2 "Error Indicator" 1 "On positive side of Neutral" 0 "Not on Positive side of Neutral" ;
VAL_ 2365446398 Jystck2XAxsLvrLftNgtivePosStatus 3 "Not Available" 2 "Error Indicator" 1 "On negative side of Neutral" 0 "Not on negative side of Neutral" ;
VAL_ 2365446398 Joystick2XAxisNeutralPosStatus 3 "Not Available" 2 "Error Indicator" 1 "In Neutral Position" 0 "Not in Neutral Position" ;
VAL_ 2365446398 Joystick2Button9PressedStatus 3 "Not Available" 2 "Error Indicator" 1 "Button pressed" 0 "Button not pressed" ;
VAL_ 2365446398 Joystick2Button10PressedStatus 3 "Not Available" 2 "Error Indicator" 1 "Button pressed" 0 "Button not pressed" ;
VAL_ 2365446398 Joystick2Button11PressedStatus 3 "Not Available" 2 "Error Indicator" 1 "Button pressed" 0 "Button not pressed" ;
VAL_ 2365446398 Joystick2Button12PressedStatus 3 "Not Available" 2 "Error Indicator" 1 "Button pressed" 0 "Button not pressed" ;
VAL_ 2365446398 Joystick2Button5PressedStatus 3 "Not Available" 2 "Error Indicator" 1 "Button pressed" 0 "Button not pressed" ;
VAL_ 2365446398 Joystick2Button6PressedStatus 3 "Not Available" 2 "Error Indicator" 1 "Button pressed" 0 "Button not pressed" ;
VAL_ 2365446398 Joystick2Button7PressedStatus 3 "Not Available" 2 "Error Indicator" 1 "Button pressed" 0 "Button not pressed" ;
VAL_ 2365446398 Joystick2Button8PressedStatus 3 "Not Available" 2 "Error Indicator" 1 "Button pressed" 0 "Button not pressed" ;
VAL_ 2365446398 Joystick2Button1PressedStatus 3 "Not Available" 2 "Error Indicator" 1 "Button pressed" 0 "Button not pressed" ;
VAL_ 2365446398 Joystick2Button2PressedStatus 3 "Not Available" 2 "Error Indicator" 1 "Button pressed" 0 "Button not pressed" ;
VAL_ 2365446398 Joystick2Button3PressedStatus 3 "Not Available" 2 "Error Indicator" 1 "Button pressed" 0 "Button not pressed" ;
VAL_ 2365446398 Joystick2Button4PressedStatus 3 "Not Available" 2 "Error Indicator" 1 "Button pressed" 0 "Button not pressed" ;
VAL_ 2365445886 Joystick1XAxisDetentPosStatus 3 "Not Available" 2 "Error Indicator" 1 "In the Detent Position" 0 "Not in the Detent Position" ;
VAL_ 2365445886 Joystick1YAxisDetentPosStatus 3 "Not Available" 2 "Error Indicator" 1 "In the Detent Position" 0 "Not in the Detent Position" ;
VAL_ 2365445886 Jystck1YAxsLvrFrwrdPstvPosStatus 3 "Not Available" 2 "Error Indicator" 1 "On positive side of Neutral" 0 "Not on Positive side of Neutral" ;
VAL_ 2365445886 Jystck1YAxsLvrBckNgtivePosStatus 3 "Not Available" 2 "Error Indicator" 1 "On negative side of Neutral" 0 "Not on negative side of Neutral" ;
VAL_ 2365445886 Joystick1YAxisNeutralPosStatus 3 "Not Available" 2 "Error Indicator" 1 "In Neutral Position" 0 "Not in Neutral Position" ;
VAL_ 2365445886 Joystick1Button9PressedStatus 3 "Not Available" 2 "Error Indicator" 1 "Button pressed" 0 "Button not pressed" ;
VAL_ 2365445886 Joystick1Button10PressedStatus 3 "Not Available" 2 "Error Indicator" 1 "Button pressed" 0 "Button not pressed" ;
VAL_ 2365445886 Joystick1Button11PressedStatus 3 "Not Available" 2 "Error Indicator" 1 "Button pressed" 0 "Button not pressed" ;
VAL_ 2365445886 Joystick1Button12PressedStatus 3 "Not Available" 2 "Error Indicator" 1 "Button pressed" 0 "Button not pressed" ;
VAL_ 2365445886 Joystick1Button5PressedStatus 3 "Not Available" 2 "Error Indicator" 1 "Button pressed" 0 "Button not pressed" ;
VAL_ 2365445886 Joystick1Button6PressedStatus 3 "Not Available" 2 "Error Indicator" 1 "Button pressed" 0 "Button not pressed" ;
VAL_ 2365445886 Joystick1Button7PressedStatus 3 "Not Available" 2 "Error Indicator" 1 "Button pressed" 0 "Button not pressed" ;
VAL_ 2365445886 Joystick1Button8PressedStatus 3 "Not Available" 2 "Error Indicator" 1 "Button pressed" 0 "Button not pressed" ;
VAL_ 2365445886 Joystick1Button1PressedStatus 3 "Not Available" 2 "Error Indicator" 1 "Button pressed" 0 "Button not pressed" ;
VAL_ 2365445886 Joystick1Button2PressedStatus 3 "Not Available" 2 "Error Indicator" 1 "Button pressed" 0 "Button not pressed" ;
VAL_ 2365445886 Joystick1Button3PressedStatus 3 "Not Available" 2 "Error Indicator" 1 "Button pressed" 0 "Button not pressed" ;
VAL_ 2365445886 Joystick1Button4PressedStatus 3 "Not Available" 2 "Error Indicator" 1 "Button pressed" 0 "Button not pressed" ;
VAL_ 2365445886 Jystck1XAxsLvrRghtPstvePosStatus 3 "Not Available" 2 "Error Indicator" 1 "On positive side of Neutral" 0 "Not on Positive side of Neutral" ;
VAL_ 2365445886 Jystck1XAxsLvrLftNgtivePosStatus 3 "Not Available" 2 "Error Indicator" 1 "On negative side of Neutral" 0 "Not on negative side of Neutral" ;
VAL_ 2365445886 Joystick1XAxisNeutralPosStatus 3 "Not Available" 2 "Error Indicator" 1 "In Neutral Position" 0 "Not in Neutral Position" ;
VAL_ 2566847230 ParkingBrakeRedWarningSignal 3 "Take no action" 2 "Reserved" 1 "on" 0 "off" ;
VAL_ 2566847230 ParkBrakeReleaseInhibitStatus 3 "Unavailable" 2 "Error" 1 "ParkBrakeReleaseIsInhibited" 0 "ParkBrakeReleaseIsNotInhibited" ;
VAL_ 2566847230 ParkingBrakeActuator 3 "Not available" 2 "Error" 1 "Parking brake actuator active" 0 "Parking brake actuator inactive" ;
VAL_ 2359557886 DTCWarnLampSupportStatus 3 "Unavailable" 2 "Reserved" 1 "LampOn" 0 "LampOff" ;
VAL_ 2359557886 DTCWarnLampSupportFlash 3 "Unavailable" 2 "Reserved" 1 "FastFlash" 0 "SlowFlash" ;
VAL_ 2359557886 DTCStopLampSupportStatus 3 "Unavailable" 2 "Reserved" 1 "LampOn" 0 "LampOff" ;
VAL_ 2359557886 DTCStopLampSupportFlash 3 "Unavailable" 2 "Reserved" 1 "FastFlash" 0 "SlowFlash" ;
VAL_ 2359557886 DTCProtectLampSupportStatus 3 "Unavailable" 2 "Reserved" 1 "LampOn" 0 "LampOff" ;
VAL_ 2359557886 DTCProtectLampSupportFlash 3 "Unavailable" 2 "Reserved" 1 "FastFlash" 0 "SlowFlash" ;
VAL_ 2359557886 DTCMilSupportStatus 3 "Unavailable" 2 "ShortMI" 1 "LampOn" 0 "LampOff" ;
VAL_ 2359557886 DTCMilSupportFlash 3 "Unavailable" 2 "Class_C_DTC" 1 "FastFlash" 0 "SlowFlash" ;
VAL_ 2566736126 EngExhstGsOxygnSnsrClsdLpOprtnBn 15 "not supported" 4 "Closed loop but fault with at least one oxygen sensor  may be using single oxygen sensor for fuel control" 3 "Open loop  due to detected system fault" 2 "Open loop due to driving conditions eg power enrichment deceleration enleanment" 1 "Closed loop  using oxygen sensors as feedback for fuel control" 0 "Open loop  has not yet satisfied conditions to go closed loop" ;
VAL_ 2566736382 EngExhstGsOxygnSnsrClsdLpOprtnBn 15 "not supported" 4 "Closed loop but fault with at least one oxygen sensor  may be using single oxygen sensor for fuel control" 3 "Open loop  due to detected system fault" 2 "Open loop due to driving conditions eg power enrichment deceleration enleanment" 1 "Closed loop  using oxygen sensors as feedback for fuel control" 0 "Open loop  has not yet satisfied conditions to go closed loop" ;
